VERSION ""

NS_ :

BS_:

BU_: IVI GTW IC HUD DVR WCM PDC VSP SVC TBOX_INFO SVM

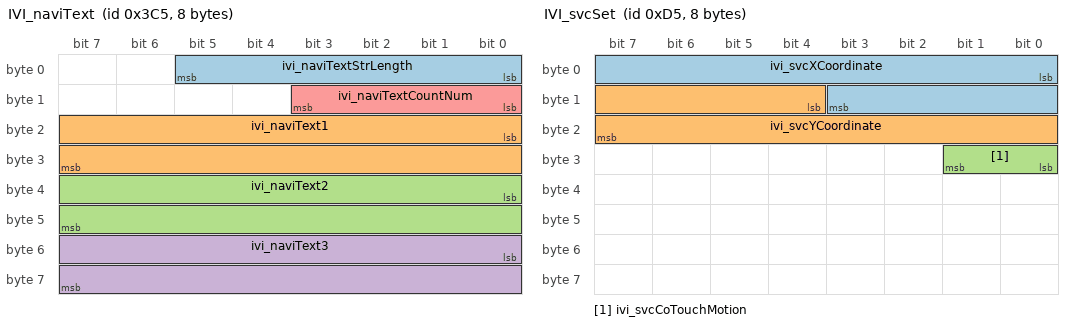
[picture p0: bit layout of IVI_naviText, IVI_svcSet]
BO_ 965 IVI_naviText: 8 IVI
 SG_ ivi_naviTextStrLength : 0|6@1+ (1,0) [0|63] ""  IC,HUD
 SG_ ivi_naviText1 : 16|16@1+ (1,0) [0|65535] ""  IC,HUD
 SG_ ivi_naviText2 : 32|16@1+ (1,0) [0|65535] ""  IC,HUD
 SG_ ivi_naviText3 : 48|16@1+ (1,0) [0|65535] ""  IC,HUD
 SG_ ivi_naviTextCountNum : 8|4@1+ (1,0) [0|15] ""  IC,HUD

BO_ 165 IVI_pwrSet: 8 IVI
 SG_ ivi_driveModeSet : 0|2@1+ (1,0) [0|3] ""  GTW
 SG_ ivi_travelModeSet : 13|3@1+ (1,0) [0|7] ""  GTW
 SG_ ivi_maxChrgSocSet : 16|8@1+ (0.5,0) [0|100] "%"  GTW
 SG_ ivi_4wdModeSet : 2|2@1+ (1,0) [0|3] ""  GTW
 SG_ ivi_cancelChargeSet : 24|2@1+ (1,0) [0|3] ""  GTW
 SG_ ivi_chargeFormSet : 26|3@1+ (1,0) [0|7] ""  GTW
 SG_ ivi_engyRcvrOnOffSet : 29|2@1+ (1,0) [0|3] ""  GTW
 SG_ ivi_engyRcvrIntensitySet : 32|2@1+ (1,0) [0|3] ""  GTW
 SG_ ivi_tractionModeSet : 34|1@1+ (1,0) [0|1] ""  GTW
 SG_ ivi_dcdcAutochargeSet : 35|1@1+ (1,0) [0|1] ""  GTW
 SG_ ivi_ASCHeightModeSelected : 36|3@1+ (1,0) [0|7] ""  GTW
 SG_ ivi_ASCSpeedChangeEnableSwitch : 39|1@1+ (1,0) [0|1] ""  GTW
 SG_ ivi_crawlModeSet : 4|2@1+ (1,0) [0|3] ""  GTW
 SG_ ivi_ASCSpeedThresholdValueChange : 40|8@1+ (1,0) [0|255] ""  GTW
 SG_ ivi_esc_epbButtonRelease : 48|1@1+ (1,0) [0|1] ""  GTW
 SG_ ivi_ASCMoveModeControl : 49|2@1+ (1,0) [0|3] ""  GTW
 SG_ ivi_enableCreepTorque : 51|1@1+ (1,0) [0|1] ""  GTW
 SG_ ivi_chargeModeSet : 6|2@1+ (1,0) [0|3] ""  GTW
 SG_ ivi_maxChargeCurrentSet : 8|5@1+ (1,5) [5|26] "A"  GTW

BO_ 245 IVI_scuSet: 8 IVI
 SG_ ivi_easyEntrySet : 0|2@1+ (1,0) [0|3] ""  GTW
 SG_ ivi_drSeatVentLevelSet : 11|3@1+ (1,0) [0|7] ""  GTW
 SG_ ivi_passSeatHeatOnOffSet : 14|2@1+ (1,0) [0|3] ""  GTW
 SG_ ivi_passSeatVentOnOffSet : 16|2@1+ (1,0) [0|3] ""  GTW
 SG_ ivi_passSeatHeatLevelSet : 18|3@1+ (1,0) [0|7] ""  GTW
 SG_ ivi_drSeatHeatOnOffSet : 2|2@1+ (1,0) [0|3] ""  GTW
 SG_ ivi_passSeatVentLevelSet : 21|3@1+ (1,0) [0|7] ""  GTW
 SG_ ivi_passSeatMassOnOffSet : 24|2@1+ (1,0) [0|3] ""  GTW
 SG_ ivi_drSeatMassLevelSet : 26|3@1+ (1,0) [0|7] ""  GTW
 SG_ ivi_passSeatMassLevelSet : 29|3@1+ (1,0) [0|7] ""  GTW
 SG_ ivi_mirrorSet : 32|2@1+ (1,0) [0|3] ""  GTW
 SG_ ivi_memorySet : 34|2@1+ (1,0) [0|3] ""  GTW
 SG_ ivi_memoryNumSet : 36|2@1+ (1,0) [0|3] ""  GTW
 SG_ ivi_drSeatVentOnOffSet : 4|2@1+ (1,0) [0|3] ""  GTW
 SG_ ivi_dsmSetMemoryReq : 40|3@1+ (1,0) [0|7] ""  GTW
 SG_ ivi_dsmGetMemoryReq : 43|3@1+ (1,0) [0|7] ""  GTW
 SG_ ivi_drSeatMassOnOffSet : 6|2@1+ (1,0) [0|3] ""  GTW
 SG_ ivi_drSeatHeatLevelSet : 8|3@1+ (1,0) [0|7] ""  GTW

BO_ 949 IVI_set: 8 IVI
 SG_ ivi_hvacDefrostMode : 0|1@1+ (1,0) [0|1] ""  GTW
 SG_ ivi_hvacOnOffReq : 1|1@1+ (1,0) [0|1] ""  GTW
 SG_ ivi_passengerTempFSet : 10|6@1+ (0.5,64) [64|89] "℉"  GTW
 SG_ ivi_hvacModeReq : 16|3@1+ (1,0) [0|7] ""  GTW
 SG_ ivi_driverTempCSet : 19|5@1+ (0.5,18) [18|32] "degreeC"  GTW
 SG_ ivi_driverTempFSet : 2|6@1+ (0.5,64) [64|89] "℉"  GTW
 SG_ ivi_hvacBlowLvReq : 24|3@1+ (1,0) [0|7] ""  GTW
 SG_ ivi_passengerTempCSet : 27|5@1+ (0.5,18) [18|32] "degreeC"  GTW
 SG_ ivi_hvacDualMode : 32|1@1+ (1,0) [0|1] ""  GTW
 SG_ ivi_hvacPTCReq : 33|1@1+ (1,0) [0|1] ""  GTW
 SG_ ivi_acReq : 34|1@1+ (1,0) [0|1] ""  GTW
 SG_ ivi_svcCameraModeSet : 35|4@1+ (1,0) [0|15] ""  SVC,GTW
 SG_ ivi_acDiagReq : 39|1@1+ (1,0) [0|1] ""  GTW
 SG_ ivi_svcFrontTrackDispSet : 40|1@1+ (1,0) [0|1] ""  SVC,GTW
 SG_ ivi_svcRvrsTrackDispSet : 41|1@1+ (1,0) [0|1] ""  SVC,GTW
 SG_ ivi_svcOutMirrorTrackDispSet : 42|1@1+ (1,0) [0|1] ""  SVC,GTW
 SG_ ivi_svcOnOffSw : 43|1@1+ (1,0) [0|1] ""  SVC,GTW
 SG_ ivi_svcSteerInteractionSet : 44|1@1+ (1,0) [0|1] ""  SVC,GTW
 SG_ ivi_languageSet : 48|4@1+ (1,0) [0|15] ""  IC,SVC,DVR,HUD,GTW
 SG_ ivi_unitSet : 52|2@1+ (1,0) [0|3] ""  IC,HUD,GTW
 SG_ ivi_hvacAutoModeReq : 8|1@1+ (1,0) [0|1] ""  GTW
 SG_ ivi_hvacRecircModeReq : 9|1@1+ (1,0) [0|1] ""  GTW

BO_ 229 IVI_svcCalib: 8 IVI
 SG_ ivi_svcCalibrateStart : 0|32@1+ (1,0) [0|4294967295] ""  SVC
 SG_ ivi_svcCaliInfoReq : 32|1@1+ (1,0) [0|1] ""  SVC

BO_ 213 IVI_svcSet: 8 IVI
 SG_ ivi_svcXCoordinate : 0|12@1+ (1,0) [0|1280] ""  SVC
 SG_ ivi_svcYCoordinate : 12|12@1+ (1,0) [0|720] ""  SVC
 SG_ ivi_svcCoTouchMotion : 24|2@1+ (1,0) [0|3] ""  SVC

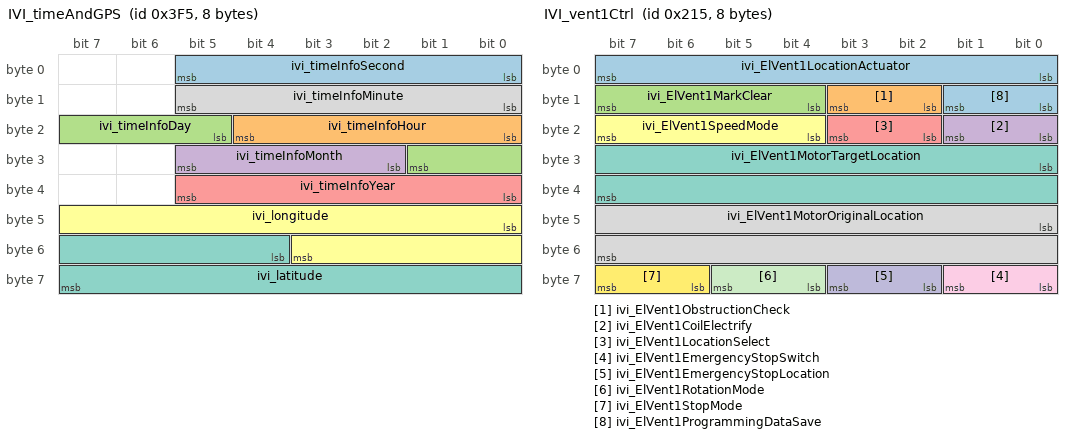
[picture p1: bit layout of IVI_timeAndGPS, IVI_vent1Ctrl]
BO_ 1013 IVI_timeAndGPS: 8 IVI
 SG_ ivi_timeInfoSecond : 0|6@1+ (1,0) [0|59] ""  IC,SVC,DVR
 SG_ ivi_timeInfoHour : 16|5@1+ (1,0) [0|23] ""  IC,SVC,DVR
 SG_ ivi_timeInfoDay : 21|5@1+ (1,0) [1|31] ""  IC,SVC,DVR
 SG_ ivi_timeInfoMonth : 26|4@1+ (1,0) [1|12] ""  IC,SVC,DVR
 SG_ ivi_timeInfoYear : 32|6@1+ (1,0) [0|59] ""  IC,SVC,DVR
 SG_ ivi_longitude : 40|12@1+ (0.1,-180) [-180|180] "degree"  DVR
 SG_ ivi_latitude : 52|12@1+ (0.1,-180) [-180|180] "degree"  DVR
 SG_ ivi_timeInfoMinute : 8|6@1+ (1,0) [0|59] ""  IC,SVC,DVR

BO_ 533 IVI_vent1Ctrl: 8 IVI
 SG_ ivi_ElVent1LocationActuator : 0|8@1+ (1,0) [0|255] ""  GTW
 SG_ ivi_ElVent1ObstructionCheck : 10|2@1+ (1,0) [0|3] ""  GTW
 SG_ ivi_ElVent1MarkClear : 12|4@1+ (1,0) [0|15] ""  GTW
 SG_ ivi_ElVent1CoilElectrify : 16|2@1+ (1,0) [0|3] ""  GTW
 SG_ ivi_ElVent1LocationSelect : 18|2@1+ (1,0) [0|3] ""  GTW
 SG_ ivi_ElVent1SpeedMode : 20|4@1+ (1,0) [0|15] ""  GTW
 SG_ ivi_ElVent1MotorTargetLocation : 24|16@1+ (1,0) [0|65535] ""  GTW
 SG_ ivi_ElVent1MotorOriginalLocation : 40|16@1+ (1,0) [0|65535] ""  GTW
 SG_ ivi_ElVent1EmergencyStopSwitch : 56|2@1+ (1,0) [0|3] ""  GTW
 SG_ ivi_ElVent1EmergencyStopLocation : 58|2@1+ (1,0) [0|3] ""  GTW
 SG_ ivi_ElVent1RotationMode : 60|2@1+ (1,0) [0|3] ""  GTW
 SG_ ivi_ElVent1StopMode : 62|2@1+ (1,0) [0|3] ""  GTW
 SG_ ivi_ElVent1ProgrammingDataSave : 8|2@1+ (1,0) [0|3] ""  GTW

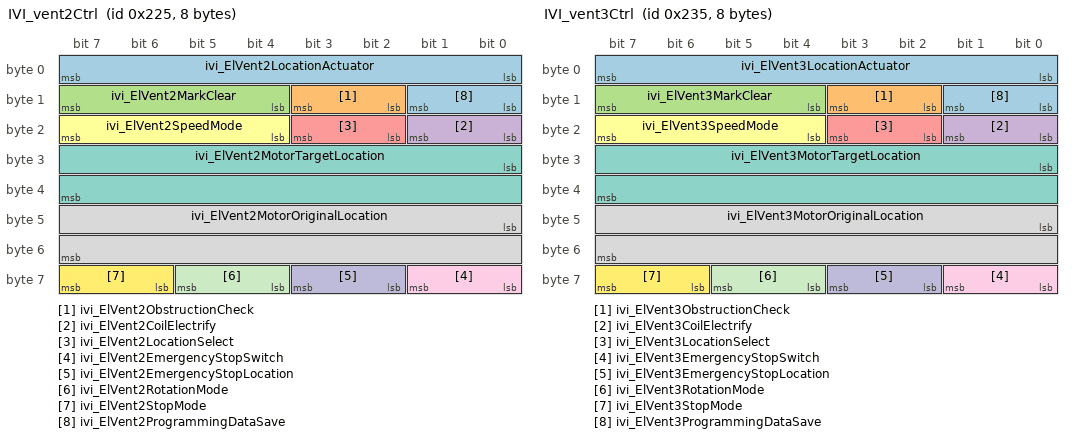
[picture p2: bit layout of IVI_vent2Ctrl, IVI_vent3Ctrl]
BO_ 549 IVI_vent2Ctrl: 8 IVI
 SG_ ivi_ElVent2LocationActuator : 0|8@1+ (1,0) [0|255] ""  GTW
 SG_ ivi_ElVent2ObstructionCheck : 10|2@1+ (1,0) [0|3] ""  GTW
 SG_ ivi_ElVent2MarkClear : 12|4@1+ (1,0) [0|15] ""  GTW
 SG_ ivi_ElVent2CoilElectrify : 16|2@1+ (1,0) [0|3] ""  GTW
 SG_ ivi_ElVent2LocationSelect : 18|2@1+ (1,0) [0|3] ""  GTW
 SG_ ivi_ElVent2SpeedMode : 20|4@1+ (1,0) [0|15] ""  GTW
 SG_ ivi_ElVent2MotorTargetLocation : 24|16@1+ (1,0) [0|65535] ""  GTW
 SG_ ivi_ElVent2MotorOriginalLocation : 40|16@1+ (1,0) [0|65535] ""  GTW
 SG_ ivi_ElVent2EmergencyStopSwitch : 56|2@1+ (1,0) [0|3] ""  GTW
 SG_ ivi_ElVent2EmergencyStopLocation : 58|2@1+ (1,0) [0|3] ""  GTW
 SG_ ivi_ElVent2RotationMode : 60|2@1+ (1,0) [0|3] ""  GTW
 SG_ ivi_ElVent2StopMode : 62|2@1+ (1,0) [0|3] ""  GTW
 SG_ ivi_ElVent2ProgrammingDataSave : 8|2@1+ (1,0) [0|3] ""  GTW

BO_ 565 IVI_vent3Ctrl: 8 IVI
 SG_ ivi_ElVent3LocationActuator : 0|8@1+ (1,0) [0|255] ""  GTW
 SG_ ivi_ElVent3ObstructionCheck : 10|2@1+ (1,0) [0|3] ""  GTW
 SG_ ivi_ElVent3MarkClear : 12|4@1+ (1,0) [0|15] ""  GTW
 SG_ ivi_ElVent3CoilElectrify : 16|2@1+ (1,0) [0|3] ""  GTW
 SG_ ivi_ElVent3LocationSelect : 18|2@1+ (1,0) [0|3] ""  GTW
 SG_ ivi_ElVent3SpeedMode : 20|4@1+ (1,0) [0|15] ""  GTW
 SG_ ivi_ElVent3MotorTargetLocation : 24|16@1+ (1,0) [0|65535] ""  GTW
 SG_ ivi_ElVent3MotorOriginalLocation : 40|16@1+ (1,0) [0|65535] ""  GTW
 SG_ ivi_ElVent3EmergencyStopSwitch : 56|2@1+ (1,0) [0|3] ""  GTW
 SG_ ivi_ElVent3EmergencyStopLocation : 58|2@1+ (1,0) [0|3] ""  GTW
 SG_ ivi_ElVent3RotationMode : 60|2@1+ (1,0) [0|3] ""  GTW
 SG_ ivi_ElVent3StopMode : 62|2@1+ (1,0) [0|3] ""  GTW
 SG_ ivi_ElVent3ProgrammingDataSave : 8|2@1+ (1,0) [0|3] ""  GTW

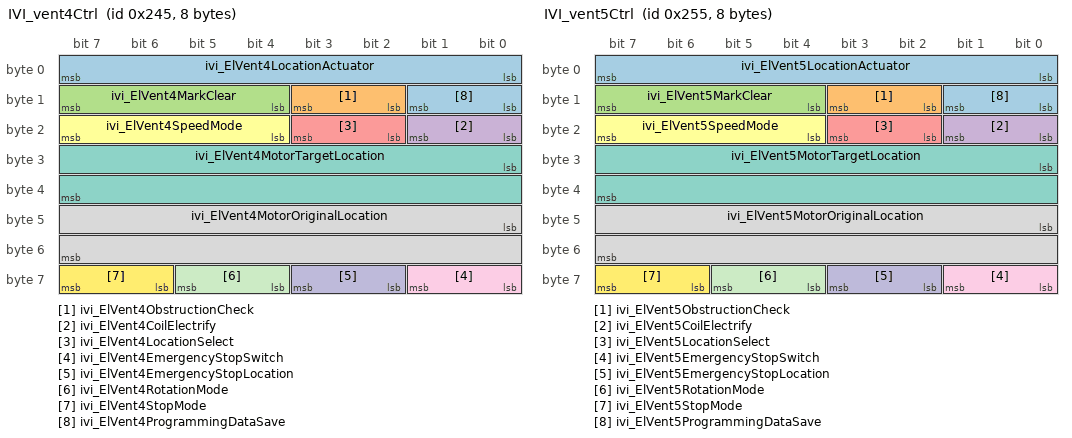
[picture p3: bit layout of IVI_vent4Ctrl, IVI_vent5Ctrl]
BO_ 581 IVI_vent4Ctrl: 8 IVI
 SG_ ivi_ElVent4LocationActuator : 0|8@1+ (1,0) [0|255] ""  GTW
 SG_ ivi_ElVent4ObstructionCheck : 10|2@1+ (1,0) [0|3] ""  GTW
 SG_ ivi_ElVent4MarkClear : 12|4@1+ (1,0) [0|15] ""  GTW
 SG_ ivi_ElVent4CoilElectrify : 16|2@1+ (1,0) [0|3] ""  GTW
 SG_ ivi_ElVent4LocationSelect : 18|2@1+ (1,0) [0|3] ""  GTW
 SG_ ivi_ElVent4SpeedMode : 20|4@1+ (1,0) [0|15] ""  GTW
 SG_ ivi_ElVent4MotorTargetLocation : 24|16@1+ (1,0) [0|65535] ""  GTW
 SG_ ivi_ElVent4MotorOriginalLocation : 40|16@1+ (1,0) [0|65535] ""  GTW
 SG_ ivi_ElVent4EmergencyStopSwitch : 56|2@1+ (1,0) [0|3] ""  GTW
 SG_ ivi_ElVent4EmergencyStopLocation : 58|2@1+ (1,0) [0|3] ""  GTW
 SG_ ivi_ElVent4RotationMode : 60|2@1+ (1,0) [0|3] ""  GTW
 SG_ ivi_ElVent4StopMode : 62|2@1+ (1,0) [0|3] ""  GTW
 SG_ ivi_ElVent4ProgrammingDataSave : 8|2@1+ (1,0) [0|3] ""  GTW

BO_ 597 IVI_vent5Ctrl: 8 IVI
 SG_ ivi_ElVent5LocationActuator : 0|8@1+ (1,0) [0|255] ""  GTW
 SG_ ivi_ElVent5ObstructionCheck : 10|2@1+ (1,0) [0|3] ""  GTW
 SG_ ivi_ElVent5MarkClear : 12|4@1+ (1,0) [0|15] ""  GTW
 SG_ ivi_ElVent5CoilElectrify : 16|2@1+ (1,0) [0|3] ""  GTW
 SG_ ivi_ElVent5LocationSelect : 18|2@1+ (1,0) [0|3] ""  GTW
 SG_ ivi_ElVent5SpeedMode : 20|4@1+ (1,0) [0|15] ""  GTW
 SG_ ivi_ElVent5MotorTargetLocation : 24|16@1+ (1,0) [0|65535] ""  GTW
 SG_ ivi_ElVent5MotorOriginalLocation : 40|16@1+ (1,0) [0|65535] ""  GTW
 SG_ ivi_ElVent5EmergencyStopSwitch : 56|2@1+ (1,0) [0|3] ""  GTW
 SG_ ivi_ElVent5EmergencyStopLocation : 58|2@1+ (1,0) [0|3] ""  GTW
 SG_ ivi_ElVent5RotationMode : 60|2@1+ (1,0) [0|3] ""  GTW
 SG_ ivi_ElVent5StopMode : 62|2@1+ (1,0) [0|3] ""  GTW
 SG_ ivi_ElVent5ProgrammingDataSave : 8|2@1+ (1,0) [0|3] ""  GTW

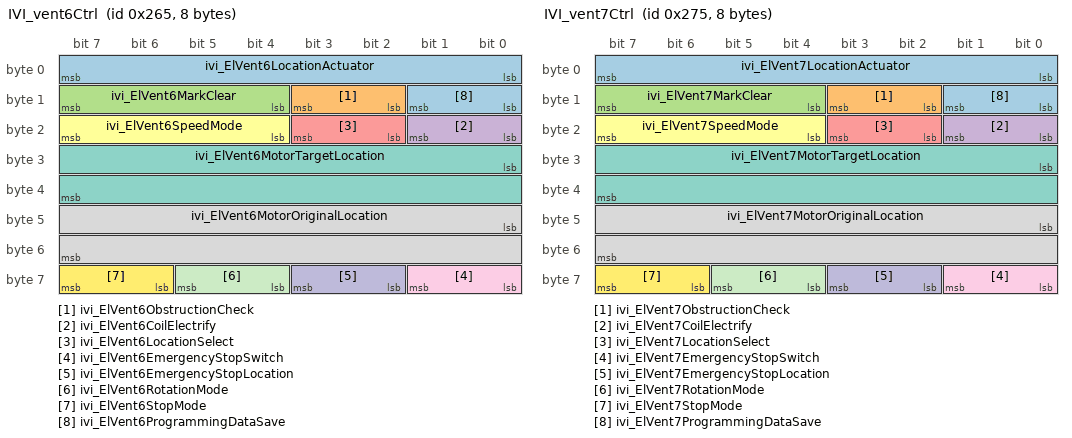
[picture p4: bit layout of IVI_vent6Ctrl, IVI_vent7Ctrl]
BO_ 613 IVI_vent6Ctrl: 8 IVI
 SG_ ivi_ElVent6LocationActuator : 0|8@1+ (1,0) [0|255] ""  GTW
 SG_ ivi_ElVent6ObstructionCheck : 10|2@1+ (1,0) [0|3] ""  GTW
 SG_ ivi_ElVent6MarkClear : 12|4@1+ (1,0) [0|15] ""  GTW
 SG_ ivi_ElVent6CoilElectrify : 16|2@1+ (1,0) [0|3] ""  GTW
 SG_ ivi_ElVent6LocationSelect : 18|2@1+ (1,0) [0|3] ""  GTW
 SG_ ivi_ElVent6SpeedMode : 20|4@1+ (1,0) [0|15] ""  GTW
 SG_ ivi_ElVent6MotorTargetLocation : 24|16@1+ (1,0) [0|65535] ""  GTW
 SG_ ivi_ElVent6MotorOriginalLocation : 40|16@1+ (1,0) [0|65535] ""  GTW
 SG_ ivi_ElVent6EmergencyStopSwitch : 56|2@1+ (1,0) [0|3] ""  GTW
 SG_ ivi_ElVent6EmergencyStopLocation : 58|2@1+ (1,0) [0|3] ""  GTW
 SG_ ivi_ElVent6RotationMode : 60|2@1+ (1,0) [0|3] ""  GTW
 SG_ ivi_ElVent6StopMode : 62|2@1+ (1,0) [0|3] ""  GTW
 SG_ ivi_ElVent6ProgrammingDataSave : 8|2@1+ (1,0) [0|3] ""  GTW

BO_ 629 IVI_vent7Ctrl: 8 IVI
 SG_ ivi_ElVent7LocationActuator : 0|8@1+ (1,0) [0|255] ""  GTW
 SG_ ivi_ElVent7ObstructionCheck : 10|2@1+ (1,0) [0|3] ""  GTW
 SG_ ivi_ElVent7MarkClear : 12|4@1+ (1,0) [0|15] ""  GTW
 SG_ ivi_ElVent7CoilElectrify : 16|2@1+ (1,0) [0|3] ""  GTW
 SG_ ivi_ElVent7LocationSelect : 18|2@1+ (1,0) [0|3] ""  GTW
 SG_ ivi_ElVent7SpeedMode : 20|4@1+ (1,0) [0|15] ""  GTW
 SG_ ivi_ElVent7MotorTargetLocation : 24|16@1+ (1,0) [0|65535] ""  GTW
 SG_ ivi_ElVent7MotorOriginalLocation : 40|16@1+ (1,0) [0|65535] ""  GTW
 SG_ ivi_ElVent7EmergencyStopSwitch : 56|2@1+ (1,0) [0|3] ""  GTW
 SG_ ivi_ElVent7EmergencyStopLocation : 58|2@1+ (1,0) [0|3] ""  GTW
 SG_ ivi_ElVent7RotationMode : 60|2@1+ (1,0) [0|3] ""  GTW
 SG_ ivi_ElVent7StopMode : 62|2@1+ (1,0) [0|3] ""  GTW
 SG_ ivi_ElVent7ProgrammingDataSave : 8|2@1+ (1,0) [0|3] ""  GTW

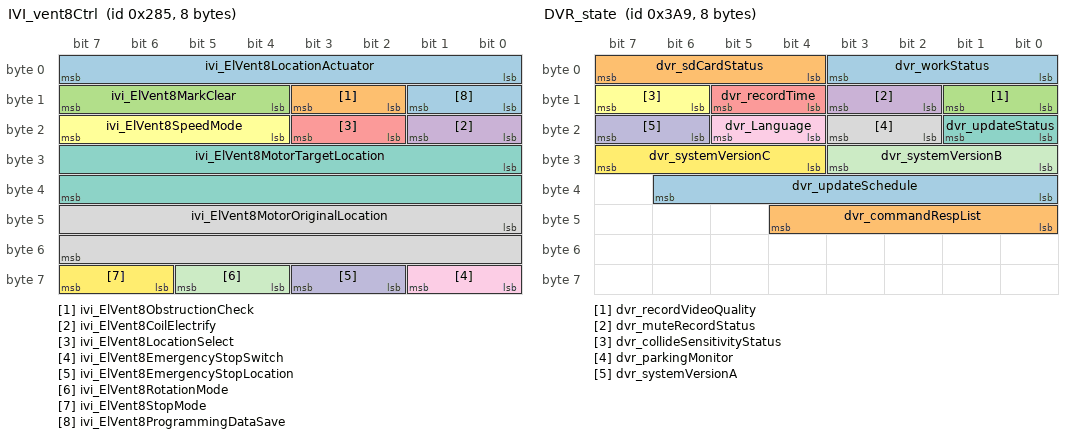
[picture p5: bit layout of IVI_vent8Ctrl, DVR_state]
BO_ 645 IVI_vent8Ctrl: 8 IVI
 SG_ ivi_ElVent8LocationActuator : 0|8@1+ (1,0) [0|255] ""  GTW
 SG_ ivi_ElVent8ObstructionCheck : 10|2@1+ (1,0) [0|3] ""  GTW
 SG_ ivi_ElVent8MarkClear : 12|4@1+ (1,0) [0|15] ""  GTW
 SG_ ivi_ElVent8CoilElectrify : 16|2@1+ (1,0) [0|3] ""  GTW
 SG_ ivi_ElVent8LocationSelect : 18|2@1+ (1,0) [0|3] ""  GTW
 SG_ ivi_ElVent8SpeedMode : 20|4@1+ (1,0) [0|15] ""  GTW
 SG_ ivi_ElVent8MotorTargetLocation : 24|16@1+ (1,0) [0|65535] ""  GTW
 SG_ ivi_ElVent8MotorOriginalLocation : 40|16@1+ (1,0) [0|65535] ""  GTW
 SG_ ivi_ElVent8EmergencyStopSwitch : 56|2@1+ (1,0) [0|3] ""  GTW
 SG_ ivi_ElVent8EmergencyStopLocation : 58|2@1+ (1,0) [0|3] ""  GTW
 SG_ ivi_ElVent8RotationMode : 60|2@1+ (1,0) [0|3] ""  GTW
 SG_ ivi_ElVent8StopMode : 62|2@1+ (1,0) [0|3] ""  GTW
 SG_ ivi_ElVent8ProgrammingDataSave : 8|2@1+ (1,0) [0|3] ""  GTW

BO_ 937 DVR_state: 8 DVR
 SG_ dvr_workStatus : 0|4@1+ (1,0) [0|15] ""  IVI
 SG_ dvr_sdCardStatus : 4|4@1+ (1,0) [0|15] ""  IVI
 SG_ dvr_recordVideoQuality : 8|2@1+ (1,0) [0|3] ""  IVI
 SG_ dvr_muteRecordStatus : 10|2@1+ (1,0) [0|3] ""  IVI
 SG_ dvr_recordTime : 12|2@1+ (1,0) [0|3] ""  IVI
 SG_ dvr_collideSensitivityStatus : 14|2@1+ (1,0) [0|3] ""  IVI
 SG_ dvr_updateStatus : 16|2@1+ (1,0) [0|3] ""  IVI
 SG_ dvr_parkingMonitor : 18|2@1+ (1,0) [0|3] ""  IVI
 SG_ dvr_Language : 20|2@1+ (1,0) [0|3] ""  IVI
 SG_ dvr_systemVersionA : 22|2@1+ (1,0) [0|3] ""  IVI
 SG_ dvr_systemVersionB : 24|4@1+ (1,0) [0|9] ""  IVI
 SG_ dvr_systemVersionC : 28|4@1+ (1,0) [0|9] ""  IVI
 SG_ dvr_updateSchedule : 32|7@1+ (1,0) [0|127] ""  IVI
 SG_ dvr_commandRespList : 40|5@1+ (1,0) [0|31] ""  IVI

BO_ 1829 Diag_PhyReq_IVI: 8 GTW
 SG_ Diag_PhyReq_IVI_Data : 0|64@1+ (1,0) [0|0] "N/A"  IVI

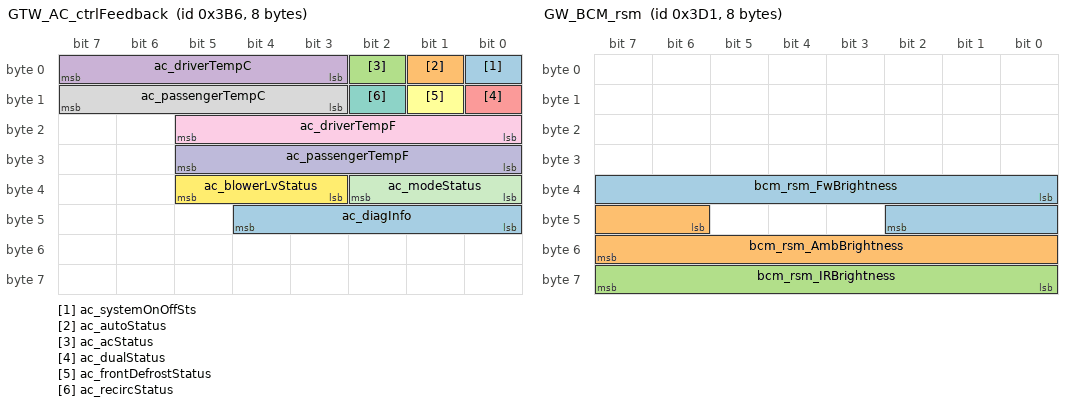
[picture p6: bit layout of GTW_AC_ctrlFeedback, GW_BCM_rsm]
BO_ 950 GTW_AC_ctrlFeedback: 8 GTW
 SG_ ac_systemOnOffSts : 0|1@1+ (1,0) [0|1] ""  IVI
 SG_ ac_autoStatus : 1|1@1+ (1,0) [0|1] ""  IVI
 SG_ ac_acStatus : 2|1@1+ (1,0) [0|1] ""  IVI
 SG_ ac_driverTempC : 3|5@1+ (0.5,18) [18|32] "degreeC"  IVI
 SG_ ac_dualStatus : 8|1@1+ (1,0) [0|1] ""  IVI
 SG_ ac_frontDefrostStatus : 9|1@1+ (1,0) [0|1] ""  IVI
 SG_ ac_recircStatus : 10|1@1+ (1,0) [0|1] ""  IVI
 SG_ ac_passengerTempC : 11|5@1+ (0.5,18) [18|32] "degreeC"  IVI
 SG_ ac_driverTempF : 16|6@1+ (0.5,64) [64|89] "℉"  IVI
 SG_ ac_passengerTempF : 24|6@1+ (0.5,64) [64|89] "℉"  IVI
 SG_ ac_modeStatus : 32|3@1+ (1,0) [0|7] ""  IVI
 SG_ ac_blowerLvStatus : 35|3@1+ (1,0) [0|7] ""  IVI
 SG_ ac_diagInfo : 40|5@1+ (1,0) [0|31] ""  IVI

BO_ 529 GTW_BCM_vent1Sts: 8 GTW
 SG_ bcm_ElVent1ErrorStatus : 0|1@1+ (1,0) [0|1] ""  IVI
 SG_ bcm_ElVent1OverHeatStatus : 2|2@1+ (1,0) [0|3] ""  IVI
 SG_ bcm_ElVent1ElectricalFailureSts : 4|2@1+ (1,0) [0|3] ""  IVI
 SG_ bcm_ElVent1VoltageStatus : 6|2@1+ (1,0) [0|3] ""  IVI
 SG_ bcm_ElVent1EmergencyRunningSts : 8|2@1+ (1,0) [0|3] ""  IVI
 SG_ bcm_ElVent1ObstructionDetect : 10|2@1+ (1,0) [0|3] ""  IVI
 SG_ bcm_ElVent1ObstructionStatus : 12|2@1+ (1,0) [0|3] ""  IVI
 SG_ bcm_ElVent1ResetStatus : 14|2@1+ (1,0) [0|3] ""  IVI
 SG_ bcm_ElVent1CoilStatus : 16|2@1+ (1,0) [0|3] ""  IVI
 SG_ bcm_ElVent1LocationStatus : 18|2@1+ (1,0) [0|3] ""  IVI
 SG_ bcm_ElVent1SpeedStatus : 20|4@1+ (1,0) [0|15] ""  IVI
 SG_ bcm_ElVent1MotorCurrentLocation : 24|16@1+ (1,0) [0|65535] ""  IVI
 SG_ bcm_ElVent1MotorDrivingDirection : 40|2@1+ (1,0) [0|3] ""  IVI
 SG_ bcm_ElVent1TorqueKeepingSts : 42|2@1+ (1,0) [0|3] ""  IVI
 SG_ bcm_ElVent1SpecialFunction : 44|2@1+ (1,0) [0|3] ""  IVI
 SG_ bcm_ElVent1LocationActuator : 48|8@1+ (1,0) [0|255] ""  IVI
 SG_ bcm_ElVent1EmengencyStopSwitchSt : 56|2@1+ (1,0) [0|3] ""  IVI
 SG_ bcm_ElVent1EmengencyStopSLocatio : 58|2@1+ (1,0) [0|3] ""  IVI
 SG_ bcm_ElVent1RotationMode : 60|2@1+ (1,0) [0|3] ""  IVI
 SG_ bcm_ElVent1StopStatus : 62|2@1+ (1,0) [0|3] ""  IVI

BO_ 545 GTW_BCM_vent2Sts: 8 GTW
 SG_ bcm_ElVent2ErrorStatus : 0|1@1+ (1,0) [0|1] ""  IVI
 SG_ bcm_ElVent2OverHeatStatus : 2|2@1+ (1,0) [0|3] ""  IVI
 SG_ bcm_ElVent2ElectricalFailureSts : 4|2@1+ (1,0) [0|3] ""  IVI
 SG_ bcm_ElVent2VoltageStatus : 6|2@1+ (1,0) [0|3] ""  IVI
 SG_ bcm_ElVent2EmergencyRunningSts : 8|2@1+ (1,0) [0|3] ""  IVI
 SG_ bcm_ElVent2ObstructionDetect : 10|2@1+ (1,0) [0|3] ""  IVI
 SG_ bcm_ElVent2ObstructionStatus : 12|2@1+ (1,0) [0|3] ""  IVI
 SG_ bcm_ElVent2ResetStatus : 14|2@1+ (1,0) [0|3] ""  IVI
 SG_ bcm_ElVent2CoilStatus : 16|2@1+ (1,0) [0|3] ""  IVI
 SG_ bcm_ElVent2LocationStatus : 18|2@1+ (1,0) [0|3] ""  IVI
 SG_ bcm_ElVent2SpeedStatus : 20|4@1+ (1,0) [0|15] ""  IVI
 SG_ bcm_ElVent2MotorCurrentLocation : 24|16@1+ (1,0) [0|65535] ""  IVI
 SG_ bcm_ElVent2MotorDrivingDirection : 40|2@1+ (1,0) [0|3] ""  IVI
 SG_ bcm_ElVent2TorqueKeepingSts : 42|2@1+ (1,0) [0|3] ""  IVI
 SG_ bcm_ElVent2SpecialFunction : 44|2@1+ (1,0) [0|3] ""  IVI
 SG_ bcm_ElVent2LocationActuator : 48|8@1+ (1,0) [0|255] ""  IVI
 SG_ bcm_ElVent2EmengencyStopSwitchSt : 56|2@1+ (1,0) [0|3] ""  IVI
 SG_ bcm_ElVent2EmengencyStopSLocatio : 58|2@1+ (1,0) [0|3] ""  IVI
 SG_ bcm_ElVent2RotationMode : 60|2@1+ (1,0) [0|3] ""  IVI
 SG_ bcm_ElVent2StopStatus : 62|2@1+ (1,0) [0|3] ""  IVI

BO_ 561 GTW_BCM_vent3Sts: 8 GTW
 SG_ bcm_ElVent3ErrorStatus : 0|1@1+ (1,0) [0|1] ""  IVI
 SG_ bcm_ElVent3OverHeatStatus : 2|2@1+ (1,0) [0|3] ""  IVI
 SG_ bcm_ElVent3ElectricalFailureSts : 4|2@1+ (1,0) [0|3] ""  IVI
 SG_ bcm_ElVent3VoltageStatus : 6|2@1+ (1,0) [0|3] ""  IVI
 SG_ bcm_ElVent3EmergencyRunningSts : 8|2@1+ (1,0) [0|3] ""  IVI
 SG_ bcm_ElVent3ObstructionDetect : 10|2@1+ (1,0) [0|3] ""  IVI
 SG_ bcm_ElVent3ObstructionStatus : 12|2@1+ (1,0) [0|3] ""  IVI
 SG_ bcm_ElVent3ResetStatus : 14|2@1+ (1,0) [0|3] ""  IVI
 SG_ bcm_ElVent3CoilStatus : 16|2@1+ (1,0) [0|3] ""  IVI
 SG_ bcm_ElVent3LocationStatus : 18|2@1+ (1,0) [0|3] ""  IVI
 SG_ bcm_ElVent3SpeedStatus : 20|4@1+ (1,0) [0|15] ""  IVI
 SG_ bcm_ElVent3MotorCurrentLocation : 24|16@1+ (1,0) [0|65535] ""  IVI
 SG_ bcm_ElVent3MotorDrivingDirection : 40|2@1+ (1,0) [0|3] ""  IVI
 SG_ bcm_ElVent3TorqueKeepingSts : 42|2@1+ (1,0) [0|3] ""  IVI
 SG_ bcm_ElVent3SpecialFunction : 44|2@1+ (1,0) [0|3] ""  IVI
 SG_ bcm_ElVent3LocationActuator : 48|8@1+ (1,0) [0|255] ""  IVI
 SG_ bcm_ElVent3EmengencyStopSwitchSt : 56|2@1+ (1,0) [0|3] ""  IVI
 SG_ bcm_ElVent3EmengencyStopSLocatio : 58|2@1+ (1,0) [0|3] ""  IVI
 SG_ bcm_ElVent3RotationMode : 60|2@1+ (1,0) [0|3] ""  IVI
 SG_ bcm_ElVent3StopStatus : 62|2@1+ (1,0) [0|3] ""  IVI

BO_ 577 GTW_BCM_vent4Sts: 8 GTW
 SG_ bcm_ElVent4ErrorStatus : 0|1@1+ (1,0) [0|1] ""  IVI
 SG_ bcm_ElVent4OverHeatStatus : 2|2@1+ (1,0) [0|3] ""  IVI
 SG_ bcm_ElVent4ElectricalFailureSts : 4|2@1+ (1,0) [0|3] ""  IVI
 SG_ bcm_ElVent4VoltageStatus : 6|2@1+ (1,0) [0|3] ""  IVI
 SG_ bcm_ElVent4EmergencyRunningSts : 8|2@1+ (1,0) [0|3] ""  IVI
 SG_ bcm_ElVent4ObstructionDetect : 10|2@1+ (1,0) [0|3] ""  IVI
 SG_ bcm_ElVent4ObstructionStatus : 12|2@1+ (1,0) [0|3] ""  IVI
 SG_ bcm_ElVent4ResetStatus : 14|2@1+ (1,0) [0|3] ""  IVI
 SG_ bcm_ElVent4CoilStatus : 16|2@1+ (1,0) [0|3] ""  IVI
 SG_ bcm_ElVent4LocationStatus : 18|2@1+ (1,0) [0|3] ""  IVI
 SG_ bcm_ElVent4SpeedStatus : 20|4@1+ (1,0) [0|15] ""  IVI
 SG_ bcm_ElVent4MotorCurrentLocation : 24|16@1+ (1,0) [0|65535] ""  IVI
 SG_ bcm_ElVent4MotorDrivingDirection : 40|2@1+ (1,0) [0|3] ""  IVI
 SG_ bcm_ElVent4TorqueKeepingSts : 42|2@1+ (1,0) [0|3] ""  IVI
 SG_ bcm_ElVent4SpecialFunction : 44|2@1+ (1,0) [0|3] ""  IVI
 SG_ bcm_ElVent4LocationActuator : 48|8@1+ (1,0) [0|255] ""  IVI
 SG_ bcm_ElVent4EmengencyStopSwitchSt : 56|2@1+ (1,0) [0|3] ""  IVI
 SG_ bcm_ElVent4EmengencyStopSLocatio : 58|2@1+ (1,0) [0|3] ""  IVI
 SG_ bcm_ElVent4RotationMode : 60|2@1+ (1,0) [0|3] ""  IVI
 SG_ bcm_ElVent4StopStatus : 62|2@1+ (1,0) [0|3] ""  IVI

BO_ 593 GTW_BCM_vent5Sts: 8 GTW
 SG_ bcm_ElVent5ErrorStatus : 0|1@1+ (1,0) [0|1] ""  IVI
 SG_ bcm_ElVent5OverHeatStatus : 2|2@1+ (1,0) [0|3] ""  IVI
 SG_ bcm_ElVent5ElectricalFailureSts : 4|2@1+ (1,0) [0|3] ""  IVI
 SG_ bcm_ElVent5VoltageStatus : 6|2@1+ (1,0) [0|3] ""  IVI
 SG_ bcm_ElVent5EmergencyRunningSts : 8|2@1+ (1,0) [0|3] ""  IVI
 SG_ bcm_ElVent5ObstructionDetect : 10|2@1+ (1,0) [0|3] ""  IVI
 SG_ bcm_ElVent5ObstructionStatus : 12|2@1+ (1,0) [0|3] ""  IVI
 SG_ bcm_ElVent5ResetStatus : 14|2@1+ (1,0) [0|3] ""  IVI
 SG_ bcm_ElVent5CoilStatus : 16|2@1+ (1,0) [0|3] ""  IVI
 SG_ bcm_ElVent5LocationStatus : 18|2@1+ (1,0) [0|3] ""  IVI
 SG_ bcm_ElVent5SpeedStatus : 20|4@1+ (1,0) [0|15] ""  IVI
 SG_ bcm_ElVent5MotorCurrentLocation : 24|16@1+ (1,0) [0|65535] ""  IVI
 SG_ bcm_ElVent5MotorDrivingDirection : 40|2@1+ (1,0) [0|3] ""  IVI
 SG_ bcm_ElVent5TorqueKeepingSts : 42|2@1+ (1,0) [0|3] ""  IVI
 SG_ bcm_ElVent5SpecialFunction : 44|2@1+ (1,0) [0|3] ""  IVI
 SG_ bcm_ElVent5LocationActuator : 48|8@1+ (1,0) [0|255] ""  IVI
 SG_ bcm_ElVent5EmengencyStopSwitchSt : 56|2@1+ (1,0) [0|3] ""  IVI
 SG_ bcm_ElVent5EmengencyStopSLocatio : 58|2@1+ (1,0) [0|3] ""  IVI
 SG_ bcm_ElVent5RotationMode : 60|2@1+ (1,0) [0|3] ""  IVI
 SG_ bcm_ElVent5StopStatus : 62|2@1+ (1,0) [0|3] ""  IVI

BO_ 609 GTW_BCM_vent6Sts: 8 GTW
 SG_ bcm_ElVent6ErrorStatus : 0|1@1+ (1,0) [0|1] ""  IVI
 SG_ bcm_ElVent6OverHeatStatus : 2|2@1+ (1,0) [0|3] ""  IVI
 SG_ bcm_ElVent6ElectricalFailureSts : 4|2@1+ (1,0) [0|3] ""  IVI
 SG_ bcm_ElVent6VoltageStatus : 6|2@1+ (1,0) [0|3] ""  IVI
 SG_ bcm_ElVent6EmergencyRunningSts : 8|2@1+ (1,0) [0|3] ""  IVI
 SG_ bcm_ElVent6ObstructionDetect : 10|2@1+ (1,0) [0|3] ""  IVI
 SG_ bcm_ElVent6ObstructionStatus : 12|2@1+ (1,0) [0|3] ""  IVI
 SG_ bcm_ElVent6ResetStatus : 14|2@1+ (1,0) [0|3] ""  IVI
 SG_ bcm_ElVent6CoilStatus : 16|2@1+ (1,0) [0|3] ""  IVI
 SG_ bcm_ElVent6LocationStatus : 18|2@1+ (1,0) [0|3] ""  IVI
 SG_ bcm_ElVent6SpeedStatus : 20|4@1+ (1,0) [0|15] ""  IVI
 SG_ bcm_ElVent6MotorCurrentLocation : 24|16@1+ (1,0) [0|65535] ""  IVI
 SG_ bcm_ElVent6MotorDrivingDirection : 40|2@1+ (1,0) [0|3] ""  IVI
 SG_ bcm_ElVent6TorqueKeepingSts : 42|2@1+ (1,0) [0|3] ""  IVI
 SG_ bcm_ElVent6SpecialFunction : 44|2@1+ (1,0) [0|3] ""  IVI
 SG_ bcm_ElVent6LocationActuator : 48|8@1+ (1,0) [0|255] ""  IVI
 SG_ bcm_ElVent6EmengencyStopSwitchSt : 56|2@1+ (1,0) [0|3] ""  IVI
 SG_ bcm_ElVent6EmengencyStopSLocatio : 58|2@1+ (1,0) [0|3] ""  IVI
 SG_ bcm_ElVent6RotationMode : 60|2@1+ (1,0) [0|3] ""  IVI
 SG_ bcm_ElVent6StopStatus : 62|2@1+ (1,0) [0|3] ""  IVI

BO_ 625 GTW_BCM_vent7Sts: 8 GTW
 SG_ bcm_ElVent7ErrorStatus : 0|1@1+ (1,0) [0|1] ""  IVI
 SG_ bcm_ElVent7OverHeatStatus : 2|2@1+ (1,0) [0|3] ""  IVI
 SG_ bcm_ElVent7ElectricalFailureSts : 4|2@1+ (1,0) [0|3] ""  IVI
 SG_ bcm_ElVent7VoltageStatus : 6|2@1+ (1,0) [0|3] ""  IVI
 SG_ bcm_ElVent7EmergencyRunningSts : 8|2@1+ (1,0) [0|3] ""  IVI
 SG_ bcm_ElVent7ObstructionDetect : 10|2@1+ (1,0) [0|3] ""  IVI
 SG_ bcm_ElVent7ObstructionStatus : 12|2@1+ (1,0) [0|3] ""  IVI
 SG_ bcm_ElVent7ResetStatus : 14|2@1+ (1,0) [0|3] ""  IVI
 SG_ bcm_ElVent7CoilStatus : 16|2@1+ (1,0) [0|3] ""  IVI
 SG_ bcm_ElVent7LocationStatus : 18|2@1+ (1,0) [0|3] ""  IVI
 SG_ bcm_ElVent7SpeedStatus : 20|4@1+ (1,0) [0|15] ""  IVI
 SG_ bcm_ElVent7MotorCurrentLocation : 24|16@1+ (1,0) [0|65535] ""  IVI
 SG_ bcm_ElVent7MotorDrivingDirection : 40|2@1+ (1,0) [0|3] ""  IVI
 SG_ bcm_ElVent7TorqueKeepingSts : 42|2@1+ (1,0) [0|3] ""  IVI
 SG_ bcm_ElVent7SpecialFunction : 44|2@1+ (1,0) [0|3] ""  IVI
 SG_ bcm_ElVent7LocationActuator : 48|8@1+ (1,0) [0|255] ""  IVI
 SG_ bcm_ElVent7EmengencyStopSwitchSt : 56|2@1+ (1,0) [0|3] ""  IVI
 SG_ bcm_ElVent7EmengencyStopSLocatio : 58|2@1+ (1,0) [0|3] ""  IVI
 SG_ bcm_ElVent7RotationMode : 60|2@1+ (1,0) [0|3] ""  IVI
 SG_ bcm_ElVent7StopStatus : 62|2@1+ (1,0) [0|3] ""  IVI

BO_ 641 GTW_BCM_vent8Sts: 8 GTW
 SG_ bcm_ElVent8ErrorStatus : 0|1@1+ (1,0) [0|1] ""  IVI
 SG_ bcm_ElVent8OverHeatStatus : 2|2@1+ (1,0) [0|3] ""  IVI
 SG_ bcm_ElVent8ElectricalFailureSts : 4|2@1+ (1,0) [0|3] ""  IVI
 SG_ bcm_ElVent8VoltageStatus : 6|2@1+ (1,0) [0|3] ""  IVI
 SG_ bcm_ElVent8EmergencyRunningSts : 8|2@1+ (1,0) [0|3] ""  IVI
 SG_ bcm_ElVent8ObstructionDetect : 10|2@1+ (1,0) [0|3] ""  IVI
 SG_ bcm_ElVent8ObstructionStatus : 12|2@1+ (1,0) [0|3] ""  IVI
 SG_ bcm_ElVent8ResetStatus : 14|2@1+ (1,0) [0|3] ""  IVI
 SG_ bcm_ElVent8CoilStatus : 16|2@1+ (1,0) [0|3] ""  IVI
 SG_ bcm_ElVent8LocationStatus : 18|2@1+ (1,0) [0|3] ""  IVI
 SG_ bcm_ElVent8SpeedStatus : 20|4@1+ (1,0) [0|15] ""  IVI
 SG_ bcm_ElVent8MotorCurrentLocation : 24|16@1+ (1,0) [0|65535] ""  IVI
 SG_ bcm_ElVent8MotorDrivingDirection : 40|2@1+ (1,0) [0|3] ""  IVI
 SG_ bcm_ElVent8TorqueKeepingSts : 42|2@1+ (1,0) [0|3] ""  IVI
 SG_ bcm_ElVent8SpecialFunction : 44|2@1+ (1,0) [0|3] ""  IVI
 SG_ bcm_ElVent8LocationActuator : 48|8@1+ (1,0) [0|255] ""  IVI
 SG_ bcm_ElVent8EmengencyStopSwitchSt : 56|2@1+ (1,0) [0|3] ""  IVI
 SG_ bcm_ElVent8EmengencyStopSLocatio : 58|2@1+ (1,0) [0|3] ""  IVI
 SG_ bcm_ElVent8RotationMode : 60|2@1+ (1,0) [0|3] ""  IVI
 SG_ bcm_ElVent8StopStatus : 62|2@1+ (1,0) [0|3] ""  IVI

BO_ 977 GW_BCM_rsm: 8 GTW
 SG_ bcm_rsm_FwBrightness : 32|11@1+ (1,0) [0|2045] ""  IVI
 SG_ bcm_rsm_AmbBrightness : 46|10@1+ (1,0) [0|1021] ""  IVI
 SG_ bcm_rsm_IRBrightness : 56|8@1+ (8,0) [0|2024] ""  IVI

BO_ 1018 HUD_state: 8 HUD
 SG_ hud_onOffSts : 0|1@1+ (1,0) [0|1] ""  IVI
 SG_ hud_language : 1|2@1+ (1,0) [0|3] ""  IVI

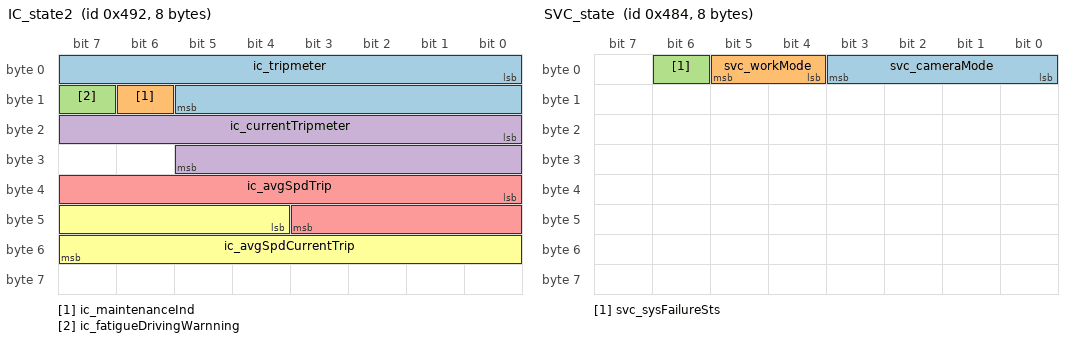
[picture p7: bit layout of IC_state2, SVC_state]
BO_ 1170 IC_state2: 8 IC
 SG_ ic_tripmeter : 0|14@1+ (1,0) [0|9999] "km"  IVI,TBOX_INFO
 SG_ ic_maintenanceInd : 14|1@1+ (1,0) [0|1] ""  IVI,TBOX_INFO
 SG_ ic_fatigueDrivingWarnning : 15|1@1+ (1,0) [0|1] ""  IVI
 SG_ ic_currentTripmeter : 16|14@1+ (1,0) [0|9999] "km"  IVI,TBOX_INFO
 SG_ ic_avgSpdTrip : 32|12@1+ (0.1,0) [0|280] "KPH"  IVI
 SG_ ic_avgSpdCurrentTrip : 44|12@1+ (0.1,0) [0|280] "KPH"  IVI

BO_ 951 PDC_state: 8 PDC
 SG_ pdc_buzzerAlarmPattern : 0|3@1+ (1,0) [0|7] ""  IVI
 SG_ pdc_modeStatus : 3|3@1+ (1,0) [0|7] ""  IVI
 SG_ pdc_ledIndication : 6|1@1+ (1,0) [0|1] ""  IVI
 SG_ pdc_voltageAbnormal : 7|1@1+ (1,0) [0|1] ""  IVI
 SG_ pdc_distanceFL : 8|3@1+ (1,0) [0|7] ""  IVI
 SG_ pdc_sensorFaultFL : 11|1@1+ (1,0) [0|1] ""  IVI
 SG_ pdc_distanceFML : 12|3@1+ (1,0) [0|7] ""  IVI
 SG_ pdc_sensorFaultFML : 15|1@1+ (1,0) [0|1] ""  IVI
 SG_ pdc_distanceFMR : 16|3@1+ (1,0) [0|7] ""  IVI
 SG_ pdc_sensorFaultFMR : 19|1@1+ (1,0) [0|1] ""  IVI
 SG_ pdc_distanceFR : 20|3@1+ (1,0) [0|7] ""  IVI
 SG_ pdc_sensorFaultFR : 23|1@1+ (1,0) [0|1] ""  IVI
 SG_ pdc_distanceRL : 24|3@1+ (1,0) [0|7] ""  IVI
 SG_ pdc_sensorFaultRL : 27|1@1+ (1,0) [0|1] ""  IVI
 SG_ pdc_distanceRML : 28|3@1+ (1,0) [0|7] ""  IVI
 SG_ pdc_sensorFaultRML : 31|1@1+ (1,0) [0|1] ""  IVI
 SG_ pdc_distanceRMR : 32|3@1+ (1,0) [0|7] ""  IVI
 SG_ pdc_sensorFaultRMR : 35|1@1+ (1,0) [0|1] ""  IVI
 SG_ pdc_distanceRR : 36|3@1+ (1,0) [0|7] ""  IVI
 SG_ pdc_sensorFaultRR : 39|1@1+ (1,0) [0|1] ""  IVI
 SG_ pdc_configInfo : 40|3@1+ (1,0) [0|7] ""  IVI
 SG_ pdc_systemType : 43|3@1+ (1,0) [0|7] ""  IVI
 SG_ pdc_ecuFault : 46|2@1+ (1,0) [0|3] ""  IVI
 SG_ pdc_canFault : 48|2@1+ (1,0) [0|3] ""  IVI

BO_ 116 SVC_calib: 8 SVC
 SG_ svc_calibrationState : 0|4@1+ (1,0) [0|4] ""  IVI

BO_ 1156 SVC_state: 8 SVC
 SG_ svc_cameraMode : 0|4@1+ (1,0) [0|15] ""  IVI
 SG_ svc_workMode : 4|2@1+ (1,0) [0|3] ""  IVI
 SG_ svc_sysFailureSts : 6|1@1+ (1,0) [0|1] ""  IVI

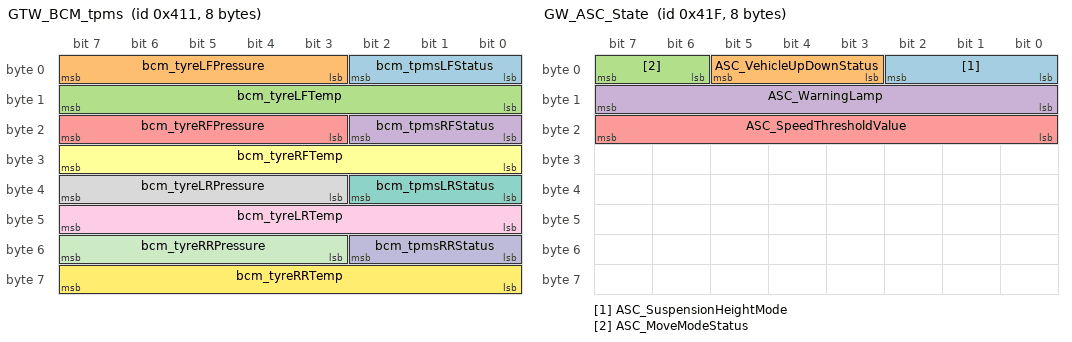
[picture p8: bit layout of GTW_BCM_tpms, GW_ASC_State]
BO_ 1041 GTW_BCM_tpms: 8 GTW
 SG_ bcm_tpmsLFStatus : 0|3@1+ (1,0) [0|7] ""  IVI,IC
 SG_ bcm_tyreLFPressure : 3|5@1+ (0.1,0.9) [1|4] "bar"  IVI,IC
 SG_ bcm_tyreLFTemp : 8|8@1+ (1,-41) [-40|125] "degreeC"  IVI,IC
 SG_ bcm_tpmsRFStatus : 16|3@1+ (1,0) [0|7] ""  IVI,IC
 SG_ bcm_tyreRFPressure : 19|5@1+ (0.1,0.9) [1|4] "bar"  IVI,IC
 SG_ bcm_tyreRFTemp : 24|8@1+ (1,-41) [-40|125] "degreeC"  IVI,IC
 SG_ bcm_tpmsLRStatus : 32|3@1+ (1,0) [0|7] ""  IVI,IC
 SG_ bcm_tyreLRPressure : 35|5@1+ (0.1,0.9) [1|4] "bar"  IVI,IC
 SG_ bcm_tyreLRTemp : 40|8@1+ (1,-41) [-40|125] "degreeC"  IVI,IC
 SG_ bcm_tpmsRRStatus : 48|3@1+ (1,0) [0|7] ""  IVI,IC
 SG_ bcm_tyreRRPressure : 51|5@1+ (0.1,0.9) [1|4] "bar"  IVI,IC
 SG_ bcm_tyreRRTemp : 56|8@1+ (1,-41) [-40|125] "degreeC"  IVI,IC

BO_ 1055 GW_ASC_State: 8 GTW
 SG_ ASC_SuspensionHeightMode : 0|3@1+ (1,0) [0|7] ""  IVI,IC,TBOX_INFO
 SG_ ASC_VehicleUpDownStatus : 3|3@1+ (1,0) [0|7] ""  IVI,IC
 SG_ ASC_MoveModeStatus : 6|2@1+ (1,0) [0|3] ""  IVI,IC
 SG_ ASC_WarningLamp : 8|8@1+ (1,0) [0|255] ""  IVI
 SG_ ASC_SpeedThresholdValue : 16|8@1+ (1,0) [0|255] ""  IVI

BO_ 1154 IC_state1: 8 IC
 SG_ ic_languageSts : 10|4@1+ (1,0) [0|15] ""  IVI,GTW
 SG_ ic_minSocWarningSts : 48|8@1+ (0.5,10) [10|50] "%"  IVI,GTW

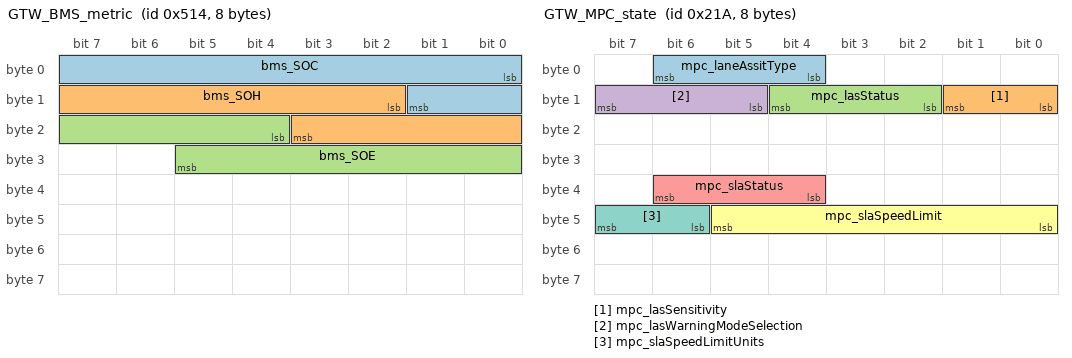
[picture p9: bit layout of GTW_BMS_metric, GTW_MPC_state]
BO_ 1300 GTW_BMS_metric: 8 GTW
 SG_ bms_SOC : 0|10@1+ (0.1,0) [0|100] "%"  IVI,IC,TBOX_INFO
 SG_ bms_SOH : 10|10@1+ (0.1,0) [0|100] "%"  IVI,IC,TBOX_INFO
 SG_ bms_SOE : 20|10@1+ (0.1,0) [0|100] "%"  IVI,IC,TBOX_INFO

BO_ 2015 Diag_FuncReq: 8 GTW
 SG_ Diag_FuncReq_Data : 0|64@1+ (1,0) [0|0] "N/A"  IVI,IC,PDC,TBOX_INFO,WCM,SVC,VSP,DVR,HUD

BO_ 324 GTW_EPS_sas: 8 GTW
 SG_ eps_sasSteeringAngle : 0|16@1+ (0.1,-780) [-780|779.9] "deg"  IVI,IC,TBOX_INFO,SVC
 SG_ eps_sasSteeringAngleValid : 50|1@1+ (1,0) [0|1] ""  IVI,IC,SVC

BO_ 537 GTW_MRR_acc: 8 GTW
 SG_ mrr_ccFuntionMode : 48|2@1+ (1,0) [0|3] ""  IVI

BO_ 538 GTW_MPC_state: 8 GTW
 SG_ mpc_laneAssitType : 4|3@1+ (1,0) [0|7] ""  IVI,IC,HUD
 SG_ mpc_lasSensitivity : 8|2@1+ (1,0) [0|3] ""  IVI,IC
 SG_ mpc_lasStatus : 10|3@1+ (1,0) [0|7] ""  IVI,IC,HUD
 SG_ mpc_lasWarningModeSelection : 13|3@1+ (1,0) [0|7] ""  IVI,IC
 SG_ mpc_slaStatus : 36|3@1+ (1,0) [0|7] ""  IVI,IC
 SG_ mpc_slaSpeedLimit : 40|6@1+ (5,0) [0|255] ""  IVI,IC,HUD
 SG_ mpc_slaSpeedLimitUnits : 46|2@1+ (1,0) [0|3] ""  IVI,IC

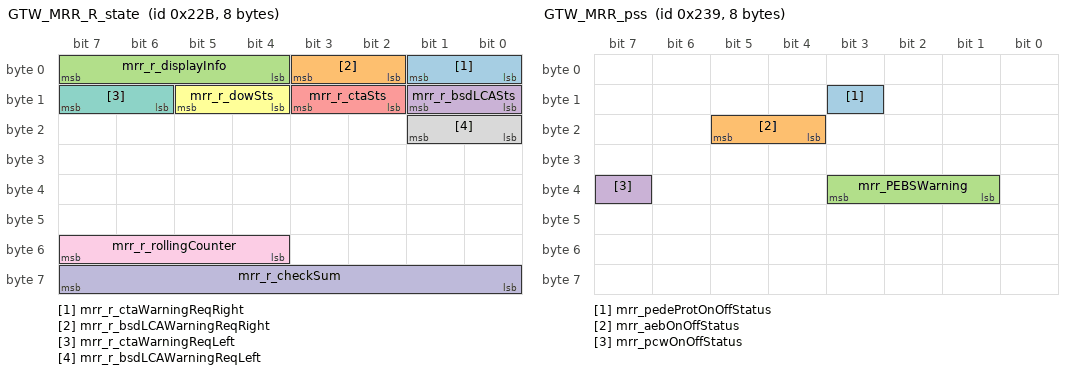
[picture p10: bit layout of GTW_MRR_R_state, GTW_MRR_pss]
BO_ 555 GTW_MRR_R_state: 8 GTW
 SG_ mrr_r_ctaWarningReqRight : 0|2@1+ (1,0) [0|3] ""  IVI,IC
 SG_ mrr_r_bsdLCAWarningReqRight : 2|2@1+ (1,0) [0|3] ""  IVI,IC
 SG_ mrr_r_displayInfo : 4|4@1+ (1,0) [0|15] ""  IVI,IC
 SG_ mrr_r_bsdLCASts : 8|2@1+ (1,0) [0|3] ""  IVI,IC
 SG_ mrr_r_ctaSts : 10|2@1+ (1,0) [0|3] ""  IVI
 SG_ mrr_r_dowSts : 12|2@1+ (1,0) [0|3] ""  IVI,IC
 SG_ mrr_r_ctaWarningReqLeft : 14|2@1+ (1,0) [0|3] ""  IVI,IC
 SG_ mrr_r_bsdLCAWarningReqLeft : 16|2@1+ (1,0) [0|3] ""  IVI,IC
 SG_ mrr_r_rollingCounter : 52|4@1+ (1,0) [0|15] ""  IVI,IC
 SG_ mrr_r_checkSum : 56|8@1+ (1,0) [0|255] "N/A"  IVI,IC

BO_ 569 GTW_MRR_pss: 8 GTW
 SG_ mrr_pedeProtOnOffStatus : 11|1@1+ (1,0) [0|1] ""  IVI,IC
 SG_ mrr_aebOnOffStatus : 20|2@1+ (1,0) [0|3] ""  IVI
 SG_ mrr_PEBSWarning : 33|3@1+ (1,0) [0|7] ""  IVI,IC,HUD
 SG_ mrr_pcwOnOffStatus : 39|1@1+ (1,0) [0|1] ""  IVI,IC

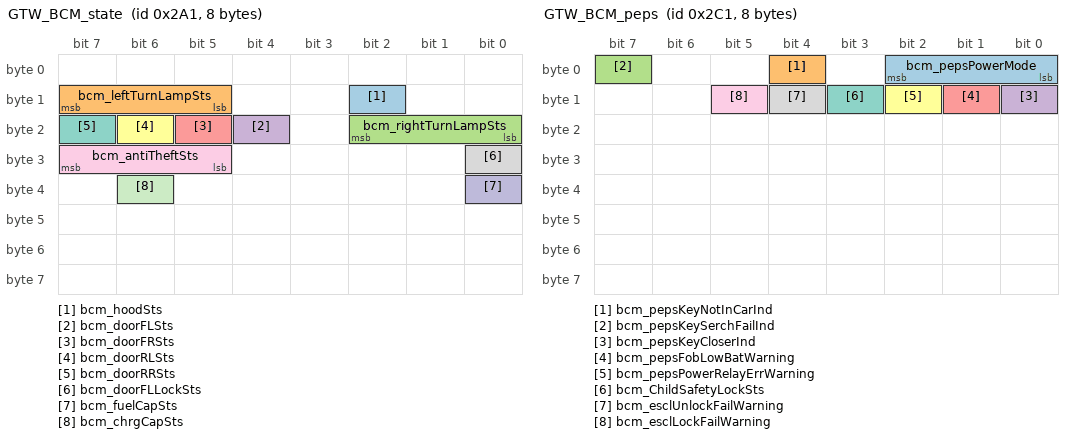
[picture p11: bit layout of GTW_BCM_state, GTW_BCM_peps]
BO_ 673 GTW_BCM_state: 8 GTW
 SG_ bcm_hoodSts : 10|1@1+ (1,0) [0|1] ""  IVI,IC
 SG_ bcm_leftTurnLampSts : 13|3@1+ (1,0) [0|7] ""  IVI,IC,SVC,DVR,SVM
 SG_ bcm_rightTurnLampSts : 16|3@1+ (1,0) [0|7] ""  IVI,IC,SVC,DVR,SVM
 SG_ bcm_doorFLSts : 20|1@1+ (1,0) [0|1] ""  IVI,IC,SVC
 SG_ bcm_doorFRSts : 21|1@1+ (1,0) [0|1] ""  IVI,IC,SVC
 SG_ bcm_doorRLSts : 22|1@1+ (1,0) [0|1] ""  IVI,IC,SVC
 SG_ bcm_doorRRSts : 23|1@1+ (1,0) [0|1] ""  IVI,IC,SVC
 SG_ bcm_doorFLLockSts : 24|1@1+ (1,0) [0|1] ""  IVI
 SG_ bcm_antiTheftSts : 29|3@1+ (1,0) [0|7] ""  IVI,DVR
 SG_ bcm_fuelCapSts : 32|1@1+ (1,0) [0|1] ""  IVI,IC
 SG_ bcm_chrgCapSts : 38|1@1+ (1,0) [0|1] ""  IVI,IC,TBOX_INFO

BO_ 705 GTW_BCM_peps: 8 GTW
 SG_ bcm_pepsPowerMode : 0|3@1+ (1,0) [0|7] ""  IVI,IC,PDC,DVR
 SG_ bcm_pepsKeyNotInCarInd : 4|1@1+ (1,0) [0|1] ""  IVI,IC
 SG_ bcm_pepsKeySerchFailInd : 7|1@1+ (1,0) [0|1] ""  IVI,IC
 SG_ bcm_pepsKeyCloserInd : 8|1@1+ (1,0) [0|1] ""  IVI,IC
 SG_ bcm_pepsFobLowBatWarning : 9|1@1+ (1,0) [0|1] ""  IVI,IC
 SG_ bcm_pepsPowerRelayErrWarning : 10|1@1+ (1,0) [0|1] ""  IVI,IC
 SG_ bcm_ChildSafetyLockSts : 11|1@1+ (1,0) [0|1] ""  IVI,IC
 SG_ bcm_esclUnlockFailWarning : 12|1@1+ (1,0) [0|1] ""  IVI,IC
 SG_ bcm_esclLockFailWarning : 13|1@1+ (1,0) [0|1] ""  IVI,IC

BO_ 706 GTW_ESC_epb: 8 GTW
 SG_ esc_epbStatus : 8|3@1+ (1,0) [0|7] ""  IVI,IC,PDC,TBOX_INFO,DVR
 SG_ esc_epbTextDisplayOnIVI : 11|2@1+ (1,0) [0|3] ""  IVI

BO_ 754 IC_state: 8 IC
 SG_ ic_totalMileage : 0|24@1+ (0.1,0) [0|1677721.4] "km"  IVI,PDC,TBOX_INFO,DVR,GTW
 SG_ ic_themeSts : 37|3@1+ (1,0) [0|7] ""  IVI,GTW

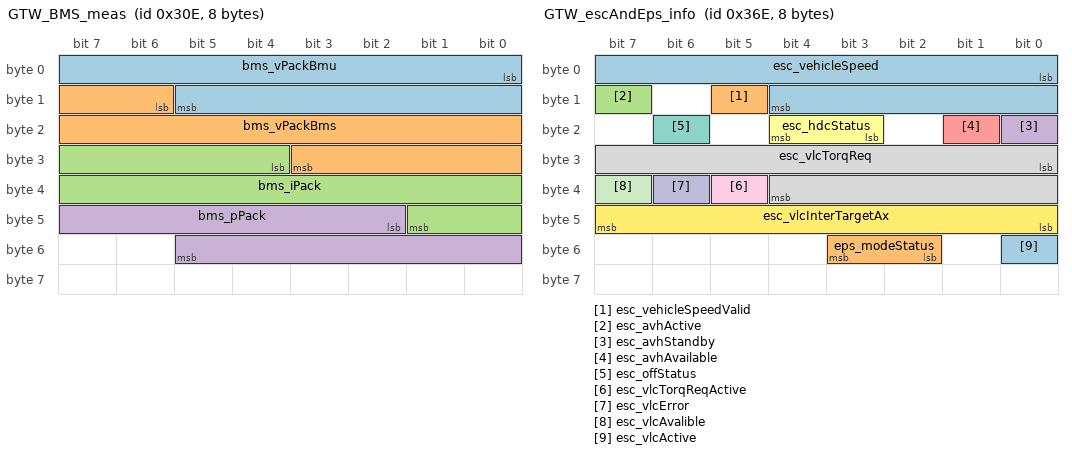
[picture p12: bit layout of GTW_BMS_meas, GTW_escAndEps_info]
BO_ 782 GTW_BMS_meas: 8 GTW
 SG_ bms_vPackBmu : 0|14@1+ (0.05,0) [0|800] "V"  IVI,IC,TBOX_INFO
 SG_ bms_vPackBms : 14|14@1+ (0.05,0) [0|800] "V"  IVI,IC,TBOX_INFO
 SG_ bms_iPack : 28|14@1+ (0.2,-600) [-600|2500] "A"  IVI,IC,TBOX_INFO
 SG_ bms_pPack : 42|12@1+ (0.25,0) [0|1000] "KW"  IVI,IC,TBOX_INFO

BO_ 878 GTW_escAndEps_info: 8 GTW
 SG_ esc_vehicleSpeed : 0|13@1+ (0.05625,0) [0|270] "km/h"  IVI,IC,PDC,TBOX_INFO,SVC,VSP,DVR
 SG_ esc_vehicleSpeedValid : 13|1@1+ (1,0) [0|1] ""  IVI,IC,PDC,TBOX_INFO,SVC,VSP,DVR
 SG_ esc_avhActive : 15|1@1+ (1,0) [0|1] ""  IVI,IC
 SG_ esc_avhStandby : 16|1@1+ (1,0) [0|1] ""  IVI,IC
 SG_ esc_avhAvailable : 17|1@1+ (1,0) [0|1] ""  IVI
 SG_ esc_hdcStatus : 19|2@1+ (1,0) [0|3] ""  IVI,IC
 SG_ esc_offStatus : 22|1@1+ (1,0) [0|1] ""  IVI,IC
 SG_ esc_vlcTorqReq : 24|13@1+ (0.25,-500) [-500|1547.5] "N.m"  IVI
 SG_ esc_vlcTorqReqActive : 37|1@1+ (1,0) [0|1] ""  IVI
 SG_ esc_vlcError : 38|1@1+ (1,0) [0|1] ""  IVI
 SG_ esc_vlcAvalible : 39|1@1+ (1,0) [0|1] ""  IVI
 SG_ esc_vlcInterTargetAx : 40|8@1+ (0.05,-7) [-7|5.75] ""  IVI
 SG_ esc_vlcActive : 48|1@1+ (1,0) [0|1] ""  IVI
 SG_ eps_modeStatus : 50|2@1+ (1,0) [0|3] ""  IVI

BO_ 910 GTW_vcuCha_info: 8 GTW
 SG_ vcu_actualGearValid : 49|1@1+ (1,0) [0|1] ""  IVI,IC,HUD,SVM
 SG_ vcu_actualGear : 50|2@1+ (1,0) [0|3] ""  IVI,IC,PDC,TBOX_INFO,SVC,VSP,DVR,HUD,SVM

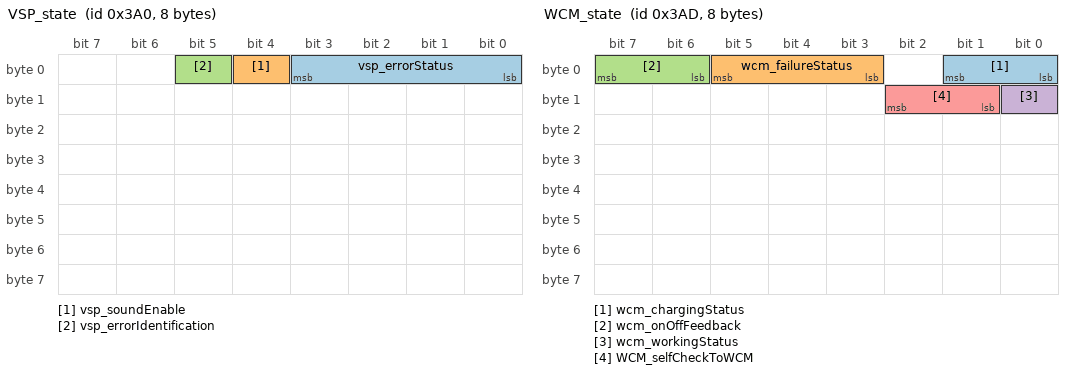
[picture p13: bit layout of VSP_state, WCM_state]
BO_ 928 VSP_state: 8 VSP
 SG_ vsp_errorStatus : 0|4@1+ (1,0) [0|15] ""  IVI,IC
 SG_ vsp_soundEnable : 4|1@1+ (1,0) [0|1] ""  IVI
 SG_ vsp_errorIdentification : 5|1@1+ (1,0) [0|1] ""  IVI

BO_ 941 WCM_state: 8 WCM
 SG_ wcm_chargingStatus : 0|2@1+ (1,0) [0|3] ""  IVI,IC
 SG_ wcm_failureStatus : 3|3@1+ (1,0) [0|7] ""  IVI,IC
 SG_ wcm_onOffFeedback : 6|2@1+ (1,0) [0|3] ""  IVI,IC
 SG_ wcm_workingStatus : 8|1@1+ (1,0) [0|1] ""  IVI,IC
 SG_ WCM_selfCheckToWCM : 9|2@1+ (1,0) [0|3] ""  IVI

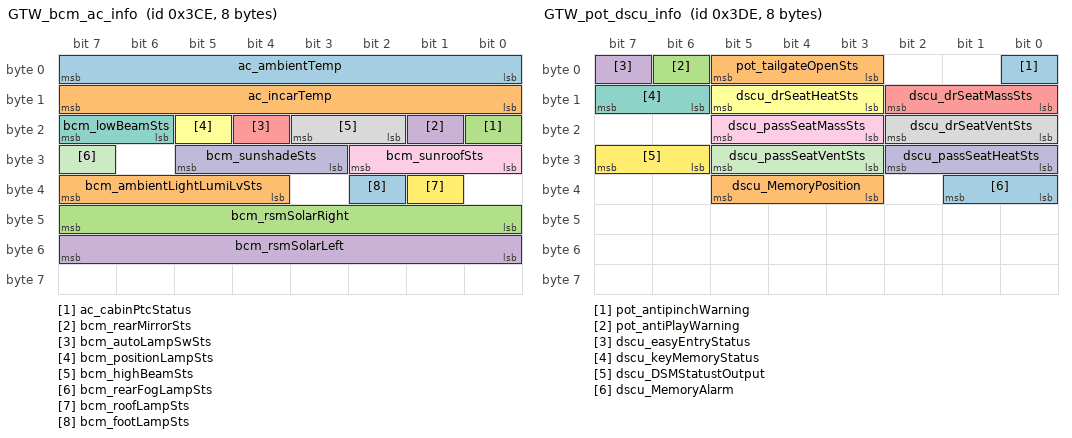
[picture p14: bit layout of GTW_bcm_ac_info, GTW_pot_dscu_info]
BO_ 974 GTW_bcm_ac_info: 8 GTW
 SG_ ac_ambientTemp : 0|8@1+ (0.5,-40) [-40|85] "degreeC"  IVI,IC,PDC
 SG_ ac_incarTemp : 8|8@1+ (0.5,-40) [-40|85] "degreeC"  IVI,IC
 SG_ ac_cabinPtcStatus : 16|1@1+ (1,0) [0|1] ""  IVI
 SG_ bcm_rearMirrorSts : 17|1@1+ (1,0) [0|1] ""  IVI,SVC,SVM
 SG_ bcm_autoLampSwSts : 20|1@1+ (1,0) [0|1] ""  IVI,IC
 SG_ bcm_positionLampSts : 21|1@1+ (1,0) [0|1] ""  IVI,IC,SVC,HUD
 SG_ bcm_lowBeamSts : 22|2@1+ (1,0) [0|1] ""  IVI,IC,SVC,DVR
 SG_ bcm_highBeamSts : 18|2@1+ (1,0) [0|1] ""  IVI,IC,SVC,DVR
 SG_ bcm_sunroofSts : 24|3@1+ (1,0) [0|7] ""  IVI
 SG_ bcm_sunshadeSts : 27|3@1+ (1,0) [0|7] ""  IVI
 SG_ bcm_rearFogLampSts : 31|1@1+ (1,0) [0|1] ""  IVI,IC,SVC,DVR
 SG_ bcm_roofLampSts : 33|1@1+ (1,0) [0|1] ""  IVI
 SG_ bcm_footLampSts : 34|1@1+ (1,0) [0|1] ""  IVI
 SG_ bcm_ambientLightLumiLvSts : 36|4@1+ (1,0) [0|15] ""  IVI
 SG_ bcm_rsmSolarRight : 40|8@1+ (5,0) [0|1265] "w/m2"  IVI
 SG_ bcm_rsmSolarLeft : 48|8@1+ (5,0) [0|1265] "w/m2"  IVI

BO_ 990 GTW_pot_dscu_info: 8 GTW
 SG_ pot_antipinchWarning : 0|1@1+ (1,0) [0|1] ""  IVI,IC
 SG_ pot_tailgateOpenSts : 3|3@1+ (1,0) [0|7] ""  IVI,IC,SVC
 SG_ pot_antiPlayWarning : 6|1@1+ (1,0) [0|1] ""  IVI,IC
 SG_ dscu_easyEntryStatus : 7|1@1+ (1,0) [0|1] ""  IVI
 SG_ dscu_drSeatMassSts : 8|3@1+ (1,0) [0|7] ""  IVI
 SG_ dscu_drSeatHeatSts : 11|3@1+ (1,0) [0|7] ""  IVI
 SG_ dscu_keyMemoryStatus : 14|2@1+ (1,0) [0|3] ""  IVI
 SG_ dscu_drSeatVentSts : 16|3@1+ (1,0) [0|7] ""  IVI
 SG_ dscu_passSeatMassSts : 19|3@1+ (1,0) [0|7] ""  IVI
 SG_ dscu_passSeatHeatSts : 24|3@1+ (1,0) [0|7] ""  IVI
 SG_ dscu_passSeatVentSts : 27|3@1+ (1,0) [0|7] ""  IVI
 SG_ dscu_DSMStatustOutput : 30|2@1+ (1,0) [0|3] ""  IVI
 SG_ dscu_MemoryAlarm : 32|2@1+ (1,0) [0|3] ""  IVI
 SG_ dscu_MemoryPosition : 35|3@1+ (1,0) [0|7] ""  IVI

CM_ SG_ 965 ivi_naviTextStrLength "导航信息文本长度.触发时以20ms周期发送，最多发送10帧.（HUD提需求导航文字信息需重复发送一次）";
CM_ SG_ 965 ivi_naviText1 "导航信息文本1";
CM_ SG_ 965 ivi_naviText2 "导航信息文本2";
CM_ SG_ 965 ivi_naviText3 "导航信息文本3";
CM_ SG_ 965 ivi_naviTextCountNum "导航信息文本数据包编号";
CM_ SG_ 165 ivi_driveModeSet "Driving mode set.";
CM_ SG_ 165 ivi_travelModeSet "Travel mode set.";
CM_ SG_ 165 ivi_maxChrgSocSet "Maximum charge SOC set.
最大充电电量设置";
CM_ SG_ 165 ivi_4wdModeSet "4WD mode set.";
CM_ SG_ 165 ivi_cancelChargeSet "Cancel charge control set.";
CM_ SG_ 165 ivi_chargeFormSet "Charge form set.";
CM_ SG_ 165 ivi_engyRcvrOnOffSet "Energy recovery on off set.";
CM_ SG_ 165 ivi_engyRcvrIntensitySet "Energy recovery intensity set.";
CM_ SG_ 165 ivi_tractionModeSet "traction Mode Set";
CM_ SG_ 165 ivi_dcdcAutochargeSet "dcdc Auto charge Set";
CM_ SG_ 165 ivi_ASCHeightModeSelected "ASC_SuspensionModeSelected";
CM_ SG_ 165 ivi_ASCSpeedChangeEnableSwitch "ASCSpeedChangeEnableSwitch";
CM_ SG_ 165 ivi_crawlModeSet "Crawl mode set.";
CM_ SG_ 165 ivi_ASCSpeedThresholdValueChange "VehicleSpeedThresholdValueChange";
CM_ SG_ 165 ivi_esc_epbButtonRelease "epb button release";
CM_ SG_ 165 ivi_ASCMoveModeControl "MovementModeControl";
CM_ SG_ 165 ivi_enableCreepTorque "enable Creep Torque";
CM_ SG_ 165 ivi_chargeModeSet "Charge mode set.";
CM_ SG_ 165 ivi_maxChargeCurrentSet "Maximum charge current set.";
CM_ SG_ 245 ivi_easyEntrySet "Easy entry function set.";
CM_ SG_ 245 ivi_drSeatVentLevelSet "Driver seat Venting level set.";
CM_ SG_ 245 ivi_passSeatHeatOnOffSet "Passenger seat heating ON OFF set.";
CM_ SG_ 245 ivi_passSeatVentOnOffSet "Passenger seat Venting ON OFF set.";
CM_ SG_ 245 ivi_passSeatHeatLevelSet "Passenger seat heating level set.";
CM_ SG_ 245 ivi_drSeatHeatOnOffSet "Driver seat heating ON OFF set.";
CM_ SG_ 245 ivi_passSeatVentLevelSet "Passenger seat Venting level set.";
CM_ SG_ 245 ivi_passSeatMassOnOffSet "Passenger seat Massage ON OFF set.";
CM_ SG_ 245 ivi_drSeatMassLevelSet "Driver seat Massage level set.";
CM_ SG_ 245 ivi_passSeatMassLevelSet "Passenger seat Massage level set.";
CM_ SG_ 245 ivi_mirrorSet "Mirror function set.";
CM_ SG_ 245 ivi_memorySet "Memory set.";
CM_ SG_ 245 ivi_memoryNumSet "Memory number set.";
CM_ SG_ 245 ivi_drSeatVentOnOffSet "Driver seat Venting ON OFF set.";
CM_ SG_ 245 ivi_dsmSetMemoryReq "memory set request";
CM_ SG_ 245 ivi_dsmGetMemoryReq "memory get request";
CM_ SG_ 245 ivi_drSeatMassOnOffSet "Driver seat Massage ON OFF set.";
CM_ SG_ 245 ivi_drSeatHeatLevelSet "Driver seat heating level set.";
CM_ SG_ 949 ivi_hvacDefrostMode "HVAC Defrost mode.";
CM_ SG_ 949 ivi_hvacOnOffReq "Request HVAC switch Status.";
CM_ SG_ 949 ivi_passengerTempFSet "Passenger Temperature Fahrenheit
乘客侧设置温度_华氏度";
CM_ SG_ 949 ivi_hvacModeReq "HVAC mode request.";
CM_ SG_ 949 ivi_driverTempCSet "Driver Temperature Celsius
驾驶侧设置温度_摄氏度";
CM_ SG_ 949 ivi_driverTempFSet "Driver Temperature Fahrenheit
驾驶侧设置温度_华氏度";
CM_ SG_ 949 ivi_hvacBlowLvReq "HVAC blow level request.";
CM_ SG_ 949 ivi_passengerTempCSet "Passenger Temperature Celsius
乘客侧设置温度_摄氏度";
CM_ SG_ 949 ivi_hvacDualMode "HVAC Dual mode.";
CM_ SG_ 949 ivi_hvacPTCReq "HVAC PTC request.";
CM_ SG_ 949 ivi_acReq "Request the status of HVAC clutch.";
CM_ SG_ 949 ivi_svcCameraModeSet "SVC camera mode change request.";
CM_ SG_ 949 ivi_acDiagReq "AC diagnostic request.";
CM_ SG_ 949 ivi_svcFrontTrackDispSet "Set the front track line display status";
CM_ SG_ 949 ivi_svcRvrsTrackDispSet "Set the reverse track line display status";
CM_ SG_ 949 ivi_svcOutMirrorTrackDispSet "Set the out mirror track line display status";
CM_ SG_ 949 ivi_svcOnOffSw "SVC on off switch.";
CM_ SG_ 949 ivi_svcSteerInteractionSet "SVC steering interaction on off switch.
SVC 转向联动功能";
CM_ SG_ 949 ivi_languageSet "Language set.";
CM_ SG_ 949 ivi_unitSet "Length measurement unit set.";
CM_ SG_ 949 ivi_hvacAutoModeReq "HVAC auto mode request.";
CM_ SG_ 949 ivi_hvacRecircModeReq "HVAC recirculation mode request.";
CM_ SG_ 229 ivi_svcCalibrateStart "IVI calibration start sequence.
IVI标定启动序列";
CM_ SG_ 229 ivi_svcCaliInfoReq "IVI calibration information request.
IVI标定信息查询";
CM_ SG_ 213 ivi_svcXCoordinate "X coordinate
SVC画面按键坐标，X坐标";
CM_ SG_ 213 ivi_svcYCoordinate "Y coordinate
SVC画面按键坐标，Y坐标";
CM_ SG_ 213 ivi_svcCoTouchMotion "SVC image user Touch or release coordinate
SVC画面下，用户点击及释放坐标状态";
CM_ SG_ 1013 ivi_timeInfoSecond "Time informatioin, Second.";
CM_ SG_ 1013 ivi_timeInfoHour "Time informatioin, Hour.";
CM_ SG_ 1013 ivi_timeInfoDay "Time informatioin, Day.";
CM_ SG_ 1013 ivi_timeInfoMonth "Time informatioin, Month.";
CM_ SG_ 1013 ivi_timeInfoYear "Time informatioin, Year. Start from year 2000.";
CM_ SG_ 1013 ivi_longitude "Longtitude. East positive, West negtive.";
CM_ SG_ 1013 ivi_latitude "Latitude. North positive, South negtive.";
CM_ SG_ 1013 ivi_timeInfoMinute "Time informatioin, Minute.";
CM_ SG_ 533 ivi_ElVent1LocationActuator "地址执行器";
CM_ SG_ 533 ivi_ElVent1ObstructionCheck "阻塞检测";
CM_ SG_ 533 ivi_ElVent1MarkClear "清除标记";
CM_ SG_ 533 ivi_ElVent1CoilElectrify "线圈通电";
CM_ SG_ 533 ivi_ElVent1LocationSelect "位置选择";
CM_ SG_ 533 ivi_ElVent1SpeedMode "速度模式";
CM_ SG_ 533 ivi_ElVent1MotorTargetLocation "电机目标位置";
CM_ SG_ 533 ivi_ElVent1MotorOriginalLocation "电机起始位置";
CM_ SG_ 533 ivi_ElVent1EmergencyStopSwitch "急停开关";
CM_ SG_ 533 ivi_ElVent1EmergencyStopLocation "急停位置";
CM_ SG_ 533 ivi_ElVent1RotationMode "旋转方式";
CM_ SG_ 533 ivi_ElVent1StopMode "停止模式";
CM_ SG_ 533 ivi_ElVent1ProgrammingDataSave "保存编程数据";
CM_ SG_ 549 ivi_ElVent2LocationActuator "地址执行器";
CM_ SG_ 549 ivi_ElVent2ObstructionCheck "阻塞检测";
CM_ SG_ 549 ivi_ElVent2MarkClear "清除标记";
CM_ SG_ 549 ivi_ElVent2CoilElectrify "线圈通电";
CM_ SG_ 549 ivi_ElVent2LocationSelect "位置选择";
CM_ SG_ 549 ivi_ElVent2SpeedMode "速度模式";
CM_ SG_ 549 ivi_ElVent2MotorTargetLocation "电机目标位置";
CM_ SG_ 549 ivi_ElVent2MotorOriginalLocation "电机起始位置";
CM_ SG_ 549 ivi_ElVent2EmergencyStopSwitch "急停开关";
CM_ SG_ 549 ivi_ElVent2EmergencyStopLocation "急停位置";
CM_ SG_ 549 ivi_ElVent2RotationMode "旋转方式";
CM_ SG_ 549 ivi_ElVent2StopMode "停止模式";
CM_ SG_ 549 ivi_ElVent2ProgrammingDataSave "保存编程数据";
CM_ SG_ 565 ivi_ElVent3LocationActuator "地址执行器";
CM_ SG_ 565 ivi_ElVent3ObstructionCheck "阻塞检测";
CM_ SG_ 565 ivi_ElVent3MarkClear "清除标记";
CM_ SG_ 565 ivi_ElVent3CoilElectrify "线圈通电";
CM_ SG_ 565 ivi_ElVent3LocationSelect "位置选择";
CM_ SG_ 565 ivi_ElVent3SpeedMode "速度模式";
CM_ SG_ 565 ivi_ElVent3MotorTargetLocation "电机目标位置";
CM_ SG_ 565 ivi_ElVent3MotorOriginalLocation "电机起始位置";
CM_ SG_ 565 ivi_ElVent3EmergencyStopSwitch "急停开关";
CM_ SG_ 565 ivi_ElVent3EmergencyStopLocation "急停位置";
CM_ SG_ 565 ivi_ElVent3RotationMode "旋转方式";
CM_ SG_ 565 ivi_ElVent3StopMode "停止模式";
CM_ SG_ 565 ivi_ElVent3ProgrammingDataSave "保存编程数据";
CM_ SG_ 581 ivi_ElVent4LocationActuator "地址执行器";
CM_ SG_ 581 ivi_ElVent4ObstructionCheck "阻塞检测";
CM_ SG_ 581 ivi_ElVent4MarkClear "清除标记";
CM_ SG_ 581 ivi_ElVent4CoilElectrify "线圈通电";
CM_ SG_ 581 ivi_ElVent4LocationSelect "位置选择";
CM_ SG_ 581 ivi_ElVent4SpeedMode "速度模式";
CM_ SG_ 581 ivi_ElVent4MotorTargetLocation "电机目标位置";
CM_ SG_ 581 ivi_ElVent4MotorOriginalLocation "电机起始位置";
CM_ SG_ 581 ivi_ElVent4EmergencyStopSwitch "急停开关";
CM_ SG_ 581 ivi_ElVent4EmergencyStopLocation "急停位置";
CM_ SG_ 581 ivi_ElVent4RotationMode "旋转方式";
CM_ SG_ 581 ivi_ElVent4StopMode "停止模式";
CM_ SG_ 581 ivi_ElVent4ProgrammingDataSave "保存编程数据";
CM_ SG_ 597 ivi_ElVent5LocationActuator "地址执行器";
CM_ SG_ 597 ivi_ElVent5ObstructionCheck "阻塞检测";
CM_ SG_ 597 ivi_ElVent5MarkClear "清除标记";
CM_ SG_ 597 ivi_ElVent5CoilElectrify "线圈通电";
CM_ SG_ 597 ivi_ElVent5LocationSelect "位置选择";
CM_ SG_ 597 ivi_ElVent5SpeedMode "速度模式";
CM_ SG_ 597 ivi_ElVent5MotorTargetLocation "电机目标位置";
CM_ SG_ 597 ivi_ElVent5MotorOriginalLocation "电机起始位置";
CM_ SG_ 597 ivi_ElVent5EmergencyStopSwitch "急停开关";
CM_ SG_ 597 ivi_ElVent5EmergencyStopLocation "急停位置";
CM_ SG_ 597 ivi_ElVent5RotationMode "旋转方式";
CM_ SG_ 597 ivi_ElVent5StopMode "停止模式";
CM_ SG_ 597 ivi_ElVent5ProgrammingDataSave "保存编程数据";
CM_ SG_ 613 ivi_ElVent6LocationActuator "地址执行器";
CM_ SG_ 613 ivi_ElVent6ObstructionCheck "阻塞检测";
CM_ SG_ 613 ivi_ElVent6MarkClear "清除标记";
CM_ SG_ 613 ivi_ElVent6CoilElectrify "线圈通电";
CM_ SG_ 613 ivi_ElVent6LocationSelect "位置选择";
CM_ SG_ 613 ivi_ElVent6SpeedMode "速度模式";
CM_ SG_ 613 ivi_ElVent6MotorTargetLocation "电机目标位置";
CM_ SG_ 613 ivi_ElVent6MotorOriginalLocation "电机起始位置";
CM_ SG_ 613 ivi_ElVent6EmergencyStopSwitch "急停开关";
CM_ SG_ 613 ivi_ElVent6EmergencyStopLocation "急停位置";
CM_ SG_ 613 ivi_ElVent6RotationMode "旋转方式";
CM_ SG_ 613 ivi_ElVent6StopMode "停止模式";
CM_ SG_ 613 ivi_ElVent6ProgrammingDataSave "保存编程数据";
CM_ SG_ 629 ivi_ElVent7LocationActuator "地址执行器";
CM_ SG_ 629 ivi_ElVent7ObstructionCheck "阻塞检测";
CM_ SG_ 629 ivi_ElVent7MarkClear "清除标记";
CM_ SG_ 629 ivi_ElVent7CoilElectrify "线圈通电";
CM_ SG_ 629 ivi_ElVent7LocationSelect "位置选择";
CM_ SG_ 629 ivi_ElVent7SpeedMode "速度模式";
CM_ SG_ 629 ivi_ElVent7MotorTargetLocation "电机目标位置";
CM_ SG_ 629 ivi_ElVent7MotorOriginalLocation "电机起始位置";
CM_ SG_ 629 ivi_ElVent7EmergencyStopSwitch "急停开关";
CM_ SG_ 629 ivi_ElVent7EmergencyStopLocation "急停位置";
CM_ SG_ 629 ivi_ElVent7RotationMode "旋转方式";
CM_ SG_ 629 ivi_ElVent7StopMode "停止模式";
CM_ SG_ 629 ivi_ElVent7ProgrammingDataSave "保存编程数据";
CM_ SG_ 645 ivi_ElVent8LocationActuator "地址执行器";
CM_ SG_ 645 ivi_ElVent8ObstructionCheck "阻塞检测";
CM_ SG_ 645 ivi_ElVent8MarkClear "清除标记";
CM_ SG_ 645 ivi_ElVent8CoilElectrify "线圈通电";
CM_ SG_ 645 ivi_ElVent8LocationSelect "位置选择";
CM_ SG_ 645 ivi_ElVent8SpeedMode "速度模式";
CM_ SG_ 645 ivi_ElVent8MotorTargetLocation "电机目标位置";
CM_ SG_ 645 ivi_ElVent8MotorOriginalLocation "电机起始位置";
CM_ SG_ 645 ivi_ElVent8EmergencyStopSwitch "急停开关";
CM_ SG_ 645 ivi_ElVent8EmergencyStopLocation "急停位置";
CM_ SG_ 645 ivi_ElVent8RotationMode "旋转方式";
CM_ SG_ 645 ivi_ElVent8StopMode "停止模式";
CM_ SG_ 645 ivi_ElVent8ProgrammingDataSave "保存编程数据";
CM_ SG_ 937 dvr_workStatus "DVR working status.
DVR工作状态";
CM_ SG_ 937 dvr_sdCardStatus "SD card status.
SD卡状态";
CM_ SG_ 937 dvr_recordVideoQuality "DVR video record resolution.
DVR录制视频分辨率";
CM_ SG_ 937 dvr_muteRecordStatus "DVR sound record status.
DVR录制声音状态";
CM_ SG_ 937 dvr_recordTime "DVR record time.
DVR录制时长";
CM_ SG_ 937 dvr_collideSensitivityStatus "DVR collision sensor sensitivity.
DVR传感器灵敏度";
CM_ SG_ 937 dvr_updateStatus "DVR update notify.
DVR升级通知";
CM_ SG_ 937 dvr_parkingMonitor "DVR parking monitor status.
停车监控状态";
CM_ SG_ 937 dvr_Language "DVR language 
DVR 语言状态";
CM_ SG_ 937 dvr_systemVersionA "DVR main version number.
DVR版本信息主版本号，小数点前的版本号";
CM_ SG_ 937 dvr_systemVersionB "DVR DSP version number.
DVR版本信息DSP版本号，小数点后的第一个版本号";
CM_ SG_ 937 dvr_systemVersionC "DVR MCU version number.
DVR版本信息MCU版本号，小数点后的第二个版本号";
CM_ SG_ 937 dvr_updateSchedule "DVR update Schedule
DVR升级进度";
CM_ SG_ 937 dvr_commandRespList "DVR response command list.
DVR回复命令列表";
CM_ SG_ 1829 Diag_PhyReq_IVI_Data "Diagnostic Physical Request Data to IVI";
CM_ SG_ 950 ac_systemOnOffSts "System ON/OFF  Status
空调系统开启/关闭状态";
CM_ SG_ 950 ac_autoStatus "AUTO Status
自动模式状态";
CM_ SG_ 950 ac_acStatus "A/C Status
A/C状态";
CM_ SG_ 950 ac_driverTempC "Driver Temperature Celsius
驾驶侧设置温度_摄氏度";
CM_ SG_ 950 ac_dualStatus "Dual Temperature Status
双区状态";
CM_ SG_ 950 ac_frontDefrostStatus "Front Defrost Status
前除霜状态";
CM_ SG_ 950 ac_recircStatus "Fresh Air Status
内外循环状态";
CM_ SG_ 950 ac_passengerTempC "Passenger Temperature Celsius
乘客侧设置温度_摄氏度";
CM_ SG_ 950 ac_driverTempF "Driver Temperature Fahrenheit
驾驶侧设置温度_华氏度";
CM_ SG_ 950 ac_passengerTempF "Passenger Temperature Fahrenheit
乘客侧设置温度_华氏度";
CM_ SG_ 950 ac_modeStatus "MODE Status
当前模式";
CM_ SG_ 950 ac_blowerLvStatus "Blower Level Status
当前风量档位";
CM_ SG_ 950 ac_diagInfo "AC diagnostic information.";
CM_ SG_ 529 bcm_ElVent1ErrorStatus "错误信息";
CM_ SG_ 529 bcm_ElVent1OverHeatStatus "过热状态";
CM_ SG_ 529 bcm_ElVent1ElectricalFailureSts "电气缺陷";
CM_ SG_ 529 bcm_ElVent1VoltageStatus "电压状态";
CM_ SG_ 529 bcm_ElVent1EmergencyRunningSts "紧急运行状态";
CM_ SG_ 529 bcm_ElVent1ObstructionDetect "阻塞检测";
CM_ SG_ 529 bcm_ElVent1ObstructionStatus "阻塞状态";
CM_ SG_ 529 bcm_ElVent1ResetStatus "复位状态";
CM_ SG_ 529 bcm_ElVent1CoilStatus "线圈状态";
CM_ SG_ 529 bcm_ElVent1LocationStatus "定位状态";
CM_ SG_ 529 bcm_ElVent1SpeedStatus "速度状态";
CM_ SG_ 529 bcm_ElVent1MotorCurrentLocation "电机当前位置";
CM_ SG_ 529 bcm_ElVent1MotorDrivingDirection "驱动方向";
CM_ SG_ 529 bcm_ElVent1TorqueKeepingSts "保持扭矩";
CM_ SG_ 529 bcm_ElVent1SpecialFunction "特殊功能";
CM_ SG_ 529 bcm_ElVent1LocationActuator "地址执行器";
CM_ SG_ 529 bcm_ElVent1EmengencyStopSwitchSt "急停开关";
CM_ SG_ 529 bcm_ElVent1EmengencyStopSLocatio "急停位置";
CM_ SG_ 529 bcm_ElVent1RotationMode "旋转方式";
CM_ SG_ 529 bcm_ElVent1StopStatus "停止状态";
CM_ SG_ 545 bcm_ElVent2ErrorStatus "错误信息";
CM_ SG_ 545 bcm_ElVent2OverHeatStatus "过热状态";
CM_ SG_ 545 bcm_ElVent2ElectricalFailureSts "电气缺陷";
CM_ SG_ 545 bcm_ElVent2VoltageStatus "电压状态";
CM_ SG_ 545 bcm_ElVent2EmergencyRunningSts "紧急运行状态";
CM_ SG_ 545 bcm_ElVent2ObstructionDetect "阻塞检测";
CM_ SG_ 545 bcm_ElVent2ObstructionStatus "阻塞状态";
CM_ SG_ 545 bcm_ElVent2ResetStatus "复位状态";
CM_ SG_ 545 bcm_ElVent2CoilStatus "线圈状态";
CM_ SG_ 545 bcm_ElVent2LocationStatus "定位状态";
CM_ SG_ 545 bcm_ElVent2SpeedStatus "速度状态";
CM_ SG_ 545 bcm_ElVent2MotorCurrentLocation "电机当前位置";
CM_ SG_ 545 bcm_ElVent2MotorDrivingDirection "驱动方向";
CM_ SG_ 545 bcm_ElVent2TorqueKeepingSts "保持扭矩";
CM_ SG_ 545 bcm_ElVent2SpecialFunction "特殊功能";
CM_ SG_ 545 bcm_ElVent2LocationActuator "地址执行器";
CM_ SG_ 545 bcm_ElVent2EmengencyStopSwitchSt "急停开关";
CM_ SG_ 545 bcm_ElVent2EmengencyStopSLocatio "急停位置";
CM_ SG_ 545 bcm_ElVent2RotationMode "旋转方式";
CM_ SG_ 545 bcm_ElVent2StopStatus "停止状态";
CM_ SG_ 561 bcm_ElVent3ErrorStatus "错误信息";
CM_ SG_ 561 bcm_ElVent3OverHeatStatus "过热状态";
CM_ SG_ 561 bcm_ElVent3ElectricalFailureSts "电气缺陷";
CM_ SG_ 561 bcm_ElVent3VoltageStatus "电压状态";
CM_ SG_ 561 bcm_ElVent3EmergencyRunningSts "紧急运行状态";
CM_ SG_ 561 bcm_ElVent3ObstructionDetect "阻塞检测";
CM_ SG_ 561 bcm_ElVent3ObstructionStatus "阻塞状态";
CM_ SG_ 561 bcm_ElVent3ResetStatus "复位状态";
CM_ SG_ 561 bcm_ElVent3CoilStatus "线圈状态";
CM_ SG_ 561 bcm_ElVent3LocationStatus "定位状态";
CM_ SG_ 561 bcm_ElVent3SpeedStatus "速度状态";
CM_ SG_ 561 bcm_ElVent3MotorCurrentLocation "电机当前位置";
CM_ SG_ 561 bcm_ElVent3MotorDrivingDirection "驱动方向";
CM_ SG_ 561 bcm_ElVent3TorqueKeepingSts "保持扭矩";
CM_ SG_ 561 bcm_ElVent3SpecialFunction "特殊功能";
CM_ SG_ 561 bcm_ElVent3LocationActuator "地址执行器";
CM_ SG_ 561 bcm_ElVent3EmengencyStopSwitchSt "急停开关";
CM_ SG_ 561 bcm_ElVent3EmengencyStopSLocatio "急停位置";
CM_ SG_ 561 bcm_ElVent3RotationMode "旋转方式";
CM_ SG_ 561 bcm_ElVent3StopStatus "停止状态";
CM_ SG_ 577 bcm_ElVent4ErrorStatus "错误信息";
CM_ SG_ 577 bcm_ElVent4OverHeatStatus "过热状态";
CM_ SG_ 577 bcm_ElVent4ElectricalFailureSts "电气缺陷";
CM_ SG_ 577 bcm_ElVent4VoltageStatus "电压状态";
CM_ SG_ 577 bcm_ElVent4EmergencyRunningSts "紧急运行状态";
CM_ SG_ 577 bcm_ElVent4ObstructionDetect "阻塞检测";
CM_ SG_ 577 bcm_ElVent4ObstructionStatus "阻塞状态";
CM_ SG_ 577 bcm_ElVent4ResetStatus "复位状态";
CM_ SG_ 577 bcm_ElVent4CoilStatus "线圈状态";
CM_ SG_ 577 bcm_ElVent4LocationStatus "定位状态";
CM_ SG_ 577 bcm_ElVent4SpeedStatus "速度状态";
CM_ SG_ 577 bcm_ElVent4MotorCurrentLocation "电机当前位置";
CM_ SG_ 577 bcm_ElVent4MotorDrivingDirection "驱动方向";
CM_ SG_ 577 bcm_ElVent4TorqueKeepingSts "保持扭矩";
CM_ SG_ 577 bcm_ElVent4SpecialFunction "特殊功能";
CM_ SG_ 577 bcm_ElVent4LocationActuator "地址执行器";
CM_ SG_ 577 bcm_ElVent4EmengencyStopSwitchSt "急停开关";
CM_ SG_ 577 bcm_ElVent4EmengencyStopSLocatio "急停位置";
CM_ SG_ 577 bcm_ElVent4RotationMode "旋转方式";
CM_ SG_ 577 bcm_ElVent4StopStatus "停止状态";
CM_ SG_ 593 bcm_ElVent5ErrorStatus "错误信息";
CM_ SG_ 593 bcm_ElVent5OverHeatStatus "过热状态";
CM_ SG_ 593 bcm_ElVent5ElectricalFailureSts "电气缺陷";
CM_ SG_ 593 bcm_ElVent5VoltageStatus "电压状态";
CM_ SG_ 593 bcm_ElVent5EmergencyRunningSts "紧急运行状态";
CM_ SG_ 593 bcm_ElVent5ObstructionDetect "阻塞检测";
CM_ SG_ 593 bcm_ElVent5ObstructionStatus "阻塞状态";
CM_ SG_ 593 bcm_ElVent5ResetStatus "复位状态";
CM_ SG_ 593 bcm_ElVent5CoilStatus "线圈状态";
CM_ SG_ 593 bcm_ElVent5LocationStatus "定位状态";
CM_ SG_ 593 bcm_ElVent5SpeedStatus "速度状态";
CM_ SG_ 593 bcm_ElVent5MotorCurrentLocation "电机当前位置";
CM_ SG_ 593 bcm_ElVent5MotorDrivingDirection "驱动方向";
CM_ SG_ 593 bcm_ElVent5TorqueKeepingSts "保持扭矩";
CM_ SG_ 593 bcm_ElVent5SpecialFunction "特殊功能";
CM_ SG_ 593 bcm_ElVent5LocationActuator "地址执行器";
CM_ SG_ 593 bcm_ElVent5EmengencyStopSwitchSt "急停开关";
CM_ SG_ 593 bcm_ElVent5EmengencyStopSLocatio "急停位置";
CM_ SG_ 593 bcm_ElVent5RotationMode "旋转方式";
CM_ SG_ 593 bcm_ElVent5StopStatus "停止状态";
CM_ SG_ 609 bcm_ElVent6ErrorStatus "错误信息";
CM_ SG_ 609 bcm_ElVent6OverHeatStatus "过热状态";
CM_ SG_ 609 bcm_ElVent6ElectricalFailureSts "电气缺陷";
CM_ SG_ 609 bcm_ElVent6VoltageStatus "电压状态";
CM_ SG_ 609 bcm_ElVent6EmergencyRunningSts "紧急运行状态";
CM_ SG_ 609 bcm_ElVent6ObstructionDetect "阻塞检测";
CM_ SG_ 609 bcm_ElVent6ObstructionStatus "阻塞状态";
CM_ SG_ 609 bcm_ElVent6ResetStatus "复位状态";
CM_ SG_ 609 bcm_ElVent6CoilStatus "线圈状态";
CM_ SG_ 609 bcm_ElVent6LocationStatus "定位状态";
CM_ SG_ 609 bcm_ElVent6SpeedStatus "速度状态";
CM_ SG_ 609 bcm_ElVent6MotorCurrentLocation "电机当前位置";
CM_ SG_ 609 bcm_ElVent6MotorDrivingDirection "驱动方向";
CM_ SG_ 609 bcm_ElVent6TorqueKeepingSts "保持扭矩";
CM_ SG_ 609 bcm_ElVent6SpecialFunction "特殊功能";
CM_ SG_ 609 bcm_ElVent6LocationActuator "地址执行器";
CM_ SG_ 609 bcm_ElVent6EmengencyStopSwitchSt "急停开关";
CM_ SG_ 609 bcm_ElVent6EmengencyStopSLocatio "急停位置";
CM_ SG_ 609 bcm_ElVent6RotationMode "旋转方式";
CM_ SG_ 609 bcm_ElVent6StopStatus "停止状态";
CM_ SG_ 625 bcm_ElVent7ErrorStatus "错误信息";
CM_ SG_ 625 bcm_ElVent7OverHeatStatus "过热状态";
CM_ SG_ 625 bcm_ElVent7ElectricalFailureSts "电气缺陷";
CM_ SG_ 625 bcm_ElVent7VoltageStatus "电压状态";
CM_ SG_ 625 bcm_ElVent7EmergencyRunningSts "紧急运行状态";
CM_ SG_ 625 bcm_ElVent7ObstructionDetect "阻塞检测";
CM_ SG_ 625 bcm_ElVent7ObstructionStatus "阻塞状态";
CM_ SG_ 625 bcm_ElVent7ResetStatus "复位状态";
CM_ SG_ 625 bcm_ElVent7CoilStatus "线圈状态";
CM_ SG_ 625 bcm_ElVent7LocationStatus "定位状态";
CM_ SG_ 625 bcm_ElVent7SpeedStatus "速度状态";
CM_ SG_ 625 bcm_ElVent7MotorCurrentLocation "电机当前位置";
CM_ SG_ 625 bcm_ElVent7MotorDrivingDirection "驱动方向";
CM_ SG_ 625 bcm_ElVent7TorqueKeepingSts "保持扭矩";
CM_ SG_ 625 bcm_ElVent7SpecialFunction "特殊功能";
CM_ SG_ 625 bcm_ElVent7LocationActuator "地址执行器";
CM_ SG_ 625 bcm_ElVent7EmengencyStopSwitchSt "急停开关";
CM_ SG_ 625 bcm_ElVent7EmengencyStopSLocatio "急停位置";
CM_ SG_ 625 bcm_ElVent7RotationMode "旋转方式";
CM_ SG_ 625 bcm_ElVent7StopStatus "停止状态";
CM_ SG_ 641 bcm_ElVent8ErrorStatus "错误信息";
CM_ SG_ 641 bcm_ElVent8OverHeatStatus "过热状态";
CM_ SG_ 641 bcm_ElVent8ElectricalFailureSts "电气缺陷";
CM_ SG_ 641 bcm_ElVent8VoltageStatus "电压状态";
CM_ SG_ 641 bcm_ElVent8EmergencyRunningSts "紧急运行状态";
CM_ SG_ 641 bcm_ElVent8ObstructionDetect "阻塞检测";
CM_ SG_ 641 bcm_ElVent8ObstructionStatus "阻塞状态";
CM_ SG_ 641 bcm_ElVent8ResetStatus "复位状态";
CM_ SG_ 641 bcm_ElVent8CoilStatus "线圈状态";
CM_ SG_ 641 bcm_ElVent8LocationStatus "定位状态";
CM_ SG_ 641 bcm_ElVent8SpeedStatus "速度状态";
CM_ SG_ 641 bcm_ElVent8MotorCurrentLocation "电机当前位置";
CM_ SG_ 641 bcm_ElVent8MotorDrivingDirection "驱动方向";
CM_ SG_ 641 bcm_ElVent8TorqueKeepingSts "保持扭矩";
CM_ SG_ 641 bcm_ElVent8SpecialFunction "特殊功能";
CM_ SG_ 641 bcm_ElVent8LocationActuator "地址执行器";
CM_ SG_ 641 bcm_ElVent8EmengencyStopSwitchSt "急停开关";
CM_ SG_ 641 bcm_ElVent8EmengencyStopSLocatio "急停位置";
CM_ SG_ 641 bcm_ElVent8RotationMode "旋转方式";
CM_ SG_ 641 bcm_ElVent8StopStatus "停止状态";
CM_ SG_ 977 bcm_rsm_FwBrightness "前向光值";
CM_ SG_ 977 bcm_rsm_AmbBrightness "车顶环境光值";
CM_ SG_ 977 bcm_rsm_IRBrightness "红外光值";
CM_ SG_ 1018 hud_onOffSts "HUD on off status.";
CM_ SG_ 1018 hud_language "HUD语言";
CM_ SG_ 1170 ic_tripmeter "IC tripmeter.
小计里程";
CM_ SG_ 1170 ic_maintenanceInd "Maintenance indication.
保养提醒";
CM_ SG_ 1170 ic_fatigueDrivingWarnning "fatigue driving warnning
疲劳驾驶提醒";
CM_ SG_ 1170 ic_currentTripmeter "IC current tripmeter.
本次小计里程";
CM_ SG_ 1170 ic_avgSpdTrip "Average vehicle speed since tripmeter reset.
小计平均车速";
CM_ SG_ 1170 ic_avgSpdCurrentTrip "Average vehicle speed of current trip.
本次平均车速";
CM_ SG_ 951 pdc_buzzerAlarmPattern "alarm method of buzzer
蜂鸣器报警方式";
CM_ SG_ 951 pdc_modeStatus "operation mode of parking distance control
泊车雷达的工作模式";
CM_ SG_ 951 pdc_ledIndication "LED indication
泊车雷达LED指示";
CM_ SG_ 951 pdc_voltageAbnormal "Parking radar voltage abnormal.";
CM_ SG_ 951 pdc_distanceFL "Distance display of parking radar in front left side.
No Distance: 60 < Distance
Range 1: Distance <= 35
Range 2: 35 < Distance <= 60
others: reserved";
CM_ SG_ 951 pdc_sensorFaultFL "Front left sensor fault.";
CM_ SG_ 951 pdc_distanceFML "Distance display  of parking radar in front middle left side 
No Distance: 120 < Distance
Range 1: Distance <= 35
Range 2: 35 < Distance <= 60
Range 3: 60 < Distance <= 120
others: reserved";
CM_ SG_ 951 pdc_sensorFaultFML "Front middle left sensor fault.";
CM_ SG_ 951 pdc_distanceFMR "Distance display  of parking radar in front middle right side 
No Distance: 120 < Distance
Range 1: Distance <= 35
Range 2: 35 < Distance <= 60
Range 3: 60 < Distance <= 120
others: reserved";
CM_ SG_ 951 pdc_sensorFaultFMR "Front middle right sensor fault.";
CM_ SG_ 951 pdc_distanceFR "Distance display  of parking radar in front right side 
No Distance: 60 < Distance
Range 1: Distance <= 35
Range 2: 35 < Distance <= 60
others: reserved";
CM_ SG_ 951 pdc_sensorFaultFR "Front right sensor fault.";
CM_ SG_ 951 pdc_distanceRL "Distance display  of parking radar in front left side 
No Distance: 60 < Distance
Range 1: Distance <= 35
Range 2: 35 < Distance <= 60
others: reserved";
CM_ SG_ 951 pdc_sensorFaultRL "Rear left sensor fault.";
CM_ SG_ 951 pdc_distanceRML "Distance display  of parking radar in front middle left side 
No Distance: 150 < Distance
Range 1: Distance <= 35
Range 2: 35 < Distance <= 60
Range 3: 60 < Distance <= 90
Range 4: 60 < Distance <= 150
others: reserved";
CM_ SG_ 951 pdc_sensorFaultRML "Rear middle left sensor fault.";
CM_ SG_ 951 pdc_distanceRMR "Distance display  of parking radar in rear middle right side 
No Distance: 150 < Distance
Range 1: Distance <= 35
Range 2: 35 < Distance <= 60
Range 3: 60 < Distance <= 90
Range 4: 60 < Distance <= 150
others: reserved";
CM_ SG_ 951 pdc_sensorFaultRMR "Rear middle right sensor fault.";
CM_ SG_ 951 pdc_distanceRR "Distance display  of parking radar in rear right side 
No Distance: 60 < Distance
Range 1: Distance <= 35
Range 2: 35 < Distance <= 60
others: reserved";
CM_ SG_ 951 pdc_sensorFaultRR "Rear right sensor fault.";
CM_ SG_ 951 pdc_configInfo "Parking radar configuration.(reserved)";
CM_ SG_ 951 pdc_systemType "Parking radar system type.";
CM_ SG_ 951 pdc_ecuFault "ECU fault.";
CM_ SG_ 951 pdc_canFault "CAN fault.";
CM_ SG_ 116 svc_calibrationState "SVC calibration status.(reserved)
收到标定请求后以500ms周期发送，直到标定状态为0x3或0x4.";
CM_ SG_ 1156 svc_cameraMode "SVC camer mode
SVC画面状态";
CM_ SG_ 1156 svc_workMode "SVC work mode
SVC工作模式";
CM_ SG_ 1156 svc_sysFailureSts "System functional status / failure indication
失效状态";
CM_ SG_ 1041 bcm_tpmsLFStatus "Front left TPMS sensor status.";
CM_ SG_ 1041 bcm_tyreLFPressure "Front left tire pressure.";
CM_ SG_ 1041 bcm_tyreLFTemp "Front left tire temperature.";
CM_ SG_ 1041 bcm_tpmsRFStatus "Front right TPMS sensor status.";
CM_ SG_ 1041 bcm_tyreRFPressure "Front right tire pressure.";
CM_ SG_ 1041 bcm_tyreRFTemp "Front right tire temperature.";
CM_ SG_ 1041 bcm_tpmsLRStatus "Rear left TPMS sensor status.";
CM_ SG_ 1041 bcm_tyreLRPressure "Rear left tire pressure.";
CM_ SG_ 1041 bcm_tyreLRTemp "Rear left tire temperature.";
CM_ SG_ 1041 bcm_tpmsRRStatus "Rear right TPMS sensor status.";
CM_ SG_ 1041 bcm_tyreRRPressure "Rear right tire pressure.";
CM_ SG_ 1041 bcm_tyreRRTemp "Rear right tire temperature.";
CM_ SG_ 1055 ASC_SuspensionHeightMode "当前悬挂系统的工作模式";
CM_ SG_ 1055 ASC_VehicleUpDownStatus "车辆上升下降状态";
CM_ SG_ 1055 ASC_MoveModeStatus "减震器模式";
CM_ SG_ 1055 ASC_WarningLamp "ASC提示故障，点亮故障灯";
CM_ SG_ 1055 ASC_SpeedThresholdValue "当前速度门槛值";
CM_ SG_ 1154 ic_languageSts "Language status.";
CM_ SG_ 1154 ic_minSocWarningSts "Mininum SOC warning value set.";
CM_ SG_ 1300 bms_SOC "State of Charge";
CM_ SG_ 1300 bms_SOH "State of Health";
CM_ SG_ 1300 bms_SOE "State of Energy";
CM_ SG_ 2015 Diag_FuncReq_Data "Diagnostic Functional Request Data.";
CM_ SG_ 324 eps_sasSteeringAngle "SAS steering angle. Left positive, right negtive.";
CM_ SG_ 324 eps_sasSteeringAngleValid "Valid data of signal eps_sasSteeringAngle.";
CM_ SG_ 537 mrr_ccFuntionMode "Cruise Control Function Mode（CC,ACC,TJA/ICA.）";
CM_ SG_ 538 mpc_laneAssitType "Operation mode of LKS";
CM_ SG_ 538 mpc_lasSensitivity "LAS sensitivity";
CM_ SG_ 538 mpc_lasStatus "LAS status";
CM_ SG_ 538 mpc_lasWarningModeSelection "LAS Warning Mode";
CM_ SG_ 538 mpc_slaStatus "RSF function Status.";
CM_ SG_ 538 mpc_slaSpeedLimit "RSF output speed limit";
CM_ SG_ 538 mpc_slaSpeedLimitUnits "RSF output speed limit unit";
CM_ SG_ 555 mrr_r_ctaWarningReqRight "request CTA right side warning element.";
CM_ SG_ 555 mrr_r_bsdLCAWarningReqRight "request BSD/LCA right side warning element.";
CM_ SG_ 555 mrr_r_displayInfo "Display information.";
CM_ SG_ 555 mrr_r_bsdLCASts "BSD LCA switch status.";
CM_ SG_ 555 mrr_r_ctaSts "CTA switch status.";
CM_ SG_ 555 mrr_r_dowSts "DOW switch status.";
CM_ SG_ 555 mrr_r_ctaWarningReqLeft "request CTA Left side warning element.";
CM_ SG_ 555 mrr_r_bsdLCAWarningReqLeft "request BSD/LCA Left side warning element.";
CM_ SG_ 555 mrr_r_rollingCounter "every message increments the counter.";
CM_ SG_ 555 mrr_r_checkSum "CRC8 checksum.";
CM_ SG_ 569 mrr_pedeProtOnOffStatus "Indicating Pedestrain protection function OnOff status.";
CM_ SG_ 569 mrr_aebOnOffStatus "AEB ON OFF status.";
CM_ SG_ 569 mrr_PEBSWarning "PEBSWarning，include PreWarning and emergency Warning";
CM_ SG_ 569 mrr_pcwOnOffStatus "Indicating AEB Warning function OnOff status.";
CM_ SG_ 673 bcm_hoodSts "Hood status.";
CM_ SG_ 673 bcm_leftTurnLampSts "left turn lamp status.";
CM_ SG_ 673 bcm_rightTurnLampSts "right turn lamp status.";
CM_ SG_ 673 bcm_doorFLSts "Front left door status.";
CM_ SG_ 673 bcm_doorFRSts "Front right door status.";
CM_ SG_ 673 bcm_doorRLSts "Rear left door status.";
CM_ SG_ 673 bcm_doorRRSts "Rear right door status.";
CM_ SG_ 673 bcm_doorFLLockSts "Front left door lock status.";
CM_ SG_ 673 bcm_antiTheftSts "Anti-theft status.";
CM_ SG_ 673 bcm_fuelCapSts "Fuel cap status.";
CM_ SG_ 673 bcm_chrgCapSts "Charging cap status.";
CM_ SG_ 705 bcm_pepsPowerMode "Power mode.";
CM_ SG_ 705 bcm_pepsKeyNotInCarInd "Key is not in car indication.
钥匙离开车内提示.";
CM_ SG_ 705 bcm_pepsKeySerchFailInd "Search key failed warning.
未检测到钥匙报警.";
CM_ SG_ 705 bcm_pepsKeyCloserInd "Make the key closer to coil indication.
提示将钥匙靠近线圈.";
CM_ SG_ 705 bcm_pepsFobLowBatWarning "Fob battery low warning.
智能钥匙电池电量低提示";
CM_ SG_ 705 bcm_pepsPowerRelayErrWarning "Power relay error warning.
电源继电器错误提示";
CM_ SG_ 705 bcm_ChildSafetyLockSts "ChildSafetyLockSts
儿童锁状态信号";
CM_ SG_ 705 bcm_esclUnlockFailWarning "ESCL unlock fail warning.
转向柱锁解锁失败报警";
CM_ SG_ 705 bcm_esclLockFailWarning "ESCL lock fail warning.
转向柱锁上锁失败报警";
CM_ SG_ 706 esc_epbStatus "EPB system status.";
CM_ SG_ 706 esc_epbTextDisplayOnIVI "epb text display on IVI
ESC只往IVI上发3s";
CM_ SG_ 754 ic_totalMileage "Total mileage.";
CM_ SG_ 754 ic_themeSts "Current IC theme.";
CM_ SG_ 782 bms_vPackBmu "Current battery pack voltage.";
CM_ SG_ 782 bms_vPackBms "Current battery pack voltage.";
CM_ SG_ 782 bms_iPack "Current battery pack current.";
CM_ SG_ 782 bms_pPack "Current battery pack power.";
CM_ SG_ 878 esc_vehicleSpeed "vehicle reference speed";
CM_ SG_ 878 esc_vehicleSpeedValid "vehicle reference speed valid signal";
CM_ SG_ 878 esc_avhActive "indicates AVH in active or not ";
CM_ SG_ 878 esc_avhStandby "indicates AVH in standby mode or not";
CM_ SG_ 878 esc_avhAvailable "HMI Responsible,CAN get degrateAVH statement from DSW and send out";
CM_ SG_ 878 esc_hdcStatus "indicates HDC control status.";
CM_ SG_ 878 esc_offStatus "ESPOFF SW  close,ESP function passive(PATA)";
CM_ SG_ 878 esc_vlcTorqReq "VLC engine Torque Request";
CM_ SG_ 878 esc_vlcTorqReqActive "VLC engine Torque Request Active";
CM_ SG_ 878 esc_vlcError "Indicate the failure status of VLC";
CM_ SG_ 878 esc_vlcAvalible "Indicating whether VLC is basically ready for activation or not. It could be combined with VLCFail.";
CM_ SG_ 878 esc_vlcInterTargetAx "Internal VLC target acceleration";
CM_ SG_ 878 esc_vlcActive "Indicates VLC is active or not";
CM_ SG_ 878 eps_modeStatus "EPS mode status.";
CM_ SG_ 910 vcu_actualGearValid "Actual gear valid signal.";
CM_ SG_ 910 vcu_actualGear "Actual gear engaged.";
CM_ SG_ 928 vsp_errorStatus "VSP error status check.";
CM_ SG_ 928 vsp_soundEnable "Sound enable or disable.";
CM_ SG_ 928 vsp_errorIdentification "Show sound error.";
CM_ SG_ 941 wcm_chargingStatus "Charging status.
充电状态";
CM_ SG_ 941 wcm_failureStatus "WCM failure status.
故障信息";
CM_ SG_ 941 wcm_onOffFeedback "WCM OnOff status feedback.
无线充电设置反馈";
CM_ SG_ 941 wcm_workingStatus "WCM working status.
无线充电器工作状态";
CM_ SG_ 941 WCM_selfCheckToWCM "WCM selfCheck无线充电器自检";
CM_ SG_ 974 ac_ambientTemp "Ambient Temperature
环境温度";
CM_ SG_ 974 ac_incarTemp "Incar Temperature
车内温度";
CM_ SG_ 974 ac_cabinPtcStatus "PTC Status
PTC工作状态";
CM_ SG_ 974 bcm_rearMirrorSts "Rearview mirror status.";
CM_ SG_ 974 bcm_autoLampSwSts "Auto lamp switch status.";
CM_ SG_ 974 bcm_positionLampSts "Position lamp status.";
CM_ SG_ 974 bcm_lowBeamSts "Low beam status.";
CM_ SG_ 974 bcm_highBeamSts "high beam status.";
CM_ SG_ 974 bcm_sunroofSts "Sunroof status.";
CM_ SG_ 974 bcm_sunshadeSts "Sunshade status.";
CM_ SG_ 974 bcm_rearFogLampSts "rear fog lamp status.";
CM_ SG_ 974 bcm_roofLampSts "Roof lamp status.";
CM_ SG_ 974 bcm_footLampSts "Foot lamp status.";
CM_ SG_ 974 bcm_ambientLightLumiLvSts "Ambient light luminance level status.";
CM_ SG_ 974 bcm_rsmSolarRight "Solar value right side";
CM_ SG_ 974 bcm_rsmSolarLeft "Solar value left side";
CM_ SG_ 990 pot_antipinchWarning "Tailgate antipinch warning.";
CM_ SG_ 990 pot_tailgateOpenSts "Tailgate open status.";
CM_ SG_ 990 pot_antiPlayWarning "Tailgate antiplay warning.";
CM_ SG_ 990 dscu_easyEntryStatus "Easy entry status feedback.";
CM_ SG_ 990 dscu_drSeatMassSts "Driver Seat massage Status";
CM_ SG_ 990 dscu_drSeatHeatSts "Driver seat heating status.";
CM_ SG_ 990 dscu_keyMemoryStatus "Key memory status.";
CM_ SG_ 990 dscu_drSeatVentSts "Driver seat ventilation status";
CM_ SG_ 990 dscu_passSeatMassSts "Passenger Seat massage Status";
CM_ SG_ 990 dscu_passSeatHeatSts "Passenger seat heating status.";
CM_ SG_ 990 dscu_passSeatVentSts "Passenger seat ventilation status";
CM_ SG_ 990 dscu_DSMStatustOutput "记忆模块工作状态
DSM work status";
CM_ SG_ 990 dscu_MemoryAlarm "memory alarm request
记忆提示请求";
CM_ SG_ 990 dscu_MemoryPosition "DSM_Memory Position
记忆当前记忆状态";
BA_DEF_ SG_  "GenSigFilterAlgorithm" ENUM  "Always","Never","MaskNewEquX";
BA_DEF_ SG_  "GenSigSendType" ENUM  "Pending","Triggered";
BA_DEF_ BO_  "DiagRequest" ENUM  "No","Yes";
BA_DEF_ BO_  "DiagResponse" ENUM  "No","Yes";
BA_DEF_ BO_  "DiagState" ENUM  "No","Yes";
BA_DEF_ BO_  "GenMsgCycleTime" INT 0 0;
BA_DEF_ BO_  "GenMsgCycleTimeFast" INT 0 0;
BA_DEF_ BO_  "GenMsgILSupport" ENUM  "No","Yes";
BA_DEF_ BO_  "GenMsgNrOfRepetition" INT 0 0;
BA_DEF_ BO_  "GenMsgSendType" ENUM  "Direct","Mixed","Periodic";
BA_DEF_ BO_  "GenMsgTimeout" INT 0 0;
BA_DEF_ SG_  "SystemSignalLongSymbol" STRING ;
BA_DEF_DEF_  "GenSigFilterAlgorithm" "Always";
BA_DEF_DEF_  "GenSigSendType" "Pending";
BA_DEF_DEF_  "DiagRequest" "No";
BA_DEF_DEF_  "DiagResponse" "No";
BA_DEF_DEF_  "DiagState" "No";
BA_DEF_DEF_  "GenMsgCycleTime" 0;
BA_DEF_DEF_  "GenMsgCycleTimeFast" 0;
BA_DEF_DEF_  "GenMsgILSupport" "Yes";
BA_DEF_DEF_  "GenMsgNrOfRepetition" 0;
BA_DEF_DEF_  "GenMsgSendType" "Periodic";
BA_DEF_DEF_  "GenMsgTimeout" 0;
BA_DEF_DEF_  "SystemSignalLongSymbol" "";
BA_ "GenMsgTimeout" BO_ 965 4000;
BA_ "GenMsgCycleTime" BO_ 965 400;
BA_ "GenMsgSendType" BO_ 165 0;
BA_ "GenMsgNrOfRepetition" BO_ 165 3;
BA_ "GenMsgCycleTimeFast" BO_ 165 20;
BA_ "GenMsgTimeout" BO_ 245 1000;
BA_ "GenMsgSendType" BO_ 245 1;
BA_ "GenMsgNrOfRepetition" BO_ 245 3;
BA_ "GenMsgCycleTimeFast" BO_ 245 50;
BA_ "GenMsgCycleTime" BO_ 245 100;
BA_ "GenMsgTimeout" BO_ 949 1000;
BA_ "GenMsgCycleTime" BO_ 949 100;
BA_ "GenMsgSendType" BO_ 229 0;
BA_ "GenMsgSendType" BO_ 213 0;
BA_ "GenMsgTimeout" BO_ 1013 1000;
BA_ "GenMsgCycleTime" BO_ 1013 100;
BA_ "GenMsgTimeout" BO_ 533 500;
BA_ "GenMsgCycleTime" BO_ 533 50;
BA_ "GenMsgTimeout" BO_ 549 500;
BA_ "GenMsgCycleTime" BO_ 549 50;
BA_ "GenMsgTimeout" BO_ 565 500;
BA_ "GenMsgCycleTime" BO_ 565 50;
BA_ "GenMsgTimeout" BO_ 581 500;
BA_ "GenMsgCycleTime" BO_ 581 50;
BA_ "GenMsgTimeout" BO_ 597 500;
BA_ "GenMsgCycleTime" BO_ 597 50;
BA_ "GenMsgTimeout" BO_ 613 500;
BA_ "GenMsgCycleTime" BO_ 613 50;
BA_ "GenMsgTimeout" BO_ 629 500;
BA_ "GenMsgCycleTime" BO_ 629 50;
BA_ "GenMsgTimeout" BO_ 645 500;
BA_ "GenMsgCycleTime" BO_ 645 50;
BA_ "GenMsgTimeout" BO_ 937 1000;
BA_ "GenMsgCycleTime" BO_ 937 100;
BA_ "GenMsgSendType" BO_ 1829 0;
BA_ "GenMsgILSupport" BO_ 1829 0;
BA_ "DiagState" BO_ 1829 1;
BA_ "DiagRequest" BO_ 1829 1;
BA_ "GenMsgTimeout" BO_ 950 1000;
BA_ "GenMsgCycleTime" BO_ 950 100;
BA_ "GenMsgTimeout" BO_ 529 500;
BA_ "GenMsgCycleTime" BO_ 529 50;
BA_ "GenMsgTimeout" BO_ 545 500;
BA_ "GenMsgCycleTime" BO_ 545 50;
BA_ "GenMsgTimeout" BO_ 561 500;
BA_ "GenMsgCycleTime" BO_ 561 50;
BA_ "GenMsgTimeout" BO_ 577 500;
BA_ "GenMsgCycleTime" BO_ 577 50;
BA_ "GenMsgTimeout" BO_ 593 500;
BA_ "GenMsgCycleTime" BO_ 593 50;
BA_ "GenMsgTimeout" BO_ 609 500;
BA_ "GenMsgCycleTime" BO_ 609 50;
BA_ "GenMsgTimeout" BO_ 625 500;
BA_ "GenMsgCycleTime" BO_ 625 50;
BA_ "GenMsgTimeout" BO_ 641 500;
BA_ "GenMsgCycleTime" BO_ 641 50;
BA_ "GenMsgTimeout" BO_ 977 1000;
BA_ "GenMsgCycleTime" BO_ 977 100;
BA_ "GenMsgTimeout" BO_ 1018 1000;
BA_ "GenMsgCycleTime" BO_ 1018 100;
BA_ "GenMsgTimeout" BO_ 1170 5000;
BA_ "GenMsgCycleTime" BO_ 1170 500;
BA_ "GenMsgTimeout" BO_ 951 1000;
BA_ "GenMsgCycleTime" BO_ 951 100;
BA_ "GenMsgSendType" BO_ 116 0;
BA_ "GenMsgTimeout" BO_ 1156 1000;
BA_ "GenMsgCycleTime" BO_ 1156 100;
BA_ "GenMsgTimeout" BO_ 1041 2000;
BA_ "GenMsgCycleTime" BO_ 1041 200;
BA_ "GenMsgTimeout" BO_ 1055 2000;
BA_ "GenMsgCycleTime" BO_ 1055 200;
BA_ "GenMsgTimeout" BO_ 1154 5000;
BA_ "GenMsgCycleTime" BO_ 1154 500;
BA_ "GenMsgTimeout" BO_ 1300 5000;
BA_ "GenMsgCycleTime" BO_ 1300 1000;
BA_ "GenMsgSendType" BO_ 2015 0;
BA_ "GenMsgILSupport" BO_ 2015 0;
BA_ "DiagState" BO_ 2015 1;
BA_ "DiagRequest" BO_ 2015 1;
BA_ "GenMsgTimeout" BO_ 324 100;
BA_ "GenMsgCycleTime" BO_ 324 10;
BA_ "GenMsgTimeout" BO_ 537 200;
BA_ "GenMsgCycleTime" BO_ 537 20;
BA_ "GenMsgTimeout" BO_ 538 200;
BA_ "GenMsgCycleTime" BO_ 538 20;
BA_ "GenMsgTimeout" BO_ 555 200;
BA_ "GenMsgCycleTime" BO_ 555 20;
BA_ "GenMsgTimeout" BO_ 569 200;
BA_ "GenMsgCycleTime" BO_ 569 20;
BA_ "GenMsgTimeout" BO_ 673 200;
BA_ "GenMsgCycleTime" BO_ 673 20;
BA_ "GenMsgTimeout" BO_ 705 200;
BA_ "GenMsgCycleTime" BO_ 705 20;
BA_ "GenMsgTimeout" BO_ 706 200;
BA_ "GenMsgCycleTime" BO_ 706 20;
BA_ "GenMsgTimeout" BO_ 754 200;
BA_ "GenMsgCycleTime" BO_ 754 20;
BA_ "GenMsgTimeout" BO_ 782 500;
BA_ "GenMsgCycleTime" BO_ 782 50;
BA_ "GenMsgTimeout" BO_ 878 500;
BA_ "GenMsgCycleTime" BO_ 878 50;
BA_ "GenMsgTimeout" BO_ 910 1000;
BA_ "GenMsgCycleTime" BO_ 910 100;
BA_ "GenMsgTimeout" BO_ 928 1000;
BA_ "GenMsgCycleTime" BO_ 928 100;
BA_ "GenMsgTimeout" BO_ 941 1000;
BA_ "GenMsgCycleTime" BO_ 941 100;
BA_ "GenMsgTimeout" BO_ 974 1000;
BA_ "GenMsgCycleTime" BO_ 974 100;
BA_ "GenMsgTimeout" BO_ 990 1000;
BA_ "GenMsgCycleTime" BO_ 990 100;
BA_ "GenSigSendType" SG_ 165 ivi_driveModeSet 1;
BA_ "GenSigSendType" SG_ 165 ivi_travelModeSet 1;
BA_ "GenSigSendType" SG_ 165 ivi_maxChrgSocSet 1;
BA_ "GenSigSendType" SG_ 165 ivi_4wdModeSet 1;
BA_ "GenSigSendType" SG_ 165 ivi_cancelChargeSet 1;
BA_ "GenSigSendType" SG_ 165 ivi_chargeFormSet 1;
BA_ "GenSigSendType" SG_ 165 ivi_engyRcvrOnOffSet 1;
BA_ "GenSigSendType" SG_ 165 ivi_engyRcvrIntensitySet 1;
BA_ "GenSigSendType" SG_ 165 ivi_tractionModeSet 1;
BA_ "GenSigSendType" SG_ 165 ivi_dcdcAutochargeSet 1;
BA_ "GenSigSendType" SG_ 165 ivi_ASCHeightModeSelected 1;
BA_ "GenSigSendType" SG_ 165 ivi_ASCSpeedChangeEnableSwitch 1;
BA_ "GenSigSendType" SG_ 165 ivi_crawlModeSet 1;
BA_ "GenSigSendType" SG_ 165 ivi_ASCSpeedThresholdValueChange 1;
BA_ "GenSigSendType" SG_ 165 ivi_esc_epbButtonRelease 1;
BA_ "GenSigSendType" SG_ 165 ivi_ASCMoveModeControl 1;
BA_ "GenSigSendType" SG_ 165 ivi_enableCreepTorque 1;
BA_ "GenSigSendType" SG_ 165 ivi_chargeModeSet 1;
BA_ "GenSigSendType" SG_ 165 ivi_maxChargeCurrentSet 1;
BA_ "GenSigSendType" SG_ 229 ivi_svcCalibrateStart 1;
BA_ "GenSigSendType" SG_ 229 ivi_svcCaliInfoReq 1;
BA_ "GenSigSendType" SG_ 213 ivi_svcXCoordinate 1;
BA_ "GenSigSendType" SG_ 213 ivi_svcYCoordinate 1;
BA_ "GenSigSendType" SG_ 213 ivi_svcCoTouchMotion 1;
BA_ "GenSigSendType" SG_ 1829 Diag_PhyReq_IVI_Data 1;
BA_ "SystemSignalLongSymbol" SG_ 529 bcm_ElVent1EmengencyStopSwitchSt "bcm_ElVent1EmengencyStopSwitchSts";
BA_ "SystemSignalLongSymbol" SG_ 529 bcm_ElVent1EmengencyStopSLocatio "bcm_ElVent1EmengencyStopSLocation";
BA_ "SystemSignalLongSymbol" SG_ 545 bcm_ElVent2EmengencyStopSwitchSt "bcm_ElVent2EmengencyStopSwitchSts";
BA_ "SystemSignalLongSymbol" SG_ 545 bcm_ElVent2EmengencyStopSLocatio "bcm_ElVent2EmengencyStopSLocation";
BA_ "SystemSignalLongSymbol" SG_ 561 bcm_ElVent3EmengencyStopSwitchSt "bcm_ElVent3EmengencyStopSwitchSts";
BA_ "SystemSignalLongSymbol" SG_ 561 bcm_ElVent3EmengencyStopSLocatio "bcm_ElVent3EmengencyStopSLocation";
BA_ "SystemSignalLongSymbol" SG_ 577 bcm_ElVent4EmengencyStopSwitchSt "bcm_ElVent4EmengencyStopSwitchSts";
BA_ "SystemSignalLongSymbol" SG_ 577 bcm_ElVent4EmengencyStopSLocatio "bcm_ElVent4EmengencyStopSLocation";
BA_ "SystemSignalLongSymbol" SG_ 593 bcm_ElVent5EmengencyStopSwitchSt "bcm_ElVent5EmengencyStopSwitchSts";
BA_ "SystemSignalLongSymbol" SG_ 593 bcm_ElVent5EmengencyStopSLocatio "bcm_ElVent5EmengencyStopSLocation";
BA_ "SystemSignalLongSymbol" SG_ 609 bcm_ElVent6EmengencyStopSwitchSt "bcm_ElVent6EmengencyStopSwitchSts";
BA_ "SystemSignalLongSymbol" SG_ 609 bcm_ElVent6EmengencyStopSLocatio "bcm_ElVent6EmengencyStopSLocation";
BA_ "SystemSignalLongSymbol" SG_ 625 bcm_ElVent7EmengencyStopSwitchSt "bcm_ElVent7EmengencyStopSwitchSts";
BA_ "SystemSignalLongSymbol" SG_ 625 bcm_ElVent7EmengencyStopSLocatio "bcm_ElVent7EmengencyStopSLocation";
BA_ "SystemSignalLongSymbol" SG_ 641 bcm_ElVent8EmengencyStopSwitchSt "bcm_ElVent8EmengencyStopSwitchSts";
BA_ "SystemSignalLongSymbol" SG_ 641 bcm_ElVent8EmengencyStopSLocatio "bcm_ElVent8EmengencyStopSLocation";
BA_ "GenSigSendType" SG_ 116 svc_calibrationState 1;
BA_ "GenSigSendType" SG_ 2015 Diag_FuncReq_Data 1;
VAL_ 965 ivi_naviTextStrLength 63 "Reserved" 62 "Reserved" 61 "Reserved" 60 "Reserved" 59 "Reserved" 58 "Reserved" 57 "Reserved" 56 "Reserved" 55 "Reserved" 54 "Reserved" 53 "Reserved" 52 "Reserved" 51 "Reserved" 50 "Reserved" 49 "Reserved" 48 "Reserved" 47 "Reserved" 46 "Reserved" 45 "Reserved" 44 "Reserved" 43 "Reserved" 42 "Reserved" 41 "Reserved" 40 "Reserved" 39 "Reserved" 38 "Reserved" 37 "Reserved" 36 "Reserved" 35 "Reserved" 34 "Reserved" 33 "Reserved" 32 "Reserved" 31 "Reserved" 30 "道路信息保持" 29 "文本长度1~30" 28 "文本长度1~30" 27 "文本长度1~30" 26 "文本长度1~30" 25 "文本长度1~30" 24 "文本长度1~30" 23 "文本长度1~30" 22 "文本长度1~30" 21 "文本长度1~30" 20 "文本长度1~30" 19 "文本长度1~30" 18 "文本长度1~30" 17 "文本长度1~30" 16 "文本长度1~30" 15 "文本长度1~30" 14 "文本长度1~30" 13 "文本长度1~30" 12 "文本长度1~30" 11 "文本长度1~30" 10 "文本长度1~30" 9 "文本长度1~30" 8 "文本长度1~30" 7 "文本长度1~30" 6 "文本长度1~30" 5 "文本长度1~30" 4 "文本长度1~30" 3 "文本长度1~30" 2 "文本长度1~30" 1 "文本长度1~30" 0 "NO INFO(导航未开启或退出)" ;
VAL_ 965 ivi_naviTextCountNum 15 "Reserved" 14 "Reserved" 13 "Reserved" 12 "Reserved" 11 "Reserved" 10 "数据包编号1~10" 9 "数据包编号1~10" 8 "数据包编号1~10" 7 "数据包编号1~10" 6 "数据包编号1~10" 5 "数据包编号1~10" 4 "数据包编号1~10" 3 "数据包编号1~10" 2 "数据包编号1~10" 1 "数据包编号1~10" 0 "Default" ;
VAL_ 165 ivi_driveModeSet 3 "RESERVE_DRVMODE" 2 "SPORT" 1 "COMFORT" 0 "ECO" ;
VAL_ 165 ivi_travelModeSet 7 "INVALID_TRVLMODE" 6 "RESERVE_TRVLMODE2" 5 "RESERVE_TRVLMODE1" 4 "SNOW" 3 "MUD" 2 "MOUNTAIN" 1 "HIGHWAY" 0 "RESERVE_TRVLMODE0" ;
VAL_ 165 ivi_maxChrgSocSet 255 "Invalid" ;
VAL_ 165 ivi_4wdModeSet 3 "INVALID_4WDMODE" 2 "AWD" 1 "RWD" 0 "FWD" ;
VAL_ 165 ivi_cancelChargeSet 3 "INVALID_CANCLECHRG" 2 "RESERVE_CANCLECHRG" 1 "CANCEL_CHARGEING" 0 "NOT_CANCEL_CHARGING" ;
VAL_ 165 ivi_chargeFormSet 7 "INVALID_CHRGFORM" 6 "RESERVE_CHRGFORM4" 5 "RESERVE_CHRGFORM3" 4 "RESERVE_CHRGFORM2" 3 "LONG_LIFE_CHARGE" 2 "REMOTE_CHARGE" 1 "TIMING_CHARGE" 0 "IMMEDIATE_CHARGE" ;
VAL_ 165 ivi_engyRcvrOnOffSet 3 "INVALID_ONOFFSTS" 2 "RESERVE_ONOFFSTS" 1 "ON_STS" 0 "OFF_STS" ;
VAL_ 165 ivi_engyRcvrIntensitySet 3 "INVALID_ENEGYRCVR" 2 "RESERVE_ENEGYRCVR" 1 "HIGH_ENEGYRCVR" 0 "NORMAL_ENEGYRCVR" ;
VAL_ 165 ivi_tractionModeSet 1 "ON" 0 "OFF" ;
VAL_ 165 ivi_dcdcAutochargeSet 1 "ON" 0 "OFF" ;
VAL_ 165 ivi_ASCHeightModeSelected 7 "RESERVED" 6 "MAINTENANCE MODE" 5 "RESERVED" 4 "LOE MODE" 3 "NORMAL MODE" 2 "HIGH MODE" 1 "VERY HIGH MODE" 0 "NO MODE" ;
VAL_ 165 ivi_ASCSpeedChangeEnableSwitch 1 "SPEED SWITCH ENABLE" 0 "NO MODE" ;
VAL_ 165 ivi_crawlModeSet 3 "INVALID_ONOFFSTS" 2 "RESERVE_ONOFFSTS" 1 "ON_STS" 0 "OFF_STS" ;
VAL_ 165 ivi_ASCSpeedThresholdValueChange 255 "NEVER" 160 "160 km/h" 80 "80 km/h" 0 "ALWAYS" ;
VAL_ 165 ivi_esc_epbButtonRelease 1 "REQUEST" 0 "NO REQUEST" ;
VAL_ 165 ivi_ASCMoveModeControl 2 "MOVEMENT" 1 "AUTO" 0 "COMFORT" ;
VAL_ 165 ivi_enableCreepTorque 1 "ON" 0 "OFF" ;
VAL_ 165 ivi_chargeModeSet 3 "INVALID_CHRGMODE" 2 "FAST_CHARGE" 1 "SLOW_CHARGE" 0 "NO_CHARGE" ;
VAL_ 165 ivi_maxChargeCurrentSet 0 "Invalid" ;
VAL_ 245 ivi_easyEntrySet 3 "INVALID" 1 "ON" 0 "OFF" ;
VAL_ 245 ivi_drSeatVentLevelSet 7 "INVALID" 5 "Level 5" 4 "Level 4" 3 "Level 3" 2 "Level 2" 1 "Level 1" ;
VAL_ 245 ivi_passSeatHeatOnOffSet 3 "INVALID" 1 "ON" 0 "OFF" ;
VAL_ 245 ivi_passSeatVentOnOffSet 3 "INVALID" 1 "ON" 0 "OFF" ;
VAL_ 245 ivi_passSeatHeatLevelSet 7 "INVALID" 3 "Level 3" 2 "Level 2" 1 "Level 1" ;
VAL_ 245 ivi_drSeatHeatOnOffSet 3 "INVALID" 1 "ON" 0 "OFF" ;
VAL_ 245 ivi_passSeatVentLevelSet 7 "INVALID" 5 "Level 5" 4 "Level 4" 3 "Level 3" 2 "Level 2" 1 "Level 1" ;
VAL_ 245 ivi_passSeatMassOnOffSet 3 "INVALID" 1 "ON" 0 "OFF" ;
VAL_ 245 ivi_drSeatMassLevelSet 7 "INVALID" 3 "Level 3" 2 "Level 2" 1 "Level 1" ;
VAL_ 245 ivi_passSeatMassLevelSet 7 "INVALID" 3 "Level 3" 2 "Level 2" 1 "Level 1" ;
VAL_ 245 ivi_mirrorSet 3 "INVALID" 1 "ON" 0 "OFF" ;
VAL_ 245 ivi_memorySet 3 "INVALID" 1 "ON" 0 "OFF" ;
VAL_ 245 ivi_memoryNumSet 3 "INVALID" 2 "NUM_3" 1 "NUM_2" 0 "NUM_1" ;
VAL_ 245 ivi_drSeatVentOnOffSet 3 "INVALID" 1 "ON" 0 "OFF" ;
VAL_ 245 ivi_dsmSetMemoryReq 7 "Reserved" 6 "Reserved" 5 "5 POSITION" 4 "4 POSITION" 3 "3 POSITION" 2 "2 POSITION" 1 "1 POSITION" 0 "NO REQUEST" ;
VAL_ 245 ivi_dsmGetMemoryReq 7 "Reserved" 6 "Reserved" 5 "5 POSITION" 4 "4 POSITION" 3 "3 POSITION" 2 "2 POSITION" 1 "1 POSITION" 0 "NO REQUEST" ;
VAL_ 245 ivi_drSeatMassOnOffSet 3 "INVALID" 1 "ON" 0 "OFF" ;
VAL_ 245 ivi_drSeatHeatLevelSet 7 "INVALID" 3 "Level 3" 2 "Level 2" 1 "Level 1" ;
VAL_ 949 ivi_hvacDefrostMode 1 "KEY_PRESS" 0 "INVALID" ;
VAL_ 949 ivi_hvacOnOffReq 1 "KEY_PRESS" 0 "INVALID" ;
VAL_ 949 ivi_passengerTempFSet 63 "Invalid" ;
VAL_ 949 ivi_hvacModeReq 7 "INVALID" 4 "DEFROST" 3 "FOOT_AND_DEFROST" 2 "FOOT" 1 "FACE_AND_FOOT" 0 "FACE" ;
VAL_ 949 ivi_driverTempCSet 63 "Invalid" ;
VAL_ 949 ivi_driverTempFSet 63 "Invalid" ;
VAL_ 949 ivi_hvacBlowLvReq 7 "LEVEL_7" 6 "LEVEL_6" 5 "LEVEL_5" 4 "LEVEL_4" 3 "LEVEL_3" 2 "LEVEL_2" 1 "LEVEL_1" 0 "OFF" ;
VAL_ 949 ivi_passengerTempCSet 63 "Invalid" ;
VAL_ 949 ivi_hvacDualMode 1 "KEY_PRESS" 0 "INVALID" ;
VAL_ 949 ivi_hvacPTCReq 1 "KEY_PRESS" 0 "INVALID" ;
VAL_ 949 ivi_acReq 1 "KEY_PRESS" 0 "INVALID" ;
VAL_ 949 ivi_svcCameraModeSet 15 "RESERVED" 14 "RESERVED" 13 "RESERVED" 12 "RESERVED" 11 "RESERVED" 10 "RESERVED" 9 "RESERVED" 8 "RESERVED" 7 "RESERVED" 6 "RESERVED" 5 "CAMERAMODE5(2D 俯视图 + 3D全景视图)" 4 "CAMERAMODE4(2D 俯视图 + 2D右视图)" 3 "CAMERAMODE3(2D 俯视图 + 2D左视图)" 2 "CAMERAMODE2(2D 俯视图 + 2D后视图)" 1 "CAMERAMODE1(2D 俯视图 + 2D前视图)" 0 "INACTIVE" ;
VAL_ 949 ivi_acDiagReq 1 "REQUEST" 0 "INVALID" ;
VAL_ 949 ivi_svcFrontTrackDispSet 1 "ON" 0 "OFF" ;
VAL_ 949 ivi_svcRvrsTrackDispSet 1 "ON" 0 "OFF" ;
VAL_ 949 ivi_svcOutMirrorTrackDispSet 1 "ON" 0 "OFF" ;
VAL_ 949 ivi_svcOnOffSw 1 "ON" 0 "OFF" ;
VAL_ 949 ivi_svcSteerInteractionSet 1 "ON" 0 "OFF" ;
VAL_ 949 ivi_languageSet 3 "NO_COMMAND" 2 "RESERVED" 1 "ENGLISH" 0 "SIMPLIFIED_CHINESE" ;
VAL_ 949 ivi_unitSet 3 "INVALID" 1 "MILE" 0 "KM" ;
VAL_ 949 ivi_hvacAutoModeReq 1 "KEY_PRESS" 0 "INVALID" ;
VAL_ 949 ivi_hvacRecircModeReq 1 "KEY_PRESS" 0 "INVALID" ;
VAL_ 229 ivi_svcCaliInfoReq 1 "REQUEST" 0 "NO_REQUEST" ;
VAL_ 213 ivi_svcCoTouchMotion 1 "TOUCH_DOWN" 0 "RELEASE" ;
VAL_ 1013 ivi_longitude 4095 "Invalid" ;
VAL_ 1013 ivi_latitude 4095 "Invalid" ;
VAL_ 533 ivi_ElVent1LocationActuator 255 "Invalid" ;
VAL_ 533 ivi_ElVent1ObstructionCheck 3 "INVALID" 2 "RESERVED" 1 "CLOSED" 0 "OBSTRUCTED" ;
VAL_ 533 ivi_ElVent1MarkClear 15 "Invalid" ;
VAL_ 533 ivi_ElVent1CoilElectrify 3 "INVALID" 2 "RESERVED" 1 "COIL" 0 "COIL OBSTRUCTED" ;
VAL_ 533 ivi_ElVent1LocationSelect 3 "INVALID" 2 "RESERVED" 1 "ORIGINAL LOCATION VALID" 0 "TARGET LOCATION VALID" ;
VAL_ 533 ivi_ElVent1SpeedMode 15 "INVALID" 5 "AUTO CHANGE SPEED" 4 "SPEED4" 3 "SPEED3" 2 "SPEED 2" 1 "SPEED 1" 0 "RESERVED" ;
VAL_ 533 ivi_ElVent1MotorTargetLocation 65535 "Invalid" ;
VAL_ 533 ivi_ElVent1MotorOriginalLocation 65535 "Invalid" ;
VAL_ 533 ivi_ElVent1EmergencyStopSwitch 3 "INVALID" 2 "RESERVED" 1 "OPEN EMERGENCY RUNNING" 0 "CLOSE EMERGENCY RUNNING" ;
VAL_ 533 ivi_ElVent1EmergencyStopLocation 3 "INVALID" 2 "RESERVED" 1 "TOP BRAKE" 0 "BOTTOM BRAKE" ;
VAL_ 533 ivi_ElVent1RotationMode 3 "INVALID" 2 "RESERVED" 1 "MOVE ON CCW DIRECTION" 0 "MOVE ON CW DIRECTION" ;
VAL_ 533 ivi_ElVent1StopMode 3 "INVALID" 2 "RESERVED" 1 "STOP MODE" 0 "NORMAL MODE" ;
VAL_ 533 ivi_ElVent1ProgrammingDataSave 3 "INVALID" 2 "RESERVED" 1 "PROGRAMMING DATA SAVED" 0 "PROGRAMMING DATA UNSAVED" ;
VAL_ 549 ivi_ElVent2LocationActuator 255 "Invalid" ;
VAL_ 549 ivi_ElVent2ObstructionCheck 3 "INVALID" 2 "RESERVED" 1 "CLOSED" 0 "OBSTRUCTED" ;
VAL_ 549 ivi_ElVent2MarkClear 15 "Invalid" ;
VAL_ 549 ivi_ElVent2CoilElectrify 3 "INVALID" 2 "RESERVED" 1 "COIL" 0 "COIL OBSTRUCTED" ;
VAL_ 549 ivi_ElVent2LocationSelect 3 "INVALID" 2 "RESERVED" 1 "ORIGINAL LOCATION VALID" 0 "TARGET LOCATION VALID" ;
VAL_ 549 ivi_ElVent2SpeedMode 15 "INVALID" 5 "AUTO CHANGE SPEED" 4 "SPEED4" 3 "SPEED3" 2 "SPEED 2" 1 "SPEED 1" 0 "RESERVED" ;
VAL_ 549 ivi_ElVent2MotorTargetLocation 65535 "Invalid" ;
VAL_ 549 ivi_ElVent2MotorOriginalLocation 65535 "Invalid" ;
VAL_ 549 ivi_ElVent2EmergencyStopSwitch 3 "INVALID" 2 "RESERVED" 1 "OPEN EMERGENCY RUNNING" 0 "CLOSE EMERGENCY RUNNING" ;
VAL_ 549 ivi_ElVent2EmergencyStopLocation 3 "INVALID" 2 "RESERVED" 1 "TOP BRAKE" 0 "BOTTOM BRAKE" ;
VAL_ 549 ivi_ElVent2RotationMode 3 "INVALID" 2 "RESERVED" 1 "MOVE ON CCW DIRECTION" 0 "MOVE ON CW DIRECTION" ;
VAL_ 549 ivi_ElVent2StopMode 3 "INVALID" 2 "RESERVED" 1 "STOP MODE" 0 "NORMAL MODE" ;
VAL_ 549 ivi_ElVent2ProgrammingDataSave 3 "INVALID" 2 "RESERVED" 1 "PROGRAMMING DATA SAVED" 0 "PROGRAMMING DATA UNSAVED" ;
VAL_ 565 ivi_ElVent3LocationActuator 255 "Invalid" ;
VAL_ 565 ivi_ElVent3ObstructionCheck 3 "INVALID" 2 "RESERVED" 1 "CLOSED" 0 "OBSTRUCTED" ;
VAL_ 565 ivi_ElVent3MarkClear 15 "Invalid" ;
VAL_ 565 ivi_ElVent3CoilElectrify 3 "INVALID" 2 "RESERVED" 1 "COIL" 0 "COIL OBSTRUCTED" ;
VAL_ 565 ivi_ElVent3LocationSelect 3 "INVALID" 2 "RESERVED" 1 "ORIGINAL LOCATION VALID" 0 "TARGET LOCATION VALID" ;
VAL_ 565 ivi_ElVent3SpeedMode 15 "INVALID" 5 "AUTO CHANGE SPEED" 4 "SPEED4" 3 "SPEED3" 2 "SPEED 2" 1 "SPEED 1" 0 "RESERVED" ;
VAL_ 565 ivi_ElVent3MotorTargetLocation 65535 "Invalid" ;
VAL_ 565 ivi_ElVent3MotorOriginalLocation 65535 "Invalid" ;
VAL_ 565 ivi_ElVent3EmergencyStopSwitch 3 "INVALID" 2 "RESERVED" 1 "OPEN EMERGENCY RUNNING" 0 "CLOSE EMERGENCY RUNNING" ;
VAL_ 565 ivi_ElVent3EmergencyStopLocation 3 "INVALID" 2 "RESERVED" 1 "TOP BRAKE" 0 "BOTTOM BRAKE" ;
VAL_ 565 ivi_ElVent3RotationMode 3 "INVALID" 2 "RESERVED" 1 "MOVE ON CCW DIRECTION" 0 "MOVE ON CW DIRECTION" ;
VAL_ 565 ivi_ElVent3StopMode 3 "INVALID" 2 "RESERVED" 1 "STOP MODE" 0 "NORMAL MODE" ;
VAL_ 565 ivi_ElVent3ProgrammingDataSave 3 "INVALID" 2 "RESERVED" 1 "PROGRAMMING DATA SAVED" 0 "PROGRAMMING DATA UNSAVED" ;
VAL_ 581 ivi_ElVent4LocationActuator 255 "Invalid" ;
VAL_ 581 ivi_ElVent4ObstructionCheck 3 "INVALID" 2 "RESERVED" 1 "CLOSED" 0 "OBSTRUCTED" ;
VAL_ 581 ivi_ElVent4MarkClear 15 "Invalid" ;
VAL_ 581 ivi_ElVent4CoilElectrify 3 "INVALID" 2 "RESERVED" 1 "COIL" 0 "COIL OBSTRUCTED" ;
VAL_ 581 ivi_ElVent4LocationSelect 3 "INVALID" 2 "RESERVED" 1 "ORIGINAL LOCATION VALID" 0 "TARGET LOCATION VALID" ;
VAL_ 581 ivi_ElVent4SpeedMode 15 "INVALID" 5 "AUTO CHANGE SPEED" 4 "SPEED4" 3 "SPEED3" 2 "SPEED 2" 1 "SPEED 1" 0 "RESERVED" ;
VAL_ 581 ivi_ElVent4MotorTargetLocation 65535 "Invalid" ;
VAL_ 581 ivi_ElVent4MotorOriginalLocation 65535 "Invalid" ;
VAL_ 581 ivi_ElVent4EmergencyStopSwitch 3 "INVALID" 2 "RESERVED" 1 "OPEN EMERGENCY RUNNING" 0 "CLOSE EMERGENCY RUNNING" ;
VAL_ 581 ivi_ElVent4EmergencyStopLocation 3 "INVALID" 2 "RESERVED" 1 "TOP BRAKE" 0 "BOTTOM BRAKE" ;
VAL_ 581 ivi_ElVent4RotationMode 3 "INVALID" 2 "RESERVED" 1 "MOVE ON CCW DIRECTION" 0 "MOVE ON CW DIRECTION" ;
VAL_ 581 ivi_ElVent4StopMode 3 "INVALID" 2 "RESERVED" 1 "STOP MODE" 0 "NORMAL MODE" ;
VAL_ 581 ivi_ElVent4ProgrammingDataSave 3 "INVALID" 2 "RESERVED" 1 "PROGRAMMING DATA SAVED" 0 "PROGRAMMING DATA UNSAVED" ;
VAL_ 597 ivi_ElVent5LocationActuator 255 "Invalid" ;
VAL_ 597 ivi_ElVent5ObstructionCheck 3 "INVALID" 2 "RESERVED" 1 "CLOSED" 0 "OBSTRUCTED" ;
VAL_ 597 ivi_ElVent5MarkClear 15 "Invalid" ;
VAL_ 597 ivi_ElVent5CoilElectrify 3 "INVALID" 2 "RESERVED" 1 "COIL" 0 "COIL OBSTRUCTED" ;
VAL_ 597 ivi_ElVent5LocationSelect 3 "INVALID" 2 "RESERVED" 1 "ORIGINAL LOCATION VALID" 0 "TARGET LOCATION VALID" ;
VAL_ 597 ivi_ElVent5SpeedMode 15 "INVALID" 5 "AUTO CHANGE SPEED" 4 "SPEED4" 3 "SPEED3" 2 "SPEED 2" 1 "SPEED 1" 0 "RESERVED" ;
VAL_ 597 ivi_ElVent5MotorTargetLocation 65535 "Invalid" ;
VAL_ 597 ivi_ElVent5MotorOriginalLocation 65535 "Invalid" ;
VAL_ 597 ivi_ElVent5EmergencyStopSwitch 3 "INVALID" 2 "RESERVED" 1 "OPEN EMERGENCY RUNNING" 0 "CLOSE EMERGENCY RUNNING" ;
VAL_ 597 ivi_ElVent5EmergencyStopLocation 3 "INVALID" 2 "RESERVED" 1 "TOP BRAKE" 0 "BOTTOM BRAKE" ;
VAL_ 597 ivi_ElVent5RotationMode 3 "INVALID" 2 "RESERVED" 1 "MOVE ON CCW DIRECTION" 0 "MOVE ON CW DIRECTION" ;
VAL_ 597 ivi_ElVent5StopMode 3 "INVALID" 2 "RESERVED" 1 "STOP MODE" 0 "NORMAL MODE" ;
VAL_ 597 ivi_ElVent5ProgrammingDataSave 3 "INVALID" 2 "RESERVED" 1 "PROGRAMMING DATA SAVED" 0 "PROGRAMMING DATA UNSAVED" ;
VAL_ 613 ivi_ElVent6LocationActuator 255 "Invalid" ;
VAL_ 613 ivi_ElVent6ObstructionCheck 3 "INVALID" 2 "RESERVED" 1 "CLOSED" 0 "OBSTRUCTED" ;
VAL_ 613 ivi_ElVent6MarkClear 15 "Invalid" ;
VAL_ 613 ivi_ElVent6CoilElectrify 3 "INVALID" 2 "RESERVED" 1 "COIL" 0 "COIL OBSTRUCTED" ;
VAL_ 613 ivi_ElVent6LocationSelect 3 "INVALID" 2 "RESERVED" 1 "ORIGINAL LOCATION VALID" 0 "TARGET LOCATION VALID" ;
VAL_ 613 ivi_ElVent6SpeedMode 15 "INVALID" 5 "AUTO CHANGE SPEED" 4 "SPEED4" 3 "SPEED3" 2 "SPEED 2" 1 "SPEED 1" 0 "RESERVED" ;
VAL_ 613 ivi_ElVent6MotorTargetLocation 65535 "Invalid" ;
VAL_ 613 ivi_ElVent6MotorOriginalLocation 65535 "Invalid" ;
VAL_ 613 ivi_ElVent6EmergencyStopSwitch 3 "INVALID" 2 "RESERVED" 1 "OPEN EMERGENCY RUNNING" 0 "CLOSE EMERGENCY RUNNING" ;
VAL_ 613 ivi_ElVent6EmergencyStopLocation 3 "INVALID" 2 "RESERVED" 1 "TOP BRAKE" 0 "BOTTOM BRAKE" ;
VAL_ 613 ivi_ElVent6RotationMode 3 "INVALID" 2 "RESERVED" 1 "MOVE ON CCW DIRECTION" 0 "MOVE ON CW DIRECTION" ;
VAL_ 613 ivi_ElVent6StopMode 3 "INVALID" 2 "RESERVED" 1 "STOP MODE" 0 "NORMAL MODE" ;
VAL_ 613 ivi_ElVent6ProgrammingDataSave 3 "INVALID" 2 "RESERVED" 1 "PROGRAMMING DATA SAVED" 0 "PROGRAMMING DATA UNSAVED" ;
VAL_ 629 ivi_ElVent7LocationActuator 255 "Invalid" ;
VAL_ 629 ivi_ElVent7ObstructionCheck 3 "INVALID" 2 "RESERVED" 1 "CLOSED" 0 "OBSTRUCTED" ;
VAL_ 629 ivi_ElVent7MarkClear 15 "Invalid" ;
VAL_ 629 ivi_ElVent7CoilElectrify 3 "INVALID" 2 "RESERVED" 1 "COIL" 0 "COIL OBSTRUCTED" ;
VAL_ 629 ivi_ElVent7LocationSelect 3 "INVALID" 2 "RESERVED" 1 "ORIGINAL LOCATION VALID" 0 "TARGET LOCATION VALID" ;
VAL_ 629 ivi_ElVent7SpeedMode 15 "INVALID" 5 "AUTO CHANGE SPEED" 4 "SPEED4" 3 "SPEED3" 2 "SPEED 2" 1 "SPEED 1" 0 "RESERVED" ;
VAL_ 629 ivi_ElVent7MotorTargetLocation 65535 "Invalid" ;
VAL_ 629 ivi_ElVent7MotorOriginalLocation 65535 "Invalid" ;
VAL_ 629 ivi_ElVent7EmergencyStopSwitch 3 "INVALID" 2 "RESERVED" 1 "OPEN EMERGENCY RUNNING" 0 "CLOSE EMERGENCY RUNNING" ;
VAL_ 629 ivi_ElVent7EmergencyStopLocation 3 "INVALID" 2 "RESERVED" 1 "TOP BRAKE" 0 "BOTTOM BRAKE" ;
VAL_ 629 ivi_ElVent7RotationMode 3 "INVALID" 2 "RESERVED" 1 "MOVE ON CCW DIRECTION" 0 "MOVE ON CW DIRECTION" ;
VAL_ 629 ivi_ElVent7StopMode 3 "INVALID" 2 "RESERVED" 1 "STOP MODE" 0 "NORMAL MODE" ;
VAL_ 629 ivi_ElVent7ProgrammingDataSave 3 "INVALID" 2 "RESERVED" 1 "PROGRAMMING DATA SAVED" 0 "PROGRAMMING DATA UNSAVED" ;
VAL_ 645 ivi_ElVent8LocationActuator 255 "Invalid" ;
VAL_ 645 ivi_ElVent8ObstructionCheck 3 "INVALID" 2 "RESERVED" 1 "CLOSED" 0 "OBSTRUCTED" ;
VAL_ 645 ivi_ElVent8MarkClear 15 "Invalid" ;
VAL_ 645 ivi_ElVent8CoilElectrify 3 "INVALID" 2 "RESERVED" 1 "COIL" 0 "COIL OBSTRUCTED" ;
VAL_ 645 ivi_ElVent8LocationSelect 3 "INVALID" 2 "RESERVED" 1 "ORIGINAL LOCATION VALID" 0 "TARGET LOCATION VALID" ;
VAL_ 645 ivi_ElVent8SpeedMode 15 "INVALID" 5 "AUTO CHANGE SPEED" 4 "SPEED4" 3 "SPEED3" 2 "SPEED 2" 1 "SPEED 1" 0 "RESERVED" ;
VAL_ 645 ivi_ElVent8MotorTargetLocation 65535 "Invalid" ;
VAL_ 645 ivi_ElVent8MotorOriginalLocation 65535 "Invalid" ;
VAL_ 645 ivi_ElVent8EmergencyStopSwitch 3 "INVALID" 2 "RESERVED" 1 "OPEN EMERGENCY RUNNING" 0 "CLOSE EMERGENCY RUNNING" ;
VAL_ 645 ivi_ElVent8EmergencyStopLocation 3 "INVALID" 2 "RESERVED" 1 "TOP BRAKE" 0 "BOTTOM BRAKE" ;
VAL_ 645 ivi_ElVent8RotationMode 3 "INVALID" 2 "RESERVED" 1 "MOVE ON CCW DIRECTION" 0 "MOVE ON CW DIRECTION" ;
VAL_ 645 ivi_ElVent8StopMode 3 "INVALID" 2 "RESERVED" 1 "STOP MODE" 0 "NORMAL MODE" ;
VAL_ 645 ivi_ElVent8ProgrammingDataSave 3 "INVALID" 2 "RESERVED" 1 "PROGRAMMING DATA SAVED" 0 "PROGRAMMING DATA UNSAVED" ;
VAL_ 937 dvr_workStatus 15 "SYS_FAULT" 14 "OFF" 13 "FILE_PLAY_FINISH" 10 "PICTURE_PLAY" 9 "VIDEO_PAUSE" 8 "VIDEO_PLAY" 7 "GALLERY_FILE_LIST" 6 "URGENCY_VIDEO_LIST" 5 "NORMAL_VIDEO_LIST" 4 "AUTO_URGENCY_RECORD" 3 "MANUAL_URGENCY_RECORD" 2 "RECORD_STOP" 1 "NORMAL_RECORD" 0 "INITIAL" ;
VAL_ 937 dvr_sdCardStatus 15 "INVALID" 8 "NEED_FORMATTED" 7 "SD_CARD_PROTECTED" 6 "URGENCY_VID_AND_PIC_FULL" 5 "PICTURE_FULL" 4 "URGENCY_VIDEO_FULL" 3 "SD_CARD_FULL" 2 "SD_CARD_FAULT" 1 "SD_CARD_OUT" 0 "SD_CARD_IN" ;
VAL_ 937 dvr_recordVideoQuality 3 "INVALID" 2 "720P_30FPS" 1 "1080P_30FPS" 0 "INITIAL" ;
VAL_ 937 dvr_muteRecordStatus 3 "INVALID" 2 "VOICE_REC_ON" 1 "VOICE_REC_OFF" 0 "INITIAL" ;
VAL_ 937 dvr_recordTime 3 "5_MINUTES" 2 "3_MINUTES" 1 "1_MINUTE" 0 "INITIAL" ;
VAL_ 937 dvr_collideSensitivityStatus 3 "HIGH_SENSITIVITY" 2 "MID_SENSITIVITY" 1 "LOW_SENSITIVITY" 0 "INITIAL" ;
VAL_ 937 dvr_updateStatus 3 "UPDATA DSP&MCU SOFTWARE" 2 "UPDATA MCU SOFTWARE" 1 "UPDATA DSP SOFTWARE" 0 "INITIAL" ;
VAL_ 937 dvr_parkingMonitor 3 "INVALID" 2 "PARK_MONITOR_ON" 1 "PARK_MONITOR_OFF" 0 "INITIAL" ;
VAL_ 937 dvr_Language 3 "INVALID" 2 "ENGLISH" 1 "CHINESE" 0 "INITIAL" ;
VAL_ 937 dvr_systemVersionB 15 "Invalid" 14 "Invalid" 13 "Invalid" 12 "Invalid" 11 "Invalid" 10 "Invalid" ;
VAL_ 937 dvr_systemVersionC 15 "Invalid" 14 "Invalid" 13 "Invalid" 12 "Invalid" 11 "Invalid" 10 "Invalid" ;
VAL_ 937 dvr_updateSchedule 127 "INITIAL" 126 "UPDATA SUCCESSFUL" 125 "UPDATA FAILED" 100 "0%~100%" 99 "0%~100%" 98 "0%~100%" 97 "0%~100%" 96 "0%~100%" 95 "0%~100%" 94 "0%~100%" 93 "0%~100%" 92 "0%~100%" 91 "0%~100%" 90 "0%~100%" 89 "0%~100%" 88 "0%~100%" 87 "0%~100%" 86 "0%~100%" 85 "0%~100%" 84 "0%~100%" 83 "0%~100%" 82 "0%~100%" 81 "0%~100%" 80 "0%~100%" 79 "0%~100%" 78 "0%~100%" 77 "0%~100%" 76 "0%~100%" 75 "0%~100%" 74 "0%~100%" 73 "0%~100%" 72 "0%~100%" 71 "0%~100%" 70 "0%~100%" 69 "0%~100%" 68 "0%~100%" 67 "0%~100%" 66 "0%~100%" 65 "0%~100%" 64 "0%~100%" 63 "0%~100%" 62 "0%~100%" 61 "0%~100%" 60 "0%~100%" 59 "0%~100%" 58 "0%~100%" 57 "0%~100%" 56 "0%~100%" 55 "0%~100%" 54 "0%~100%" 53 "0%~100%" 52 "0%~100%" 51 "0%~100%" 50 "0%~100%" 49 "0%~100%" 48 "0%~100%" 47 "0%~100%" 46 "0%~100%" 45 "0%~100%" 44 "0%~100%" 43 "0%~100%" 42 "0%~100%" 41 "0%~100%" 40 "0%~100%" 39 "0%~100%" 38 "0%~100%" 37 "0%~100%" 36 "0%~100%" 35 "0%~100%" 34 "0%~100%" 33 "0%~100%" 32 "0%~100%" 31 "0%~100%" 30 "0%~100%" 29 "0%~100%" 28 "0%~100%" 27 "0%~100%" 26 "0%~100%" 25 "0%~100%" 24 "0%~100%" 23 "0%~100%" 22 "0%~100%" 21 "0%~100%" 20 "0%~100%" 19 "0%~100%" 18 "0%~100%" 17 "0%~100%" 16 "0%~100%" 15 "0%~100%" 14 "0%~100%" 13 "0%~100%" 12 "0%~100%" 11 "0%~100%" 10 "0%~100%" 9 "0%~100%" 8 "0%~100%" 7 "0%~100%" 6 "0%~100%" 5 "0%~100%" 4 "0%~100%" 3 "0%~100%" 2 "0%~100%" 1 "0%~100%" 0 "0%~100%" ;
VAL_ 937 dvr_commandRespList 31 "FILESSELECTED 9" 30 "FILESSELECTED 8" 29 "FILESSELECTED 7" 28 "FILESSELECTED 6" 27 "FILESSELECTED 5" 26 "FILESSELECTED 4" 25 "FILESSELECTED 3" 24 "FILESSELECTED 2" 23 "FILESSELECTED 1" 22 "ENTER_UPDATE_MODE" 21 "NEXT_PAGE" 20 "PRE_PAGE" 19 "FORWARD" 18 "FALL_BACK" 17 "DESELECTION" 16 "SELECT_ALL" 15 "EXIT_PLAY" 14 "PLAY_NEXT_FILE" 13 "PLAY_PREV_FILE" 12 "FILE_PLAY_PAUSE" 11 "DELETE_FILE" 10 "MOVE_FILE" 9 "TAKE_PIC" 8 "FACTORY_RESET" 7 "SDCARD_FORMAT" 6 "ENTER_PIC_FOLDER" 5 "ENTER_URGENCY_VIDEO_FOLDER" 4 "ENTER_REALTIME_VIDEO_FOLDER" 3 "ENTER_URGENCY_RECORD" 2 "STOP_RECORD" 1 "ENTER_REALTIME_RECORD" 0 "INITIAL" ;
VAL_ 950 ac_systemOnOffSts 1 "ON" 0 "OFF" ;
VAL_ 950 ac_autoStatus 1 "ON" 0 "OFF" ;
VAL_ 950 ac_acStatus 1 "ON" 0 "OFF" ;
VAL_ 950 ac_driverTempC 63 "Invalid" ;
VAL_ 950 ac_dualStatus 1 "DUAL" 0 "SINGLE" ;
VAL_ 950 ac_frontDefrostStatus 1 "FRONT_DEFROST" 0 "OFF" ;
VAL_ 950 ac_recircStatus 1 "INTERNAL" 0 "EXTERNAL" ;
VAL_ 950 ac_passengerTempC 63 "Invalid" ;
VAL_ 950 ac_driverTempF 63 "Invalid" ;
VAL_ 950 ac_passengerTempF 63 "Invalid" ;
VAL_ 950 ac_modeStatus 7 "INVALID" 4 "DEFROST" 3 "FOOT_AND_DEFROST" 2 "FOOT" 1 "FACE_AND_FOOT" 0 "FACE" ;
VAL_ 950 ac_blowerLvStatus 7 "SPEED_7" 6 "SPEED_6" 5 "SPEED_5" 4 "SPEED_4" 3 "SPEED_3" 2 "SPEED_2" 1 "SPEED_1" 0 "OFF" ;
VAL_ 950 ac_diagInfo 17 "OUT_OF_CAN_NETWORK" 16 "NETWORK_BREAK_WITH_AQS" 15 "NETWORK_BREAK_WITH_PTC" 14 "MIXR_STEPPER_BROKE" 13 "MIXL_STEPPER_BROKE" 12 "MODE_STEPPER_BROKE" 11 "REC_STEPPER_BROKE" 10 "BLOWER_BROKE" 9 "RIGHT_FACE_SENSOR_BROKE" 8 "RIGHT_FOOT_SENSOR_BROKE" 7 "LEFT_FACE_SENSOR_BROKE" 6 "LEFT_FOOT_SENSOR_BROKE" 5 "INCAR_SENSOR_BROKE" 4 "AMB_SENSOR_BROKE" 3 "LOW_PT_SENSOR_BROKE" 2 "HIGH_PT_SENSOR_BROKE" 1 "EVAP_SENSOR_BROKE" 0 "NORMAL" ;
VAL_ 529 bcm_ElVent1ErrorStatus 1 "ERROR" 0 "NO ERROR" ;
VAL_ 529 bcm_ElVent1OverHeatStatus 3 "INVALID" 2 "RESERVED" 1 "OVER HEAT" 0 "NO OVER HEAT" ;
VAL_ 529 bcm_ElVent1ElectricalFailureSts 3 "INVALID" 2 "PERSISTENT ELECTRICAL FAILURE EXIST" 1 "ELECTRICAL FAILURE EXIST" 0 "NO ERROR" ;
VAL_ 529 bcm_ElVent1VoltageStatus 3 "INVALID" 2 "OVER VOLTAGE" 1 "LOW VOLTAGE" 0 "NORMAL VOLTAGE" ;
VAL_ 529 bcm_ElVent1EmergencyRunningSts 3 "INVALID" 2 "RESERVED" 1 "EMERGENCY RUNNING" 0 "NO EMERGENCY RUNNING OCCUR" ;
VAL_ 529 bcm_ElVent1ObstructionDetect 3 "INVALID" 2 "RESERVED" 1 "CLOSED" 0 "OBSTRUCTION" ;
VAL_ 529 bcm_ElVent1ObstructionStatus 3 "INVALID" 2 "RESERVED" 1 "OBSTRUCTION DETECTED" 0 "NO OBSTRUCTION" ;
VAL_ 529 bcm_ElVent1ResetStatus 3 "INVALID" 2 "RESERVED" 1 "RESET" 0 "NO RESET" ;
VAL_ 529 bcm_ElVent1CoilStatus 3 "INVALID" 2 "RESERVED" 1 "COIL UNOBSTRUCTION" 0 "COIL OBSTRUCTION" ;
VAL_ 529 bcm_ElVent1LocationStatus 3 "INVALID" 2 "NO DEFAULT SIGNIFICANT BIT" 1 "ORIGINAL LOCATION VALID" 0 "TARGET LOCATION VALID" ;
VAL_ 529 bcm_ElVent1SpeedStatus 15 "INVALID" 5 "AUTO CHANGE SPEED" 4 "SPEED4" 3 "SPEED3" 2 "SPEED 2" 1 "SPEED 1" 0 "RESERVED" ;
VAL_ 529 bcm_ElVent1MotorCurrentLocation 65535 "Invalid" ;
VAL_ 529 bcm_ElVent1MotorDrivingDirection 3 "INVALID" 2 "INITIALIZATION" 1 "LARGE PROCESS LOCATION" 0 "SMALL PROCESS LOCATION" ;
VAL_ 529 bcm_ElVent1TorqueKeepingSts 3 "INVALID" 2 "RESERVED" 1 "SELF SUSTAINING TURQUE" 0 "NO SELF SUSTAINING TURQUE" ;
VAL_ 529 bcm_ElVent1SpecialFunction 3 "INVALID" 2 "RESERVED" 1 "SPECIAL FUNCTION" 0 "NO SPECIAL FUNCTION" ;
VAL_ 529 bcm_ElVent1LocationActuator 255 "Invalid" ;
VAL_ 529 bcm_ElVent1EmengencyStopSwitchSt 3 "INVALID" 2 "RESERVED" 1 "OPEN EMERGENCY RUNNING" 0 "STOP EMERGENCY RUNNING" ;
VAL_ 529 bcm_ElVent1EmengencyStopSLocatio 3 "INVALID" 2 "RESERVED" 1 "TOP BRAKE" 0 "BOTTOM BRAKE" ;
VAL_ 529 bcm_ElVent1RotationMode 3 "INVALID" 2 "RESERVED" 1 "MOVE ON CCW DIRECTION" 0 "MOVE ON CW DIRECTION" ;
VAL_ 529 bcm_ElVent1StopStatus 3 "INVALID" 2 "RESERVED" 1 "STOP MODE" 0 "NORMAL MODE" ;
VAL_ 545 bcm_ElVent2ErrorStatus 1 "ERROR" 0 "NO ERROR" ;
VAL_ 545 bcm_ElVent2OverHeatStatus 3 "INVALID" 2 "RESERVED" 1 "OVER HEAT" 0 "NO OVER HEAT" ;
VAL_ 545 bcm_ElVent2ElectricalFailureSts 3 "INVALID" 2 "PERSISTENT ELECTRICAL FAILURE EXIST" 1 "ELECTRICAL FAILURE EXIST" 0 "NO ERROR" ;
VAL_ 545 bcm_ElVent2VoltageStatus 3 "INVALID" 2 "OVER VOLTAGE" 1 "LOW VOLTAGE" 0 "NORMAL VOLTAGE" ;
VAL_ 545 bcm_ElVent2EmergencyRunningSts 3 "INVALID" 2 "RESERVED" 1 "EMERGENCY RUNNING" 0 "NO EMERGENCY RUNNING OCCUR" ;
VAL_ 545 bcm_ElVent2ObstructionDetect 3 "INVALID" 2 "RESERVED" 1 "CLOSED" 0 "OBSTRUCTION" ;
VAL_ 545 bcm_ElVent2ObstructionStatus 3 "INVALID" 2 "RESERVED" 1 "OBSTRUCTION DETECTED" 0 "NO OBSTRUCTION" ;
VAL_ 545 bcm_ElVent2ResetStatus 3 "INVALID" 2 "RESERVED" 1 "RESET" 0 "NO RESET" ;
VAL_ 545 bcm_ElVent2CoilStatus 3 "INVALID" 2 "RESERVED" 1 "COIL UNOBSTRUCTION" 0 "COIL OBSTRUCTION" ;
VAL_ 545 bcm_ElVent2LocationStatus 3 "INVALID" 2 "NO DEFAULT SIGNIFICANT BIT" 1 "ORIGINAL LOCATION VALID" 0 "TARGET LOCATION VALID" ;
VAL_ 545 bcm_ElVent2SpeedStatus 15 "INVALID" 5 "AUTO CHANGE SPEED" 4 "SPEED4" 3 "SPEED3" 2 "SPEED 2" 1 "SPEED 1" 0 "RESERVED" ;
VAL_ 545 bcm_ElVent2MotorCurrentLocation 65535 "Invalid" ;
VAL_ 545 bcm_ElVent2MotorDrivingDirection 3 "INVALID" 2 "INITIALIZATION" 1 "LARGE PROCESS LOCATION" 0 "SMALL PROCESS LOCATION" ;
VAL_ 545 bcm_ElVent2TorqueKeepingSts 3 "INVALID" 2 "RESERVED" 1 "SELF SUSTAINING TURQUE" 0 "NO SELF SUSTAINING TURQUE" ;
VAL_ 545 bcm_ElVent2SpecialFunction 3 "INVALID" 2 "RESERVED" 1 "SPECIAL FUNCTION" 0 "NO SPECIAL FUNCTION" ;
VAL_ 545 bcm_ElVent2LocationActuator 255 "Invalid" ;
VAL_ 545 bcm_ElVent2EmengencyStopSwitchSt 3 "INVALID" 2 "RESERVED" 1 "OPEN EMERGENCY RUNNING" 0 "STOP EMERGENCY RUNNING" ;
VAL_ 545 bcm_ElVent2EmengencyStopSLocatio 3 "INVALID" 2 "RESERVED" 1 "TOP BRAKE" 0 "BOTTOM BRAKE" ;
VAL_ 545 bcm_ElVent2RotationMode 3 "INVALID" 2 "RESERVED" 1 "MOVE ON CCW DIRECTION" 0 "MOVE ON CW DIRECTION" ;
VAL_ 545 bcm_ElVent2StopStatus 3 "INVALID" 2 "RESERVED" 1 "STOP MODE" 0 "NORMAL MODE" ;
VAL_ 561 bcm_ElVent3ErrorStatus 1 "ERROR" 0 "NO ERROR" ;
VAL_ 561 bcm_ElVent3OverHeatStatus 3 "INVALID" 2 "RESERVED" 1 "OVER HEAT" 0 "NO OVER HEAT" ;
VAL_ 561 bcm_ElVent3ElectricalFailureSts 3 "INVALID" 2 "PERSISTENT ELECTRICAL FAILURE EXIST" 1 "ELECTRICAL FAILURE EXIST" 0 "NO ERROR" ;
VAL_ 561 bcm_ElVent3VoltageStatus 3 "INVALID" 2 "OVER VOLTAGE" 1 "LOW VOLTAGE" 0 "NORMAL VOLTAGE" ;
VAL_ 561 bcm_ElVent3EmergencyRunningSts 3 "INVALID" 2 "RESERVED" 1 "EMERGENCY RUNNING" 0 "NO EMERGENCY RUNNING OCCUR" ;
VAL_ 561 bcm_ElVent3ObstructionDetect 3 "INVALID" 2 "RESERVED" 1 "CLOSED" 0 "OBSTRUCTION" ;
VAL_ 561 bcm_ElVent3ObstructionStatus 3 "INVALID" 2 "RESERVED" 1 "OBSTRUCTION DETECTED" 0 "NO OBSTRUCTION" ;
VAL_ 561 bcm_ElVent3ResetStatus 3 "INVALID" 2 "RESERVED" 1 "RESET" 0 "NO RESET" ;
VAL_ 561 bcm_ElVent3CoilStatus 3 "INVALID" 2 "RESERVED" 1 "COIL UNOBSTRUCTION" 0 "COIL OBSTRUCTION" ;
VAL_ 561 bcm_ElVent3LocationStatus 3 "INVALID" 2 "NO DEFAULT SIGNIFICANT BIT" 1 "ORIGINAL LOCATION VALID" 0 "TARGET LOCATION VALID" ;
VAL_ 561 bcm_ElVent3SpeedStatus 15 "INVALID" 5 "AUTO CHANGE SPEED" 4 "SPEED4" 3 "SPEED3" 2 "SPEED 2" 1 "SPEED 1" 0 "RESERVED" ;
VAL_ 561 bcm_ElVent3MotorCurrentLocation 65535 "Invalid" ;
VAL_ 561 bcm_ElVent3MotorDrivingDirection 3 "INVALID" 2 "INITIALIZATION" 1 "LARGE PROCESS LOCATION" 0 "SMALL PROCESS LOCATION" ;
VAL_ 561 bcm_ElVent3TorqueKeepingSts 3 "INVALID" 2 "RESERVED" 1 "SELF SUSTAINING TURQUE" 0 "NO SELF SUSTAINING TURQUE" ;
VAL_ 561 bcm_ElVent3SpecialFunction 3 "INVALID" 2 "RESERVED" 1 "SPECIAL FUNCTION" 0 "NO SPECIAL FUNCTION" ;
VAL_ 561 bcm_ElVent3LocationActuator 255 "Invalid" ;
VAL_ 561 bcm_ElVent3EmengencyStopSwitchSt 3 "INVALID" 2 "RESERVED" 1 "OPEN EMERGENCY RUNNING" 0 "STOP EMERGENCY RUNNING" ;
VAL_ 561 bcm_ElVent3EmengencyStopSLocatio 3 "INVALID" 2 "RESERVED" 1 "TOP BRAKE" 0 "BOTTOM BRAKE" ;
VAL_ 561 bcm_ElVent3RotationMode 3 "INVALID" 2 "RESERVED" 1 "MOVE ON CCW DIRECTION" 0 "MOVE ON CW DIRECTION" ;
VAL_ 561 bcm_ElVent3StopStatus 3 "INVALID" 2 "RESERVED" 1 "STOP MODE" 0 "NORMAL MODE" ;
VAL_ 577 bcm_ElVent4ErrorStatus 1 "ERROR" 0 "NO ERROR" ;
VAL_ 577 bcm_ElVent4OverHeatStatus 3 "INVALID" 2 "RESERVED" 1 "OVER HEAT" 0 "NO OVER HEAT" ;
VAL_ 577 bcm_ElVent4ElectricalFailureSts 3 "INVALID" 2 "PERSISTENT ELECTRICAL FAILURE EXIST" 1 "ELECTRICAL FAILURE EXIST" 0 "NO ERROR" ;
VAL_ 577 bcm_ElVent4VoltageStatus 3 "INVALID" 2 "OVER VOLTAGE" 1 "LOW VOLTAGE" 0 "NORMAL VOLTAGE" ;
VAL_ 577 bcm_ElVent4EmergencyRunningSts 3 "INVALID" 2 "RESERVED" 1 "EMERGENCY RUNNING" 0 "NO EMERGENCY RUNNING OCCUR" ;
VAL_ 577 bcm_ElVent4ObstructionDetect 3 "INVALID" 2 "RESERVED" 1 "CLOSED" 0 "OBSTRUCTION" ;
VAL_ 577 bcm_ElVent4ObstructionStatus 3 "INVALID" 2 "RESERVED" 1 "OBSTRUCTION DETECTED" 0 "NO OBSTRUCTION" ;
VAL_ 577 bcm_ElVent4ResetStatus 3 "INVALID" 2 "RESERVED" 1 "RESET" 0 "NO RESET" ;
VAL_ 577 bcm_ElVent4CoilStatus 3 "INVALID" 2 "RESERVED" 1 "COIL UNOBSTRUCTION" 0 "COIL OBSTRUCTION" ;
VAL_ 577 bcm_ElVent4LocationStatus 3 "INVALID" 2 "NO DEFAULT SIGNIFICANT BIT" 1 "ORIGINAL LOCATION VALID" 0 "TARGET LOCATION VALID" ;
VAL_ 577 bcm_ElVent4SpeedStatus 15 "INVALID" 5 "AUTO CHANGE SPEED" 4 "SPEED4" 3 "SPEED3" 2 "SPEED 2" 1 "SPEED 1" 0 "RESERVED" ;
VAL_ 577 bcm_ElVent4MotorCurrentLocation 65535 "Invalid" ;
VAL_ 577 bcm_ElVent4MotorDrivingDirection 3 "INVALID" 2 "INITIALIZATION" 1 "LARGE PROCESS LOCATION" 0 "SMALL PROCESS LOCATION" ;
VAL_ 577 bcm_ElVent4TorqueKeepingSts 3 "INVALID" 2 "RESERVED" 1 "SELF SUSTAINING TURQUE" 0 "NO SELF SUSTAINING TURQUE" ;
VAL_ 577 bcm_ElVent4SpecialFunction 3 "INVALID" 2 "RESERVED" 1 "SPECIAL FUNCTION" 0 "NO SPECIAL FUNCTION" ;
VAL_ 577 bcm_ElVent4LocationActuator 255 "Invalid" ;
VAL_ 577 bcm_ElVent4EmengencyStopSwitchSt 3 "INVALID" 2 "RESERVED" 1 "OPEN EMERGENCY RUNNING" 0 "STOP EMERGENCY RUNNING" ;
VAL_ 577 bcm_ElVent4EmengencyStopSLocatio 3 "INVALID" 2 "RESERVED" 1 "TOP BRAKE" 0 "BOTTOM BRAKE" ;
VAL_ 577 bcm_ElVent4RotationMode 3 "INVALID" 2 "RESERVED" 1 "MOVE ON CCW DIRECTION" 0 "MOVE ON CW DIRECTION" ;
VAL_ 577 bcm_ElVent4StopStatus 3 "INVALID" 2 "RESERVED" 1 "STOP MODE" 0 "NORMAL MODE" ;
VAL_ 593 bcm_ElVent5ErrorStatus 1 "ERROR" 0 "NO ERROR" ;
VAL_ 593 bcm_ElVent5OverHeatStatus 3 "INVALID" 2 "RESERVED" 1 "OVER HEAT" 0 "NO OVER HEAT" ;
VAL_ 593 bcm_ElVent5ElectricalFailureSts 3 "INVALID" 2 "PERSISTENT ELECTRICAL FAILURE EXIST" 1 "ELECTRICAL FAILURE EXIST" 0 "NO ERROR" ;
VAL_ 593 bcm_ElVent5VoltageStatus 3 "INVALID" 2 "OVER VOLTAGE" 1 "LOW VOLTAGE" 0 "NORMAL VOLTAGE" ;
VAL_ 593 bcm_ElVent5EmergencyRunningSts 3 "INVALID" 2 "RESERVED" 1 "EMERGENCY RUNNING" 0 "NO EMERGENCY RUNNING OCCUR" ;
VAL_ 593 bcm_ElVent5ObstructionDetect 3 "INVALID" 2 "RESERVED" 1 "CLOSED" 0 "OBSTRUCTION" ;
VAL_ 593 bcm_ElVent5ObstructionStatus 3 "INVALID" 2 "RESERVED" 1 "OBSTRUCTION DETECTED" 0 "NO OBSTRUCTION" ;
VAL_ 593 bcm_ElVent5ResetStatus 3 "INVALID" 2 "RESERVED" 1 "RESET" 0 "NO RESET" ;
VAL_ 593 bcm_ElVent5CoilStatus 3 "INVALID" 2 "RESERVED" 1 "COIL UNOBSTRUCTION" 0 "COIL OBSTRUCTION" ;
VAL_ 593 bcm_ElVent5LocationStatus 3 "INVALID" 2 "NO DEFAULT SIGNIFICANT BIT" 1 "ORIGINAL LOCATION VALID" 0 "TARGET LOCATION VALID" ;
VAL_ 593 bcm_ElVent5SpeedStatus 15 "INVALID" 5 "AUTO CHANGE SPEED" 4 "SPEED4" 3 "SPEED3" 2 "SPEED 2" 1 "SPEED 1" 0 "RESERVED" ;
VAL_ 593 bcm_ElVent5MotorCurrentLocation 65535 "Invalid" ;
VAL_ 593 bcm_ElVent5MotorDrivingDirection 3 "INVALID" 2 "INITIALIZATION" 1 "LARGE PROCESS LOCATION" 0 "SMALL PROCESS LOCATION" ;
VAL_ 593 bcm_ElVent5TorqueKeepingSts 3 "INVALID" 2 "RESERVED" 1 "SELF SUSTAINING TURQUE" 0 "NO SELF SUSTAINING TURQUE" ;
VAL_ 593 bcm_ElVent5SpecialFunction 3 "INVALID" 2 "RESERVED" 1 "SPECIAL FUNCTION" 0 "NO SPECIAL FUNCTION" ;
VAL_ 593 bcm_ElVent5LocationActuator 255 "Invalid" ;
VAL_ 593 bcm_ElVent5EmengencyStopSwitchSt 3 "INVALID" 2 "RESERVED" 1 "OPEN EMERGENCY RUNNING" 0 "STOP EMERGENCY RUNNING" ;
VAL_ 593 bcm_ElVent5EmengencyStopSLocatio 3 "INVALID" 2 "RESERVED" 1 "TOP BRAKE" 0 "BOTTOM BRAKE" ;
VAL_ 593 bcm_ElVent5RotationMode 3 "INVALID" 2 "RESERVED" 1 "MOVE ON CCW DIRECTION" 0 "MOVE ON CW DIRECTION" ;
VAL_ 593 bcm_ElVent5StopStatus 3 "INVALID" 2 "RESERVED" 1 "STOP MODE" 0 "NORMAL MODE" ;
VAL_ 609 bcm_ElVent6ErrorStatus 1 "ERROR" 0 "NO ERROR" ;
VAL_ 609 bcm_ElVent6OverHeatStatus 3 "INVALID" 2 "RESERVED" 1 "OVER HEAT" 0 "NO OVER HEAT" ;
VAL_ 609 bcm_ElVent6ElectricalFailureSts 3 "INVALID" 2 "PERSISTENT ELECTRICAL FAILURE EXIST" 1 "ELECTRICAL FAILURE EXIST" 0 "NO ERROR" ;
VAL_ 609 bcm_ElVent6VoltageStatus 3 "INVALID" 2 "OVER VOLTAGE" 1 "LOW VOLTAGE" 0 "NORMAL VOLTAGE" ;
VAL_ 609 bcm_ElVent6EmergencyRunningSts 3 "INVALID" 2 "RESERVED" 1 "EMERGENCY RUNNING" 0 "NO EMERGENCY RUNNING OCCUR" ;
VAL_ 609 bcm_ElVent6ObstructionDetect 3 "INVALID" 2 "RESERVED" 1 "CLOSED" 0 "OBSTRUCTION" ;
VAL_ 609 bcm_ElVent6ObstructionStatus 3 "INVALID" 2 "RESERVED" 1 "OBSTRUCTION DETECTED" 0 "NO OBSTRUCTION" ;
VAL_ 609 bcm_ElVent6ResetStatus 3 "INVALID" 2 "RESERVED" 1 "RESET" 0 "NO RESET" ;
VAL_ 609 bcm_ElVent6CoilStatus 3 "INVALID" 2 "RESERVED" 1 "COIL UNOBSTRUCTION" 0 "COIL OBSTRUCTION" ;
VAL_ 609 bcm_ElVent6LocationStatus 3 "INVALID" 2 "NO DEFAULT SIGNIFICANT BIT" 1 "ORIGINAL LOCATION VALID" 0 "TARGET LOCATION VALID" ;
VAL_ 609 bcm_ElVent6SpeedStatus 15 "INVALID" 5 "AUTO CHANGE SPEED" 4 "SPEED4" 3 "SPEED3" 2 "SPEED 2" 1 "SPEED 1" 0 "RESERVED" ;
VAL_ 609 bcm_ElVent6MotorCurrentLocation 65535 "Invalid" ;
VAL_ 609 bcm_ElVent6MotorDrivingDirection 3 "INVALID" 2 "INITIALIZATION" 1 "LARGE PROCESS LOCATION" 0 "SMALL PROCESS LOCATION" ;
VAL_ 609 bcm_ElVent6TorqueKeepingSts 3 "INVALID" 2 "RESERVED" 1 "SELF SUSTAINING TURQUE" 0 "NO SELF SUSTAINING TURQUE" ;
VAL_ 609 bcm_ElVent6SpecialFunction 3 "INVALID" 2 "RESERVED" 1 "SPECIAL FUNCTION" 0 "NO SPECIAL FUNCTION" ;
VAL_ 609 bcm_ElVent6LocationActuator 255 "Invalid" ;
VAL_ 609 bcm_ElVent6EmengencyStopSwitchSt 3 "INVALID" 2 "RESERVED" 1 "OPEN EMERGENCY RUNNING" 0 "STOP EMERGENCY RUNNING" ;
VAL_ 609 bcm_ElVent6EmengencyStopSLocatio 3 "INVALID" 2 "RESERVED" 1 "TOP BRAKE" 0 "BOTTOM BRAKE" ;
VAL_ 609 bcm_ElVent6RotationMode 3 "INVALID" 2 "RESERVED" 1 "MOVE ON CCW DIRECTION" 0 "MOVE ON CW DIRECTION" ;
VAL_ 609 bcm_ElVent6StopStatus 3 "INVALID" 2 "RESERVED" 1 "STOP MODE" 0 "NORMAL MODE" ;
VAL_ 625 bcm_ElVent7ErrorStatus 1 "ERROR" 0 "NO ERROR" ;
VAL_ 625 bcm_ElVent7OverHeatStatus 3 "INVALID" 2 "RESERVED" 1 "OVER HEAT" 0 "NO OVER HEAT" ;
VAL_ 625 bcm_ElVent7ElectricalFailureSts 3 "INVALID" 2 "PERSISTENT ELECTRICAL FAILURE EXIST" 1 "ELECTRICAL FAILURE EXIST" 0 "NO ERROR" ;
VAL_ 625 bcm_ElVent7VoltageStatus 3 "INVALID" 2 "OVER VOLTAGE" 1 "LOW VOLTAGE" 0 "NORMAL VOLTAGE" ;
VAL_ 625 bcm_ElVent7EmergencyRunningSts 3 "INVALID" 2 "RESERVED" 1 "EMERGENCY RUNNING" 0 "NO EMERGENCY RUNNING OCCUR" ;
VAL_ 625 bcm_ElVent7ObstructionDetect 3 "INVALID" 2 "RESERVED" 1 "CLOSED" 0 "OBSTRUCTION" ;
VAL_ 625 bcm_ElVent7ObstructionStatus 3 "INVALID" 2 "RESERVED" 1 "OBSTRUCTION DETECTED" 0 "NO OBSTRUCTION" ;
VAL_ 625 bcm_ElVent7ResetStatus 3 "INVALID" 2 "RESERVED" 1 "RESET" 0 "NO RESET" ;
VAL_ 625 bcm_ElVent7CoilStatus 3 "INVALID" 2 "RESERVED" 1 "COIL UNOBSTRUCTION" 0 "COIL OBSTRUCTION" ;
VAL_ 625 bcm_ElVent7LocationStatus 3 "INVALID" 2 "NO DEFAULT SIGNIFICANT BIT" 1 "ORIGINAL LOCATION VALID" 0 "TARGET LOCATION VALID" ;
VAL_ 625 bcm_ElVent7SpeedStatus 15 "INVALID" 5 "AUTO CHANGE SPEED" 4 "SPEED4" 3 "SPEED3" 2 "SPEED 2" 1 "SPEED 1" 0 "RESERVED" ;
VAL_ 625 bcm_ElVent7MotorCurrentLocation 65535 "Invalid" ;
VAL_ 625 bcm_ElVent7MotorDrivingDirection 3 "INVALID" 2 "INITIALIZATION" 1 "LARGE PROCESS LOCATION" 0 "SMALL PROCESS LOCATION" ;
VAL_ 625 bcm_ElVent7TorqueKeepingSts 3 "INVALID" 2 "RESERVED" 1 "SELF SUSTAINING TURQUE" 0 "NO SELF SUSTAINING TURQUE" ;
VAL_ 625 bcm_ElVent7SpecialFunction 3 "INVALID" 2 "RESERVED" 1 "SPECIAL FUNCTION" 0 "NO SPECIAL FUNCTION" ;
VAL_ 625 bcm_ElVent7LocationActuator 255 "Invalid" ;
VAL_ 625 bcm_ElVent7EmengencyStopSwitchSt 3 "INVALID" 2 "RESERVED" 1 "OPEN EMERGENCY RUNNING" 0 "STOP EMERGENCY RUNNING" ;
VAL_ 625 bcm_ElVent7EmengencyStopSLocatio 3 "INVALID" 2 "RESERVED" 1 "TOP BRAKE" 0 "BOTTOM BRAKE" ;
VAL_ 625 bcm_ElVent7RotationMode 3 "INVALID" 2 "RESERVED" 1 "MOVE ON CCW DIRECTION" 0 "MOVE ON CW DIRECTION" ;
VAL_ 625 bcm_ElVent7StopStatus 3 "INVALID" 2 "RESERVED" 1 "STOP MODE" 0 "NORMAL MODE" ;
VAL_ 641 bcm_ElVent8ErrorStatus 1 "ERROR" 0 "NO ERROR" ;
VAL_ 641 bcm_ElVent8OverHeatStatus 3 "INVALID" 2 "RESERVED" 1 "OVER HEAT" 0 "NO OVER HEAT" ;
VAL_ 641 bcm_ElVent8ElectricalFailureSts 3 "INVALID" 2 "PERSISTENT ELECTRICAL FAILURE EXIST" 1 "ELECTRICAL FAILURE EXIST" 0 "NO ERROR" ;
VAL_ 641 bcm_ElVent8VoltageStatus 3 "INVALID" 2 "OVER VOLTAGE" 1 "LOW VOLTAGE" 0 "NORMAL VOLTAGE" ;
VAL_ 641 bcm_ElVent8EmergencyRunningSts 3 "INVALID" 2 "RESERVED" 1 "EMERGENCY RUNNING" 0 "NO EMERGENCY RUNNING OCCUR" ;
VAL_ 641 bcm_ElVent8ObstructionDetect 3 "INVALID" 2 "RESERVED" 1 "CLOSED" 0 "OBSTRUCTION" ;
VAL_ 641 bcm_ElVent8ObstructionStatus 3 "INVALID" 2 "RESERVED" 1 "OBSTRUCTION DETECTED" 0 "NO OBSTRUCTION" ;
VAL_ 641 bcm_ElVent8ResetStatus 3 "INVALID" 2 "RESERVED" 1 "RESET" 0 "NO RESET" ;
VAL_ 641 bcm_ElVent8CoilStatus 3 "INVALID" 2 "RESERVED" 1 "COIL UNOBSTRUCTION" 0 "COIL OBSTRUCTION" ;
VAL_ 641 bcm_ElVent8LocationStatus 3 "INVALID" 2 "NO DEFAULT SIGNIFICANT BIT" 1 "ORIGINAL LOCATION VALID" 0 "TARGET LOCATION VALID" ;
VAL_ 641 bcm_ElVent8SpeedStatus 15 "INVALID" 5 "AUTO CHANGE SPEED" 4 "SPEED4" 3 "SPEED3" 2 "SPEED 2" 1 "SPEED 1" 0 "RESERVED" ;
VAL_ 641 bcm_ElVent8MotorCurrentLocation 65535 "Invalid" ;
VAL_ 641 bcm_ElVent8MotorDrivingDirection 3 "INVALID" 2 "INITIALIZATION" 1 "LARGE PROCESS LOCATION" 0 "SMALL PROCESS LOCATION" ;
VAL_ 641 bcm_ElVent8TorqueKeepingSts 3 "INVALID" 2 "RESERVED" 1 "SELF SUSTAINING TURQUE" 0 "NO SELF SUSTAINING TURQUE" ;
VAL_ 641 bcm_ElVent8SpecialFunction 3 "INVALID" 2 "RESERVED" 1 "SPECIAL FUNCTION" 0 "NO SPECIAL FUNCTION" ;
VAL_ 641 bcm_ElVent8LocationActuator 255 "Invalid" ;
VAL_ 641 bcm_ElVent8EmengencyStopSwitchSt 3 "INVALID" 2 "RESERVED" 1 "OPEN EMERGENCY RUNNING" 0 "STOP EMERGENCY RUNNING" ;
VAL_ 641 bcm_ElVent8EmengencyStopSLocatio 3 "INVALID" 2 "RESERVED" 1 "TOP BRAKE" 0 "BOTTOM BRAKE" ;
VAL_ 641 bcm_ElVent8RotationMode 3 "INVALID" 2 "RESERVED" 1 "MOVE ON CCW DIRECTION" 0 "MOVE ON CW DIRECTION" ;
VAL_ 641 bcm_ElVent8StopStatus 3 "INVALID" 2 "RESERVED" 1 "STOP MODE" 0 "NORMAL MODE" ;
VAL_ 977 bcm_rsm_FwBrightness 2047 "Invalid" ;
VAL_ 977 bcm_rsm_IRBrightness 255 "Invalid" ;
VAL_ 1018 hud_onOffSts 1 "ON" 0 "OFF" ;
VAL_ 1018 hud_language 3 "Reserved" 2 "Reserved" 1 "ENGLISH" 0 "CHINESE" ;
VAL_ 1170 ic_tripmeter 32767 "Invalid" ;
VAL_ 1170 ic_maintenanceInd 1 "INDICATION" 0 "NO_INDICATION" ;
VAL_ 1170 ic_fatigueDrivingWarnning 1 "WARNNING" 0 "NO_WARNNING" ;
VAL_ 1170 ic_currentTripmeter 32767 "Invalid" ;
VAL_ 1170 ic_avgSpdTrip 4095 "Invalid" ;
VAL_ 1170 ic_avgSpdCurrentTrip 4095 "Invalid" ;
VAL_ 951 pdc_buzzerAlarmPattern 7 "REAR_BUZZER_ON_AT_1HZ" 6 "REAR_BUZZER_ON_AT_3HZ" 5 "REAR_BUZZER_ON_AT_5HZ" 4 "REAR_BUZZER_ON" 3 "FRONT_BUZZER_ON_AT_2HZ" 2 "FRONT_BUZZER_ON_AT_4HZ" 1 "FRONT_BUZZER_ON" 0 "BUZZER_OFF" ;
VAL_ 951 pdc_modeStatus 7 "INVALID(RESERVED)" 6 "INHIBITED" 5 "SYSTEM_FAILURE" 4 "REAR_ACTIVE" 3 "FRONT_ACTIVE" 2 "FRONT_REAR_ACTIVE" 1 "STANDBY" 0 "OFF" ;
VAL_ 951 pdc_ledIndication 1 "ON" 0 "OFF" ;
VAL_ 951 pdc_voltageAbnormal 1 "FAULT" 0 "NORMAL" ;
VAL_ 951 pdc_distanceFL 7 "RESERVED" 6 "RESERVED" 5 "RESERVED" 4 "RESERVED" 3 "RESERVED" 2 "RANGE_2" 1 "RANGE_1" 0 "NO_DISTANCE" ;
VAL_ 951 pdc_sensorFaultFL 1 "FAULT" 0 "NORMAL" ;
VAL_ 951 pdc_distanceFML 7 "RESERVED" 6 "RESERVED" 5 "RESERVED" 4 "RESERVED" 3 "RANGE_3" 2 "RANGE_2" 1 "RANGE_1" 0 "NO_DISTANCE" ;
VAL_ 951 pdc_sensorFaultFML 1 "FAULT" 0 "NORMAL" ;
VAL_ 951 pdc_distanceFMR 7 "RESERVED" 6 "RESERVED" 5 "RESERVED" 4 "RESERVED" 3 "RANGE_3" 2 "RANGE_2" 1 "RANGE_1" 0 "NO_DISTANCE" ;
VAL_ 951 pdc_sensorFaultFMR 1 "FAULT" 0 "NORMAL" ;
VAL_ 951 pdc_distanceFR 7 "RESERVED" 6 "RESERVED" 5 "RESERVED" 4 "RESERVED" 3 "RANGE_3" 2 "RANGE_2" 1 "RANGE_1" 0 "NO_DISTANCE" ;
VAL_ 951 pdc_sensorFaultFR 1 "FAULT" 0 "NORMAL" ;
VAL_ 951 pdc_distanceRL 7 "RESERVED" 6 "RESERVED" 5 "RESERVED" 4 "RESERVED" 3 "RESERVED" 2 "RANGE_2" 1 "RANGE_1" 0 "NO_DISTANCE" ;
VAL_ 951 pdc_sensorFaultRL 1 "FAULT" 0 "NORMAL" ;
VAL_ 951 pdc_distanceRML 7 "RESERVED" 6 "RESERVED" 5 "RESERVED" 4 "RANGE_4" 3 "RANGE_3" 2 "RANGE_2" 1 "RANGE_1" 0 "NO_DISTANCE" ;
VAL_ 951 pdc_sensorFaultRML 1 "FAULT" 0 "NORMAL" ;
VAL_ 951 pdc_distanceRMR 7 "RESERVED" 6 "RESERVED" 5 "RESERVED" 4 "RANGE_4" 3 "RANGE_3" 2 "RANGE_2" 1 "RANGE_1" 0 "NO_DISTANCE" ;
VAL_ 951 pdc_sensorFaultRMR 1 "FAULT" 0 "NORMAL" ;
VAL_ 951 pdc_distanceRR 7 "RESERVED" 6 "RESERVED" 5 "RESERVED" 4 "RESERVED" 3 "RESERVED" 2 "RANGE_2" 1 "RANGE_1" 0 "NO_DISTANCE" ;
VAL_ 951 pdc_sensorFaultRR 1 "FAULT" 0 "NORMAL" ;
VAL_ 951 pdc_configInfo 6 "FRONT4_REAR4" 5 "FRONT2_REAR4" 4 "FRONT0_REAR4" 3 "FRONT2_REAR3" 2 "FRONT0_REAR3" 1 "RADAR_NOT_PRESENT" 0 "NOT_USED" ;
VAL_ 951 pdc_systemType 2 "HEV" 1 "EV" 0 "NOT_USED" ;
VAL_ 951 pdc_ecuFault 1 "FAULT" 0 "NORMAL" ;
VAL_ 951 pdc_canFault 3 "MSG_TIMEOUT_AND DATA_ABNORMAL" 2 "MSG_DATA_ABNORMAL" 1 "MSG_TIMEOUT" 0 "NORMAL" ;
VAL_ 116 svc_calibrationState 4 "FAILURE" 3 "SUCCESS" 2 "CALIBRATING" 1 "START" 0 "INVALID" ;
VAL_ 1156 svc_cameraMode 15 "RESERVED" 14 "RESERVED" 13 "RESERVED" 12 "RESERVED" 11 "RESERVED" 10 "RESERVED" 9 "RESERVED" 8 "RESERVED" 7 "RESERVED" 6 "RESERVED" 5 "CAMERAMODE5(2D 俯视图 + 3D全景视图)" 4 "CAMERAMODE4(2D 俯视图 + 2D右视图)" 3 "CAMERAMODE3(2D 俯视图 + 2D左视图)" 2 "CAMERAMODE2(2D 俯视图 + 2D后视图)" 1 "CAMERAMODE1(2D 俯视图 + 2D前视图)" 0 "INACTIVE" ;
VAL_ 1156 svc_workMode 2 "ON" 1 "STARTING" 0 "INACTIVE" ;
VAL_ 1156 svc_sysFailureSts 1 "FAULT" 0 "NORMAL" ;
VAL_ 1041 bcm_tpmsLFStatus 7 "LOW_TYRE_PRESSURE" 6 "RAPID_LEAK" 5 "HIGH_TEMP" 4 "HIGH_TYRE_PRESSURE" 3 "LOW_BATT_VOL" 2 "SYS_ERROR" 1 "NORMAL_TPMS" 0 "INITIAL_TPMS" ;
VAL_ 1041 bcm_tpmsRFStatus 7 "LOW_TYRE_PRESSURE" 6 "RAPID_LEAK" 5 "HIGH_TEMP" 4 "HIGH_TYRE_PRESSURE" 3 "LOW_BATT_VOL" 2 "SYS_ERROR" 1 "NORMAL_TPMS" 0 "INITIAL_TPMS" ;
VAL_ 1041 bcm_tpmsLRStatus 7 "LOW_TYRE_PRESSURE" 6 "RAPID_LEAK" 5 "HIGH_TEMP" 4 "HIGH_TYRE_PRESSURE" 3 "LOW_BATT_VOL" 2 "SYS_ERROR" 1 "NORMAL_TPMS" 0 "INITIAL_TPMS" ;
VAL_ 1041 bcm_tpmsRRStatus 7 "LOW_TYRE_PRESSURE" 6 "RAPID_LEAK" 5 "HIGH_TEMP" 4 "HIGH_TYRE_PRESSURE" 3 "LOW_BATT_VOL" 2 "SYS_ERROR" 1 "NORMAL_TPMS" 0 "INITIAL_TPMS" ;
VAL_ 1055 ASC_SuspensionHeightMode 7 "RESERVED" 6 "MAINTENANCE MODE" 5 "RESERVED" 4 "LOE MODE" 3 "NORMAL MODE" 2 "HIGH MODE" 1 "VERY HIGH MODE" 0 "NO MODE" ;
VAL_ 1055 ASC_VehicleUpDownStatus 2 "BODY DROPING" 1 "BODY RISING" 0 "BODY NO MOVEMENT" ;
VAL_ 1055 ASC_MoveModeStatus 2 "MOVEMENT" 1 "AUTO" 0 "COMFORT" ;
VAL_ 1055 ASC_WarningLamp 2 "TROUBLE LIGHT(Always)" 1 "MAINTENANCE MODE INDICATOR(2 Hz)" 0 "No Warning" ;
VAL_ 1055 ASC_SpeedThresholdValue 160 "160 km/h" 80 "80 km/h" ;
VAL_ 1154 ic_languageSts 15 "INVALID" 1 "ENGLISH" 0 "SIMPLIFIED_CHINESE" ;
VAL_ 1154 ic_minSocWarningSts 255 "Invalid" ;
VAL_ 324 eps_sasSteeringAngle 65535 "Invalid" ;
VAL_ 324 eps_sasSteeringAngleValid 1 "VALID" 0 "INVALID" ;
VAL_ 537 mrr_ccFuntionMode 3 "INVALID" 2 "CC(Reserved)" 1 "TJA/ICA" 0 "ACC" ;
VAL_ 538 mpc_laneAssitType 3 "LDW+LKA" 2 "LDW+RDP" 1 "LDW" 0 "NOT_SELECTED" ;
VAL_ 538 mpc_lasSensitivity 3 "INVALID" 2 "HIGH" 1 "NORMAL" 0 "LOW" ;
VAL_ 538 mpc_lasStatus 7 "RESERVE_ADAS2" 6 "RESERVE_ADAS1" 5 "CAMERA_BLOCKED" 4 "FAULT_ADAS" 3 "ACTIVE_ADAS" 2 "STANDBY_ADAS" 1 "OFF_ADAS" 0 "NO_INFOMATION" ;
VAL_ 538 mpc_lasWarningModeSelection 7 "reserved" 6 "reserved" 5 "reserved" 4 "Invalid" 3 "Vision+Voice+Vibration" 2 "Vision+Vibration" 1 "Vision+Voice" 0 "Only Vision" ;
VAL_ 538 mpc_slaStatus 5 "DEFECT" 4 "NAVIGATION_MODE" 3 "VISION_MODE" 2 "FUSION_MODE" 1 "OFF" 0 "NO_INFOMATION" ;
VAL_ 538 mpc_slaSpeedLimit 27 "SPL_130" 26 "SPL_125" 5 "SPL_20" 4 "SPL_15" 3 "SPL_10" 2 "SPL_5" 1 "SPL_CANCELLED" 0 "NO_DISPLAY" ;
VAL_ 538 mpc_slaSpeedLimitUnits 2 "MPH" 1 "KPH" 0 "UNKNOWN" ;
VAL_ 555 mrr_r_ctaWarningReqRight 2 "WARNING_LEVEL2" 0 "NO_WARNING" ;
VAL_ 555 mrr_r_bsdLCAWarningReqRight 2 "WARNING_LEVEL2" 1 "WARNING_LEVEL1" 0 "NO_WARNING" ;
VAL_ 555 mrr_r_displayInfo 8 "BSDLCA_CTA_BLINDNESS" 7 "BSDLCA_CTA_ERROR" 6 "TRAILER_MODE_CTA_NOT_AVAILABLE" 5 "TRAILER_MODE_BSD_LCA_NOT_AVAILABLE" 4 "CTA_OFF" 3 "CTA_ON" 2 "BSDLCA_OFF" 1 "BSDLCA_ON" 0 "NO_DISPLAY" ;
VAL_ 555 mrr_r_bsdLCASts 2 "INVALID" 1 "ON" 0 "OFF" ;
VAL_ 555 mrr_r_ctaSts 3 "INVALID" 1 "ON" 0 "OFF" ;
VAL_ 555 mrr_r_dowSts 3 "INVALID" 1 "ON" 0 "OFF" ;
VAL_ 555 mrr_r_ctaWarningReqLeft 2 "WARNING_LEVEL2" 0 "NO_WARNING" ;
VAL_ 555 mrr_r_bsdLCAWarningReqLeft 2 "WARNING_LEVEL2" 1 "WARNING_LEVEL1" 0 "NO_WARNING" ;
VAL_ 569 mrr_pedeProtOnOffStatus 1 "ON" 0 "OFF" ;
VAL_ 569 mrr_aebOnOffStatus 3 "FAILURE" 2 "RESERVED" 1 "ON" 0 "OFF" ;
VAL_ 569 mrr_PEBSWarning 7 "Reserved" 6 "Reserved" 5 "Breaking  to PED" 4 "Emergency Warning to PED" 3 "Breaking  to car" 2 "Emergency Warning to car" 1 "PreWarning" 0 "NO_WARNING" ;
VAL_ 569 mrr_pcwOnOffStatus 1 "ON" 0 "OFF" ;
VAL_ 673 bcm_hoodSts 1 "OPEN" 0 "CLOSE" ;
VAL_ 673 bcm_leftTurnLampSts 5 "Rear Left Trunk Turn Light Failure" 4 "Rear Left Fender Turn Light Failure" 3 "Front Left Turn Light Failure" 2 "Reserved" 1 "ON" 0 "OFF" ;
VAL_ 673 bcm_rightTurnLampSts 5 "Rear Right Trunk Turn Light Failure" 4 "Rear Right Fender Turn Light Failure" 3 "Front Right Turn Light Failure" 2 "Reserved" 1 "ON" 0 "OFF" ;
VAL_ 673 bcm_doorFLSts 1 "OPEN" 0 "CLOSE" ;
VAL_ 673 bcm_doorFRSts 1 "OPEN" 0 "CLOSE" ;
VAL_ 673 bcm_doorRLSts 1 "OPEN" 0 "CLOSE" ;
VAL_ 673 bcm_doorRRSts 1 "OPEN" 0 "CLOSE" ;
VAL_ 673 bcm_doorFLLockSts 1 "UNLOCK" 0 "LOCK" ;
VAL_ 673 bcm_antiTheftSts 3 "HALF_ARMED" 2 "ALARM" 1 "ARMED" 0 "DISARMED" ;
VAL_ 673 bcm_fuelCapSts 1 "OPEN_FUELCAP" 0 "CLOSE_FUELCAP" ;
VAL_ 673 bcm_chrgCapSts 1 "OPEN" 0 "CLOSE" ;
VAL_ 705 bcm_pepsPowerMode 7 "INVALID_POWERMODE" 6 "RESERVE_POWERMODE3" 5 "RESERVE_POWERMODE2" 4 "RESERVE_POWERMODE1" 3 "RESERVE_POWERMODE" 2 "ON_POWERMODE" 1 "OFF_POWERMODE" 0 "DEFAULT_POWERMODE" ;
VAL_ 705 bcm_pepsKeyNotInCarInd 1 "WARNING" 0 "NO_WARNING" ;
VAL_ 705 bcm_pepsKeySerchFailInd 1 "WARNING" 0 "NO_WARNING" ;
VAL_ 705 bcm_pepsKeyCloserInd 1 "WARNING" 0 "NO_WARNING" ;
VAL_ 705 bcm_pepsFobLowBatWarning 1 "WARNING" 0 "NO_WARNING" ;
VAL_ 705 bcm_pepsPowerRelayErrWarning 1 "WARNING" 0 "NO_WARNING" ;
VAL_ 705 bcm_ChildSafetyLockSts 1 "UNLOCK" 0 "LOCK" ;
VAL_ 705 bcm_esclUnlockFailWarning 1 "WARNING" 0 "NO_WARNING" ;
VAL_ 705 bcm_esclLockFailWarning 1 "WARNING" 0 "NO_WARNING" ;
VAL_ 706 esc_epbStatus 7 "RESERVED_EPB14" 6 "RESERVED_EPB13" 5 "RESERVED_EPB12" 4 "RELEASING" 3 "PARKING" 2 "RELEASED" 1 "PARKED" 0 "DEFAULT" ;
VAL_ 706 esc_epbTextDisplayOnIVI 3 "Parking brake fault" 2 "Please wear your seat belt for releasing the parking" 1 "Press the brake pedal first,then release the EBP button" 0 "OFF" ;
VAL_ 754 ic_totalMileage 16777215 "Invalid" ;
VAL_ 754 ic_themeSts 7 "INVALID" 5 "SPORT" 4 "COMFORT" 3 "COMMON" 2 "ECO" 1 "CROSSLINE_DRIVING" 0 "NONE" ;
VAL_ 878 esc_vehicleSpeed 8191 "Invalid" ;
VAL_ 878 esc_vehicleSpeedValid 1 "VALID" 0 "INVALID" ;
VAL_ 878 esc_avhActive 1 "ACTIVE" 0 "INACTIVE" ;
VAL_ 878 esc_avhStandby 1 "STANDBY" 0 "NOT_STANDBY" ;
VAL_ 878 esc_avhAvailable 1 "AVAILABLE" 0 "NOT_AVAILABLE" ;
VAL_ 878 esc_hdcStatus 2 "STANDBY" 1 "ACTIVE" 0 "NOT_ACTIVE" ;
VAL_ 878 esc_offStatus 1 "ON" 0 "OFF" ;
VAL_ 878 esc_vlcTorqReq 8191 "Invalid" ;
VAL_ 878 esc_vlcTorqReqActive 1 "ACTIVE" 0 "NOT_ACTIVE" ;
VAL_ 878 esc_vlcError 1 "ERROR" 0 "NOT_ERROR" ;
VAL_ 878 esc_vlcAvalible 1 "AVAILABLE" 0 "NOT_AVAILABLE" ;
VAL_ 878 esc_vlcActive 1 "ACTIVE" 0 "INACTIVE" ;
VAL_ 878 eps_modeStatus 3 "INVALID" 2 "SPORT" 1 "COMFORT" 0 "STANDARD" ;
VAL_ 910 vcu_actualGearValid 1 "VALID" 0 "INVALID" ;
VAL_ 910 vcu_actualGear 3 "D" 2 "N" 1 "R" 0 "P" ;
VAL_ 928 vsp_errorStatus 8 "MUTE_STATUS" 4 "SHORT_CIRCUIT_ERROR" 2 "UNDER_VOLT_ERROR" 1 "OVER_VOLT_ERROR" ;
VAL_ 928 vsp_soundEnable 1 "ENABLE" 0 "DISABLE" ;
VAL_ 928 vsp_errorIdentification 1 "ERROR" 0 "NO_ERROR" ;
VAL_ 941 wcm_chargingStatus 3 "FAULT" 2 "CHARGE_FINISHED" 1 "CHARGING" 0 "OFF" ;
VAL_ 941 wcm_failureStatus 5 "OVER POWER FAILURE" 4 "FOREIGN_MATTER_DETECTED" 3 "HIGH_TEMP" 2 "HIGH_VOLT" 1 "LOW_VOLT" 0 "NORMAL" ;
VAL_ 941 wcm_onOffFeedback 2 "ON" 1 "OFF" 0 "INACTIVE" ;
VAL_ 941 wcm_workingStatus 1 "ON" 0 "OFF" ;
VAL_ 941 WCM_selfCheckToWCM 3 "INVALID" 2 "CHECK FAILED" 1 "CHECK COMPLETED" 0 "ON CHECKING" ;
VAL_ 974 ac_ambientTemp 255 "Invalid" ;
VAL_ 974 ac_incarTemp 255 "Invalid" ;
VAL_ 974 ac_cabinPtcStatus 1 "ON" 0 "OFF" ;
VAL_ 974 bcm_rearMirrorSts 1 "UNFOLD" 0 "FOLD" ;
VAL_ 974 bcm_autoLampSwSts 1 "AUTO" 0 "NON_AUTO" ;
VAL_ 974 bcm_positionLampSts 1 "ON" 0 "OFF" ;
VAL_ 974 bcm_lowBeamSts 3 "LOWBEAMFAULT" 1 "ON" 0 "OFF" ;
VAL_ 974 bcm_highBeamSts 3 "LOWBEAMFAULT" 1 "ON" 0 "OFF" ;
VAL_ 974 bcm_sunroofSts 7 "UNINITIALIZED" 6 "FULLY_OPEN" 5 "PARTIALLY_SLIDE" 4 "ANTIPINCH_IN_PARTIALLY_SLIDE" 3 "FULLY_CLOSE" 2 "ANTIPINCH_IN_VENT" 1 "VENT_AREA" 0 "TILT_UP" ;
VAL_ 974 bcm_sunshadeSts 7 "UNINITIALIZED" 6 "FULLY_OPEN" 5 "ANTIPINCH" 4 "HALF_OPEN" 3 "FULLY_CLOSE" 2 "SECOND_HALF_OF_SLIDE" 1 "FIRST_HALF_OF_SLIDE" ;
VAL_ 974 bcm_rearFogLampSts 1 "ON" 0 "OFF" ;
VAL_ 974 bcm_roofLampSts 1 "ON" 0 "OFF" ;
VAL_ 974 bcm_footLampSts 1 "ON" 0 "OFF" ;
VAL_ 974 bcm_ambientLightLumiLvSts 11 "LV10" 10 "LV9" 9 "LV8" 8 "LV7" 7 "LV6" 6 "LV5_NORMAL" 5 "LV4" 4 "LV3" 3 "LV2" 2 "LV1" 1 "LV0" 0 "UNDEFINED" ;
VAL_ 974 bcm_rsmSolarRight 255 "Invalid" ;
VAL_ 974 bcm_rsmSolarLeft 255 "Invalid" ;
VAL_ 990 pot_antipinchWarning 1 "WARNING" 0 "NO_WARNING" ;
VAL_ 990 pot_tailgateOpenSts 5 "CLOSED_NOT_COMPLETELY" 4 "STOPPED" 3 "OPENING" 2 "CLOSING" 1 "OPENED" 0 "CLOSED" ;
VAL_ 990 pot_antiPlayWarning 1 "WARNING" 0 "NO_WARNING" ;
VAL_ 990 dscu_easyEntryStatus 1 "ON" 0 "OFF" ;
VAL_ 990 dscu_drSeatMassSts 7 "ERROR" 3 "LEVEL_3" 2 "LEVEL_2" 1 "LEVEL_1" 0 "OFF" ;
VAL_ 990 dscu_drSeatHeatSts 7 "ERROR" 3 "LEVEL_3" 2 "LEVEL_2" 1 "LEVEL_1" 0 "OFF" ;
VAL_ 990 dscu_keyMemoryStatus 2 "INACTIVE" 1 "ON" 0 "OFF" ;
VAL_ 990 dscu_drSeatVentSts 7 "INVALID" 5 "Level 5" 4 "Level 4" 3 "Level 3" 2 "Level 2" 1 "Level 1" ;
VAL_ 990 dscu_passSeatMassSts 7 "ERROR" 3 "LEVEL_3" 2 "LEVEL_2" 1 "LEVEL_1" 0 "OFF" ;
VAL_ 990 dscu_passSeatHeatSts 7 "ERROR" 3 "LEVEL_3" 2 "LEVEL_2" 1 "LEVEL_1" 0 "OFF" ;
VAL_ 990 dscu_passSeatVentSts 7 "INVALID" 5 "Level 5" 4 "Level 4" 3 "Level 3" 2 "Level 2" 1 "Level 1" ;
VAL_ 990 dscu_DSMStatustOutput 3 "RESERVED" 2 "SUCCESSED" 1 "FAILED" 0 "INVALID" ;
VAL_ 990 dscu_MemoryAlarm 3 "RESERVED" 2 "SUCCESSED" 1 "FAILED" 0 "INVALID" ;
VAL_ 990 dscu_MemoryPosition 7 "RESERVED" 6 "LAST POSITION" 5 "5 POSITION" 4 "4 POSITION" 3 "3 POSITION" 2 "2 POSITION" 1 "1 POSITION" 0 "NOT_MEMORYPOSITION" ;
